[part 8 of 22: package /Cluster]
AUTOSAR XML (schema 4-3-0)
package /Cluster  (continued)
  can cluster E3V_K2CANFD: baudrate=500000, protocol-name=CAN, protocol-version=2.0, bus-off-recovery={bor-counter-l-1-to-l-2=1, bor-time-l-1=0.05, bor-time-l-2=0.2}, can-fd-baudrate=500000  (continued)
    can physical channel CHNL: comm-connectors=CN_E3V_K2CANFD  (continued)
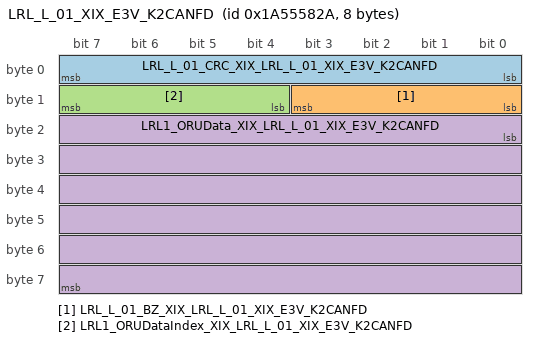
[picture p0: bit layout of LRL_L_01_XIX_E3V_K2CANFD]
      frame LRL_L_01_XIX_E3V_K2CANFD: id 0x1A55582A, to SAM, frame-length=8, can-addressing-mode=EXTENDED, can-frame-rx-behavior=CAN-FD, can-frame-tx-behavior=CAN-FD
        pdu LRL_L_01_XIX_E3V_K2CANFD_E2E: length=8, transmission-mode-true-timing=event-controlled-timing={number-of-repetitions=0, repetition-period=0.0}, unused-bit-pattern=0  # Fuer die Botschaft ist das Cyclic-Timing 0.5 zu verwenden.
          signal LRL_L_01_CRC_XIX_LRL_L_01_XIX_E3V_K2CANFD: start 0, 8 bit, little-endian, data-type-policy=OVERRIDE, i-signal-type=PRIMITIVE, init-value=0, base-type=BT_LRL_L_01_CRC, compu {phys=raw for raw 0..255}, range phys 0..255, raw 0..255, to SAM(timeout 5 s)  # Für MLB: Berechnung siehe Lastenheft "Kommunikationsabsicherung für FlexRay und CAN" Ab MQB und MLBevo: Berechnung siehe Lastenheft "End-to-End Kommunikationsabsicherung" Endwerte siehe Begleitdokument "S-PDU Kennungsfolgen"
          signal LRL_L_01_BZ_XIX_LRL_L_01_XIX_E3V_K2CANFD: start 8, 4 bit, little-endian, data-type-policy=OVERRIDE, i-signal-type=PRIMITIVE, init-value=0, base-type=BT_LRL_L_01_BZ, compu {phys=raw for raw 0..15}, range phys 0..15, raw 0..15, to SAM(timeout 5 s)
          signal LRL1_ORUDataIndex_XIX_LRL_L_01_XIX_E3V_K2CANFD: start 12, 4 bit, little-endian, data-type-policy=OVERRIDE, i-signal-type=PRIMITIVE, init-value=0, base-type=BT_LRL1_ORUDataIndex, compu {phys=raw for raw 0..15}, range phys 0..15, raw 0..15, to SAM(timeout 5 s)  # Data index of the last 6 Bytes
          signal LRL1_ORUData_XIX_LRL_L_01_XIX_E3V_K2CANFD: start 16, 48 bit, little-endian, data-type-policy=OVERRIDE, i-signal-type=PRIMITIVE, init-value=0, base-type=BT_LRL1_ORUData, compu {phys=raw for raw 0..281474976710655}, range phys 0..281474976710655, raw 0..281474976710655, to SAM(timeout 5 s)  # "ORU information multiplexed - diagnostic address (2 bytes) - HW-part no (11 bytes) - HW version no. (3 bytes) - SW version no. (4 bytes) - IVD-P Value (64 bytes) need to be sent in combination with ORUDataIndex"
          mapping SG_LRL_L_01_XIX_E3V_K2CANFD: i-signal-group=SG_LRL_L_01_XIX_E3V_K2CANFD, transfer-property=TRIGGERED-WITHOUT-REPETITION
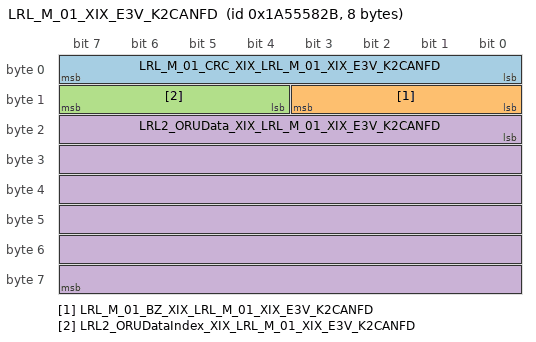
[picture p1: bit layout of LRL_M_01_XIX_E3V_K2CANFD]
      frame LRL_M_01_XIX_E3V_K2CANFD: id 0x1A55582B, to SAM, frame-length=8, can-addressing-mode=EXTENDED, can-frame-rx-behavior=CAN-FD, can-frame-tx-behavior=CAN-FD
        pdu LRL_M_01_XIX_E3V_K2CANFD_E2E: length=8, transmission-mode-true-timing=event-controlled-timing={number-of-repetitions=0, repetition-period=0.0}, unused-bit-pattern=0  # Fuer die Botschaft ist das Cyclic-Timing 0.5 zu verwenden.
          signal LRL_M_01_CRC_XIX_LRL_M_01_XIX_E3V_K2CANFD: start 0, 8 bit, little-endian, data-type-policy=OVERRIDE, i-signal-type=PRIMITIVE, init-value=0, base-type=BT_LRL_M_01_CRC, compu {phys=raw for raw 0..255}, range phys 0..255, raw 0..255, to SAM(timeout 5 s)  # Für MLB: Berechnung siehe Lastenheft "Kommunikationsabsicherung für FlexRay und CAN" Ab MQB und MLBevo: Berechnung siehe Lastenheft "End-to-End Kommunikationsabsicherung" Endwerte siehe Begleitdokument "S-PDU Kennungsfolgen"
          signal LRL_M_01_BZ_XIX_LRL_M_01_XIX_E3V_K2CANFD: start 8, 4 bit, little-endian, data-type-policy=OVERRIDE, i-signal-type=PRIMITIVE, init-value=0, base-type=BT_LRL_M_01_BZ, compu {phys=raw for raw 0..15}, range phys 0..15, raw 0..15, to SAM(timeout 5 s)
          signal LRL2_ORUDataIndex_XIX_LRL_M_01_XIX_E3V_K2CANFD: start 12, 4 bit, little-endian, data-type-policy=OVERRIDE, i-signal-type=PRIMITIVE, init-value=0, base-type=BT_LRL2_ORUDataIndex, compu {phys=raw for raw 0..15}, range phys 0..15, raw 0..15, to SAM(timeout 5 s)  # Data index of the last 6 Bytes
          signal LRL2_ORUData_XIX_LRL_M_01_XIX_E3V_K2CANFD: start 16, 48 bit, little-endian, data-type-policy=OVERRIDE, i-signal-type=PRIMITIVE, init-value=0, base-type=BT_LRL2_ORUData, compu {phys=raw for raw 0..281474976710655}, range phys 0..281474976710655, raw 0..281474976710655, to SAM(timeout 5 s)  # "ORU information multiplexed - diagnostic address (2 bytes) - HW-part no (11 bytes) - HW version no. (3 bytes) - SW version no. (4 bytes) - IVD-P Value (64 bytes) need to be sent in combination with ORUDataIndex"
          mapping SG_LRL_M_01_XIX_E3V_K2CANFD: i-signal-group=SG_LRL_M_01_XIX_E3V_K2CANFD, transfer-property=TRIGGERED-WITHOUT-REPETITION
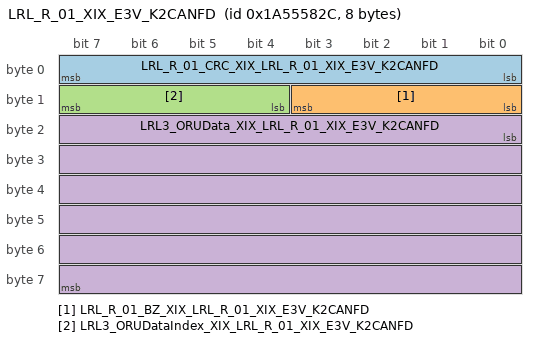
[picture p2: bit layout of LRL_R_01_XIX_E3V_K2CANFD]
      frame LRL_R_01_XIX_E3V_K2CANFD: id 0x1A55582C, to SAM, frame-length=8, can-addressing-mode=EXTENDED, can-frame-rx-behavior=CAN-FD, can-frame-tx-behavior=CAN-FD
        pdu LRL_R_01_XIX_E3V_K2CANFD_E2E: length=8, transmission-mode-true-timing=event-controlled-timing={number-of-repetitions=0, repetition-period=0.0}, unused-bit-pattern=0  # Fuer die Botschaft ist das Cyclic-Timing 0.5 zu verwenden.
          signal LRL_R_01_CRC_XIX_LRL_R_01_XIX_E3V_K2CANFD: start 0, 8 bit, little-endian, data-type-policy=OVERRIDE, i-signal-type=PRIMITIVE, init-value=0, base-type=BT_LRL_R_01_CRC, compu {phys=raw for raw 0..255}, range phys 0..255, raw 0..255, to SAM(timeout 5 s)  # Für MLB: Berechnung siehe Lastenheft "Kommunikationsabsicherung für FlexRay und CAN" Ab MQB und MLBevo: Berechnung siehe Lastenheft "End-to-End Kommunikationsabsicherung" Endwerte siehe Begleitdokument "S-PDU Kennungsfolgen"
          signal LRL_R_01_BZ_XIX_LRL_R_01_XIX_E3V_K2CANFD: start 8, 4 bit, little-endian, data-type-policy=OVERRIDE, i-signal-type=PRIMITIVE, init-value=0, base-type=BT_LRL_R_01_BZ, compu {phys=raw for raw 0..15}, range phys 0..15, raw 0..15, to SAM(timeout 5 s)
          signal LRL3_ORUDataIndex_XIX_LRL_R_01_XIX_E3V_K2CANFD: start 12, 4 bit, little-endian, data-type-policy=OVERRIDE, i-signal-type=PRIMITIVE, init-value=0, base-type=BT_LRL3_ORUDataIndex, compu {phys=raw for raw 0..15}, range phys 0..15, raw 0..15, to SAM(timeout 5 s)  # Data index of the last 6 Bytes
          signal LRL3_ORUData_XIX_LRL_R_01_XIX_E3V_K2CANFD: start 16, 48 bit, little-endian, data-type-policy=OVERRIDE, i-signal-type=PRIMITIVE, init-value=0, base-type=BT_LRL3_ORUData, compu {phys=raw for raw 0..281474976710655}, range phys 0..281474976710655, raw 0..281474976710655, to SAM(timeout 5 s)  # "ORU information multiplexed - diagnostic address (2 bytes) - HW-part no (11 bytes) - HW version no. (3 bytes) - SW version no. (4 bytes) - IVD-P Value (64 bytes) need to be sent in combination with ORUDataIndex"
          mapping SG_LRL_R_01_XIX_E3V_K2CANFD: i-signal-group=SG_LRL_R_01_XIX_E3V_K2CANFD, transfer-property=TRIGGERED-WITHOUT-REPETITION
      frame Mem_BFS_01_XIX_E3V_K2CANFD: id 0x667, to SAM, frame-length=8, can-addressing-mode=STANDARD, can-frame-rx-behavior=CAN-FD, can-frame-tx-behavior=CAN-FD
        pdu Mem_BFS_01_XIX_E3V_K2CANFD: length=8, minimum-delay=0.05, transmission-mode-true-timing={cyclic-timing={time-offset=0.0, time-period=0.1}, event-controlled-timing={number-of-repetitions=0, repetition-period=0.0}}, unused-bit-pattern=0  # MLBevo
          signal BFS_Fond_Bed_Ack_XIX_Mem_BFS_01_XIX_E3V_K2CANFD: start 12, 1 bit, little-endian, data-type-policy=OVERRIDE, i-signal-type=PRIMITIVE, init-value=0, base-type=BT_BFS_Fond_Bed_Ack, compu {0=Cx0_nicht_aktiviert (CM_BFS_Fond_Bed_Ack_Cx0_nicht_aktiviert) (nicht aktiviert), 1=Cx1_aktiviert (CM_BFS_Fond_Bed_Ack_Cx1_aktiviert)}, range raw 0..1, transfer-property=TRIGGERED-ON-CHANGE-WITHOUT-REPETITION  # Bestätigung Beifahrersitzverstellung vom Fond
          signal BFS_Lehne_nicht_verriegelt_XIX_Mem_BFS_01_XIX_E3V_K2CANFD: start 13, 1 bit, little-endian, data-type-policy=OVERRIDE, i-signal-type=PRIMITIVE, init-value=0, base-type=BT_BFS_Lehne_nicht_verriegelt, compu {0=Cx0_keine_Anzeige (CM_BFS_Lehne_nicht_verriegelt_Cx0_keine_Anzeige) (keine Anzeige), 1=Cx1_Lehne_nicht_verriegelt (CM_BFS_Lehne_nicht_verriegelt_Cx1_Lehne_nicht_verriegelt)}, range raw 0..1, transfer-property=TRIGGERED-ON-CHANGE-WITHOUT-REPETITION  # Fahrer Sitz Lehne Verstellung Verriegelt Status Verwendung nur im Bentley
          signal BFS_Klapptisch_offen_XIX_Mem_BFS_01_XIX_E3V_K2CANFD: start 14, 1 bit, little-endian, data-type-policy=OVERRIDE, i-signal-type=PRIMITIVE, init-value=0, base-type=BT_BFS_Klapptisch_offen, compu {0=Cx0_inaktiv (CM_BFS_Klapptisch_offen_Cx0_inaktiv), 1=Cx1_aktiv (CM_BFS_Klapptisch_offen_Cx1_aktiv)}, range raw 0..1, transfer-property=TRIGGERED-ON-CHANGE-WITHOUT-REPETITION  # Signalisiert eine Verstelleinschränkung des Beifahrersitz (für BAP Visualisierung)
          signal BFS_Gurtbringer_Sperre_XIX_Mem_BFS_01_XIX_E3V_K2CANFD: start 15, 1 bit, little-endian, data-type-policy=OVERRIDE, i-signal-type=PRIMITIVE, init-value=0, base-type=BT_BFS_Gurtbringer_Sperre, compu {0=Cx0_Gurtzubringer_freigegeben (CM_BFS_Gurtbringer_Sperre_Cx0_Gurtzubringer_freigegeben), 1=Cx1_Gurtzubringer_gesperrt (CM_BFS_Gurtbringer_Sperre_Cx1_Gurtzubringer_gesperrt)}, range raw 0..1, transfer-property=PENDING  # Freigabesignal für den Gurtzubringer
          signal BFS_Sitzsym_Fahrt_aktiv_XIX_Mem_BFS_01_XIX_E3V_K2CANFD: start 16, 1 bit, little-endian, data-type-policy=OVERRIDE, i-signal-type=PRIMITIVE, init-value=0, base-type=BT_BFS_Sitzsym_Fahrt_aktiv, compu {0=Cx0_inaktiv (CM_BFS_Sitzsym_Fahrt_aktiv_Cx0_inaktiv), 1=Cx1_aktiv (CM_BFS_Sitzsym_Fahrt_aktiv_Cx1_aktiv)}, range raw 0..1, transfer-property=TRIGGERED-ON-CHANGE-WITHOUT-REPETITION  # Sitzsymetriefahrt
          signal BFS_Sitzfahrt_aktiv_XIX_Mem_BFS_01_XIX_E3V_K2CANFD: start 17, 1 bit, little-endian, data-type-policy=OVERRIDE, i-signal-type=PRIMITIVE, init-value=0, base-type=BT_BFS_Sitzfahrt_aktiv, compu {0=Cx0_Init (CM_BFS_Sitzfahrt_aktiv_Cx0_Init), 1=Cx1_Sitz_in_Bewegung (CM_BFS_Sitzfahrt_aktiv_Cx1_Sitz_in_Bewegung) (Sitz in Bewegung)}, range raw 0..1, transfer-property=TRIGGERED-ON-CHANGE-WITHOUT-REPETITION  # Aktive Sitzfahrt
          signal BFS_SLV_aktiv_XIX_Mem_BFS_01_XIX_E3V_K2CANFD: start 18, 1 bit, little-endian, data-type-policy=OVERRIDE, i-signal-type=PRIMITIVE, init-value=0, base-type=BT_BFS_SLV_aktiv, compu {0=Cx0_nicht_aktiv (CM_BFS_SLV_aktiv_Cx0_nicht_aktiv), 1=Cx1_Sitzlaengsverstellung_aktiv (CM_BFS_SLV_aktiv_Cx1_Sitzlaengsverstellung_aktiv) (Sitzlaengsverstellung aktiv)}, range raw 0..1, transfer-property=TRIGGERED-ON-CHANGE-WITHOUT-REPETITION  # Sitzlängsverstellung
          signal BFS_SHV_aktiv_XIX_Mem_BFS_01_XIX_E3V_K2CANFD: start 19, 1 bit, little-endian, data-type-policy=OVERRIDE, i-signal-type=PRIMITIVE, init-value=0, base-type=BT_BFS_SHV_aktiv, compu {0=Cx0_nicht_aktiv (CM_BFS_SHV_aktiv_Cx0_nicht_aktiv), 1=Cx1_Sitzhoehenverstellung_aktiv (CM_BFS_SHV_aktiv_Cx1_Sitzhoehenverstellung_aktiv) (Sitzhoehenverstellung aktiv)}, range raw 0..1, transfer-property=TRIGGERED-ON-CHANGE-WITHOUT-REPETITION  # Sitzhöhenverstellung
          signal BFS_LNV_aktiv_XIX_Mem_BFS_01_XIX_E3V_K2CANFD: start 20, 1 bit, little-endian, data-type-policy=OVERRIDE, i-signal-type=PRIMITIVE, init-value=0, base-type=BT_BFS_LNV_aktiv, compu {0=Cx0_inaktiv (CM_BFS_LNV_aktiv_Cx0_inaktiv), 1=Cx1_aktiv (CM_BFS_LNV_aktiv_Cx1_aktiv)}, range raw 0..1, transfer-property=TRIGGERED-ON-CHANGE-WITHOUT-REPETITION  # Verstellung Lehnenneigung
          signal BFS_SNV_aktiv_XIX_Mem_BFS_01_XIX_E3V_K2CANFD: start 21, 1 bit, little-endian, data-type-policy=OVERRIDE, i-signal-type=PRIMITIVE, init-value=0, base-type=BT_BFS_SNV_aktiv, compu {0=Cx0_nicht_aktiv (CM_BFS_SNV_aktiv_Cx0_nicht_aktiv), 1=Cx1_Sitzneigungsverstellung_aktiv (CM_BFS_SNV_aktiv_Cx1_Sitzneigungsverstellung_aktiv) (Sitzneigungsverstellung aktiv)}, range raw 0..1, transfer-property=TRIGGERED-ON-CHANGE-WITHOUT-REPETITION  # Verstellung Sitzneigung
          signal BFS_KSV_aktiv_XIX_Mem_BFS_01_XIX_E3V_K2CANFD: start 22, 1 bit, little-endian, data-type-policy=OVERRIDE, i-signal-type=PRIMITIVE, init-value=0, base-type=BT_BFS_KSV_aktiv, compu {0=Cx0_nicht_aktiv (CM_BFS_KSV_aktiv_Cx0_nicht_aktiv), 1=Cx1_Kopfstuetzenverstellung_aktiv (CM_BFS_KSV_aktiv_Cx1_Kopfstuetzenverstellung_aktiv) (Kopfstuetzenverstellung aktiv)}, range raw 0..1, transfer-property=TRIGGERED-ON-CHANGE-WITHOUT-REPETITION  # Kopfstuetzenverstellung BFS
          signal BFS_LKV_aktiv_XIX_Mem_BFS_01_XIX_E3V_K2CANFD: start 23, 1 bit, little-endian, data-type-policy=OVERRIDE, i-signal-type=PRIMITIVE, init-value=0, base-type=BT_BFS_LKV_aktiv, compu {0=Cx0_nicht_aktiv (CM_BFS_LKV_aktiv_Cx0_nicht_aktiv), 1=Cx1_aktiv (CM_BFS_LKV_aktiv_Cx1_aktiv)}, range raw 0..1, transfer-property=TRIGGERED-ON-CHANGE-WITHOUT-REPETITION  # Verstellung Lehnenkopf
          signal BFS_STV_aktiv_XIX_Mem_BFS_01_XIX_E3V_K2CANFD: start 24, 1 bit, little-endian, data-type-policy=OVERRIDE, i-signal-type=PRIMITIVE, init-value=0, base-type=BT_BFS_STV_aktiv, compu {0=Cx0_inaktiv (CM_BFS_STV_aktiv_Cx0_inaktiv), 1=Cx1_Sitztiefeverstellung_aktiv (CM_BFS_STV_aktiv_Cx1_Sitztiefeverstellung_aktiv) (Sitztiefeverstellung aktiv)}, range raw 0..1, transfer-property=TRIGGERED-ON-CHANGE-WITHOUT-REPETITION  # Sitztiefeverstellung
          signal BFS_LHV_aktiv_XIX_Mem_BFS_01_XIX_E3V_K2CANFD: start 25, 1 bit, little-endian, data-type-policy=OVERRIDE, i-signal-type=PRIMITIVE, init-value=0, base-type=BT_BFS_LHV_aktiv, compu {0=Cx0_inaktiv (CM_BFS_LHV_aktiv_Cx0_inaktiv), 1=Cx1_aktiv (CM_BFS_LHV_aktiv_Cx1_aktiv)}, range raw 0..1, transfer-property=TRIGGERED-ON-CHANGE-WITHOUT-REPETITION  # Verstellung Lordose Höhe
          signal BFS_LWV_aktiv_XIX_Mem_BFS_01_XIX_E3V_K2CANFD: start 26, 1 bit, little-endian, data-type-policy=OVERRIDE, i-signal-type=PRIMITIVE, init-value=0, base-type=BT_BFS_LWV_aktiv, compu {0=Cx0_nicht_aktiv (CM_BFS_LWV_aktiv_Cx0_nicht_aktiv), 1=Cx1_aktiv (CM_BFS_LWV_aktiv_Cx1_aktiv)}, range raw 0..1, transfer-property=TRIGGERED-ON-CHANGE-WITHOUT-REPETITION  # Lordose W Verstellung
          signal BFS_GHV_aktiv_XIX_Mem_BFS_01_XIX_E3V_K2CANFD: start 27, 1 bit, little-endian, data-type-policy=OVERRIDE, i-signal-type=PRIMITIVE, init-value=0, base-type=BT_BFS_GHV_aktiv, compu {0=Cx0_nicht_aktiv (CM_BFS_GHV_aktiv_Cx0_nicht_aktiv), 1=Cx1_Gurthoehe_Verstellung_aktiv (CM_BFS_GHV_aktiv_Cx1_Gurthoehe_Verstellung_aktiv) (Gurthoehe Verstellung aktiv)}, range raw 0..1, transfer-property=TRIGGERED-ON-CHANGE-WITHOUT-REPETITION  # Verstellung Gurthoehe
          signal BFS_KSS_Fahrt_aktiv_XIX_Mem_BFS_01_XIX_E3V_K2CANFD: start 28, 1 bit, little-endian, data-type-policy=OVERRIDE, i-signal-type=PRIMITIVE, init-value=0, base-type=BT_BFS_KSS_Fahrt_aktiv, compu {0=Cx0_nicht_aktiv (CM_BFS_KSS_Fahrt_aktiv_Cx0_nicht_aktiv), 1=Cx1_Komfortseitensichtfahrt_aktiv (CM_BFS_KSS_Fahrt_aktiv_Cx1_Komfortseitensichtfahrt_aktiv) (Komfortseitensichtfahrt aktiv)}, range raw 0..1, transfer-property=TRIGGERED-ON-CHANGE-WITHOUT-REPETITION  # Komfortseitensichtfahrt (BFS)
          signal BFS_MMB_lokal_Stop_XIX_Mem_BFS_01_XIX_E3V_K2CANFD: start 29, 1 bit, little-endian, data-type-policy=OVERRIDE, i-signal-type=PRIMITIVE, init-value=0, base-type=BT_BFS_MMB_lokal_Stop, compu {0=Cx0_kein_Abbruch (CM_BFS_MMB_lokal_Stop_Cx0_kein_Abbruch), 1=Cx1_lokaler_Abbruch (CM_BFS_MMB_lokal_Stop_Cx1_lokaler_Abbruch)}, range raw 0..1, transfer-property=TRIGGERED-ON-CHANGE-WITHOUT-REPETITION  # mit dem lokal Stop moechte man, dass ein Sitz mit Pneumatik - Lordose sich im Memoryfall wie ein Sitz mit elektromechanischer Lordose verhaelt. Nur lokler Abbruch im TIP-Betrieb.
          signal BFS_Ruhestellung_Status_XIX_Mem_BFS_01_XIX_E3V_K2CANFD: start 30, 1 bit, little-endian, data-type-policy=OVERRIDE, i-signal-type=PRIMITIVE, init-value=0, base-type=BT_BFS_Ruhestellung_Status, compu {0=Cx0_inakiv (CM_BFS_Ruhestellung_Status_Cx0_inakiv), 1=Cx1_Ruhestellung_aktiv (CM_BFS_Ruhestellung_Status_Cx1_Ruhestellung_aktiv)}, range raw 0..1, transfer-property=TRIGGERED-ON-CHANGE-WITHOUT-REPETITION  # dient der Signalisierung für eine Verstelleinschränkung, da der Sitz sich in Ruhestellung befindet.
          signal BFS_Seat_Locked_XIX_Mem_BFS_01_XIX_E3V_K2CANFD: start 31, 1 bit, little-endian, data-type-policy=OVERRIDE, i-signal-type=PRIMITIVE, init-value=0, base-type=BT_BFS_Seat_Locked, compu {0=Cx0_nicht_gesperrt (CM_BFS_Seat_Locked_Cx0_nicht_gesperrt), 1=Cx1_gesperrt (CM_BFS_Seat_Locked_Cx1_gesperrt)}, range raw 0..1, transfer-property=PENDING  # Anzeige des gesperrten Beifahrersitzes aufgrund ungültiger Sitzposition.
          signal BFS_MMB_storage_XIX_Mem_BFS_01_XIX_E3V_K2CANFD: start 32, 4 bit, little-endian, data-type-policy=OVERRIDE, i-signal-type=PRIMITIVE, init-value=0, base-type=BT_BFS_MMB_storage, compu {0=Cx0_keine_Zuweisung (CM_BFS_MMB_storage_Cx0_keine_Zuweisung) (keine Zuweisung), 1=Cx1_P1_FP1_Pos_Zuweisung (CM_BFS_MMB_storage_Cx1_P1_FP1_Pos_Zuweisung) (P1/FP1 Pos Zuweisung), 2=Cx2_P2_FP2_Pos_Zuweisung (CM_BFS_MMB_storage_Cx2_P2_FP2_Pos_Zuweisung) (P2/FP2 Pos Zuweisung), 3=Cx3_P3_FP3_Pos_Zuweisung (CM_BFS_MMB_storage_Cx3_P3_FP3_Pos_Zuweisung) (P3/FP3 Pos Zuweisung), 4=Cx4_P4_FP4_Pos_Zuweisung_an_den_im_System_aktiven_Funkschluessel_FPI_ID_ueber_MMI (CM_BFS_MMB_storage_Cx4_P4_FP4_Pos_Zuweisung_an_den_im_System_aktiven_Funkschluessel_FPI_ID_ueber_MMI) (P4/FP4 Pos Zuweisung an den im System aktiven Funkschlüssel/FPI ID über MMI), 5=Cx5_FS1 (CM_BFS_MMB_storage_Cx5_FS1), 6=Cx6_FS2 (CM_BFS_MMB_storage_Cx6_FS2), 7=Cx7_FS3 (CM_BFS_MMB_storage_Cx7_FS3), 8=Cx8_FS4 (CM_BFS_MMB_storage_Cx8_FS4)}, range raw 0..8, transfer-property=TRIGGERED-ON-CHANGE-WITHOUT-REPETITION, to SAM(timeout 1 s)  # Speichern auf Memoryposition
          signal BFS_MMB_tipp_XIX_Mem_BFS_01_XIX_E3V_K2CANFD: start 36, 1 bit, little-endian, data-type-policy=OVERRIDE, i-signal-type=PRIMITIVE, init-value=0, base-type=BT_BFS_MMB_tipp, compu {0=Cx0_kein_Tippbetrieb (CM_BFS_MMB_tipp_Cx0_kein_Tippbetrieb), 1=Cx1_Tippbetrieb (CM_BFS_MMB_tipp_Cx1_Tippbetrieb)}, range raw 0..1, transfer-property=TRIGGERED-ON-CHANGE-WITHOUT-REPETITION, to SAM(timeout 1 s)  # Memoryverstellung im Tippbetrieb
          signal BFS_MMB_tast_XIX_Mem_BFS_01_XIX_E3V_K2CANFD: start 37, 1 bit, little-endian, data-type-policy=OVERRIDE, i-signal-type=PRIMITIVE, init-value=0, base-type=BT_BFS_MMB_tast, compu {0=Cx0_kein_Tastbetrieb (CM_BFS_MMB_tast_Cx0_kein_Tastbetrieb), 1=Cx1_Tastbetrieb (CM_BFS_MMB_tast_Cx1_Tastbetrieb)}, range raw 0..1, transfer-property=TRIGGERED-ON-CHANGE-WITHOUT-REPETITION, to SAM(timeout 1 s)  # Memoryverstellung im Tastbetrieb
          signal BFS_MMB_store_LED_on_XIX_Mem_BFS_01_XIX_E3V_K2CANFD: start 38, 1 bit, little-endian, data-type-policy=OVERRIDE, i-signal-type=PRIMITIVE, init-value=0, base-type=BT_BFS_MMB_store_LED_on, compu {0=Cx0_LED_aus (CM_BFS_MMB_store_LED_on_Cx0_LED_aus), 1=Cx1_LED_ein (CM_BFS_MMB_store_LED_on_Cx1_LED_ein)}, range raw 0..1, transfer-property=TRIGGERED-ON-CHANGE-WITHOUT-REPETITION  # LED für Speichern
          signal BFS_MMB_storage_beep_XIX_Mem_BFS_01_XIX_E3V_K2CANFD: start 39, 1 bit, little-endian, data-type-policy=OVERRIDE, i-signal-type=PRIMITIVE, init-value=0, base-type=BT_BFS_MMB_storage_beep, compu {0=Cx0_beep_aus (CM_BFS_MMB_storage_beep_Cx0_beep_aus), 1=Cx1_beep_ein (CM_BFS_MMB_storage_beep_Cx1_beep_ein) (beep ein)}, range raw 0..1, transfer-property=TRIGGERED-ON-CHANGE-WITHOUT-REPETITION  # Quittierungston Sitzmemory BFS (Anforderung Kombi)
          signal BFS_MMB_store_XIX_Mem_BFS_01_XIX_E3V_K2CANFD: start 40, 1 bit, little-endian, data-type-policy=OVERRIDE, i-signal-type=PRIMITIVE, init-value=0, base-type=BT_BFS_MMB_store, compu {0=Cx0_nicht_speichern (CM_BFS_MMB_store_Cx0_nicht_speichern) (nicht speichern), 1=Cx1_speichern (CM_BFS_MMB_store_Cx1_speichern)}, range raw 0..1, transfer-property=TRIGGERED-ON-CHANGE-WITHOUT-REPETITION  # Speichern der Sitzposition
          signal BFS_MMB_glob_stop_XIX_Mem_BFS_01_XIX_E3V_K2CANFD: start 41, 1 bit, little-endian, data-type-policy=OVERRIDE, i-signal-type=PRIMITIVE, init-value=0, base-type=BT_BFS_MMB_glob_stop, compu {0=Cx0_kein_globaler_Abbruch (CM_BFS_MMB_glob_stop_Cx0_kein_globaler_Abbruch) (kein globaler Abbruch), 1=Cx1_globaler_Abbruch (CM_BFS_MMB_glob_stop_Cx1_globaler_Abbruch) (globaler Abbruch)}, range raw 0..1, transfer-property=TRIGGERED-ON-CHANGE-WITHOUT-REPETITION, to SAM(timeout 1 s)  # Abbruch Memoryverstellung
          signal BFS_FSV_ausgeklappt_XIX_Mem_BFS_01_XIX_E3V_K2CANFD: start 42, 1 bit, little-endian, data-type-policy=OVERRIDE, i-signal-type=PRIMITIVE, init-value=0, base-type=BT_BFS_FSV_ausgeklappt, compu {0=Cx0_FSV_nicht_ausgeklappt (CM_BFS_FSV_ausgeklappt_Cx0_FSV_nicht_ausgeklappt), 1=Cx1_FSV_ausgeklappt (CM_BFS_FSV_ausgeklappt_Cx1_FSV_ausgeklappt)}, range raw 0..1, transfer-property=PENDING  # Zustandssignalisierung der el. mech. Fußstütze (eingeklappt oder ausgeklappt)
      frame Mem_FS_01_XIX_E3V_K2CANFD: id 0x49A, to SAM, frame-length=8, can-addressing-mode=STANDARD, can-frame-rx-behavior=CAN-FD, can-frame-tx-behavior=CAN-FD
        pdu Mem_FS_01_XIX_E3V_K2CANFD: length=8, minimum-delay=0.05, transmission-mode-true-timing={cyclic-timing={time-offset=0.0, time-period=0.1}, event-controlled-timing={number-of-repetitions=0, repetition-period=0.0}}, unused-bit-pattern=0  # ab MQB 7.2
          signal FS_Fond_Bed_enable_XIX_Mem_FS_01_XIX_E3V_K2CANFD: start 12, 1 bit, little-endian, data-type-policy=OVERRIDE, i-signal-type=PRIMITIVE, init-value=0, base-type=BT_FS_Fond_Bed_enable, compu {0=Cx0_disable (CM_FS_Fond_Bed_enable_Cx0_disable), 1=Cx1_enable (CM_FS_Fond_Bed_enable_Cx1_enable)}, range raw 0..1, transfer-property=TRIGGERED-ON-CHANGE-WITHOUT-REPETITION  # Freigabe für Fondsitzverstellungen
          signal FS_Lehne_nicht_verriegelt_XIX_Mem_FS_01_XIX_E3V_K2CANFD: start 13, 1 bit, little-endian, data-type-policy=OVERRIDE, i-signal-type=PRIMITIVE, init-value=0, base-type=BT_FS_Lehne_nicht_verriegelt, compu {0=Cx0_keine_Anzeige (CM_FS_Lehne_nicht_verriegelt_Cx0_keine_Anzeige) (keine Anzeige), 1=Cx1_Lehne_nicht_verriegelt (CM_FS_Lehne_nicht_verriegelt_Cx1_Lehne_nicht_verriegelt)}, range raw 0..1, transfer-property=TRIGGERED-ON-CHANGE-WITHOUT-REPETITION  # Fahrer Sitz Lehne Verstellung Verriegelt Status Verwendung nur im Bentley
          signal FS_Spezialposition_anfahren_XIX_Mem_FS_01_XIX_E3V_K2CANFD: start 14, 1 bit, little-endian, data-type-policy=OVERRIDE, i-signal-type=PRIMITIVE, init-value=0, base-type=BT_FS_Spezialposition_anfahren, compu {0=Cx0_Fkt_inaktiv (CM_FS_Spezialposition_anfahren_Cx0_Fkt_inaktiv), 1=Cx1_Fkt_aktiv (CM_FS_Spezialposition_anfahren_Cx1_Fkt_aktiv)}, range raw 0..1, transfer-property=TRIGGERED-ON-CHANGE-WITHOUT-REPETITION  # paralell zu diesem Signal wird eine Botschaft auf den KCAN gesendet in der spezielle Anforderungen für den Empfänger stehen. Dieses Signal dient zusätzlich der Checksummenabsicherung bei einer Remotverstellung
          signal FS_Gurtbringer_Sperre_XIX_Mem_FS_01_XIX_E3V_K2CANFD: start 15, 1 bit, little-endian, data-type-policy=OVERRIDE, i-signal-type=PRIMITIVE, init-value=0, base-type=BT_FS_Gurtbringer_Sperre, compu {0=Cx0_Gurtzubringer_freigegeben (CM_FS_Gurtbringer_Sperre_Cx0_Gurtzubringer_freigegeben), 1=Cx1_Gurtzubringer_gesperrt (CM_FS_Gurtbringer_Sperre_Cx1_Gurtzubringer_gesperrt)}, range raw 0..1, transfer-property=PENDING  # Freigabesignal für den Gurtzubringer
          signal FS_BFS_Sitzsym_Anfahrt_XIX_Mem_FS_01_XIX_E3V_K2CANFD: start 16, 1 bit, little-endian, data-type-policy=OVERRIDE, i-signal-type=PRIMITIVE, init-value=0, base-type=BT_FS_BFS_Sitzsym_Anfahrt, compu {0=Cx0_keine_Sitzsymetrie_Anfahrt_BFS (CM_FS_BFS_Sitzsym_Anfahrt_Cx0_keine_Sitzsymetrie_Anfahrt_BFS) (keine Sitzsymetrie Anfahrt BFS), 1=Cx1_Sitzsymetrie_Anfahrt_BFS (CM_FS_BFS_Sitzsym_Anfahrt_Cx1_Sitzsymetrie_Anfahrt_BFS) (Sitzsymetrie Anfahrt BFS)}, range raw 0..1, transfer-property=TRIGGERED-ON-CHANGE-WITHOUT-REPETITION  # Sitzsymetrie Anfahrt BFS
          signal FS_Sitzfahrt_aktiv_XIX_Mem_FS_01_XIX_E3V_K2CANFD: start 17, 1 bit, little-endian, data-type-policy=OVERRIDE, i-signal-type=PRIMITIVE, init-value=0, base-type=BT_FS_Sitzfahrt_aktiv, compu {0=Cx0_Sitz_nicht_in_Bewegung (CM_FS_Sitzfahrt_aktiv_Cx0_Sitz_nicht_in_Bewegung), 1=Cx1_Sitz_in_Bewegung (CM_FS_Sitzfahrt_aktiv_Cx1_Sitz_in_Bewegung)}, range raw 0..1, transfer-property=TRIGGERED-ON-CHANGE-WITHOUT-REPETITION  # Aktive Sitzfahrt Fahrersitz
          signal FS_SLV_aktiv_XIX_Mem_FS_01_XIX_E3V_K2CANFD: start 18, 1 bit, little-endian, data-type-policy=OVERRIDE, i-signal-type=PRIMITIVE, init-value=0, base-type=BT_FS_SLV_aktiv, compu {0=Cx0_nicht_aktiv (CM_FS_SLV_aktiv_Cx0_nicht_aktiv), 1=Cx1_Sitzlaengsverstellung_aktiv (CM_FS_SLV_aktiv_Cx1_Sitzlaengsverstellung_aktiv) (Sitzlaengsverstellung aktiv)}, range raw 0..1, transfer-property=TRIGGERED-ON-CHANGE-WITHOUT-REPETITION  # Sitzlängsverstellung
          signal FS_SHV_aktiv_XIX_Mem_FS_01_XIX_E3V_K2CANFD: start 19, 1 bit, little-endian, data-type-policy=OVERRIDE, i-signal-type=PRIMITIVE, init-value=0, base-type=BT_FS_SHV_aktiv, compu {0=Cx0_nicht_aktiv (CM_FS_SHV_aktiv_Cx0_nicht_aktiv), 1=Cx1_Sitzhoehenverstellung_aktiv (CM_FS_SHV_aktiv_Cx1_Sitzhoehenverstellung_aktiv) (Sitzhoehenverstellung aktiv)}, range raw 0..1, transfer-property=TRIGGERED-ON-CHANGE-WITHOUT-REPETITION  # Verstellung Sitzhöhe
          signal FS_LNV_aktiv_XIX_Mem_FS_01_XIX_E3V_K2CANFD: start 20, 1 bit, little-endian, data-type-policy=OVERRIDE, i-signal-type=PRIMITIVE, init-value=0, base-type=BT_FS_LNV_aktiv, compu {0=Cx0_nicht_aktiv (CM_FS_LNV_aktiv_Cx0_nicht_aktiv), 1=Cx1_Lehnenneigungverstellung_aktiv (CM_FS_LNV_aktiv_Cx1_Lehnenneigungverstellung_aktiv) (Lehnenneigungverstellung aktiv)}, range raw 0..1, transfer-property=TRIGGERED-ON-CHANGE-WITHOUT-REPETITION  # Verstellung Lehnenneigung
          signal FS_SNV_aktiv_XIX_Mem_FS_01_XIX_E3V_K2CANFD: start 21, 1 bit, little-endian, data-type-policy=OVERRIDE, i-signal-type=PRIMITIVE, init-value=0, base-type=BT_FS_SNV_aktiv, compu {0=Cx0_nicht_aktiv (CM_FS_SNV_aktiv_Cx0_nicht_aktiv), 1=Cx1_Sitzneigungsverstellung_aktiv (CM_FS_SNV_aktiv_Cx1_Sitzneigungsverstellung_aktiv)}, range raw 0..1, transfer-property=TRIGGERED-ON-CHANGE-WITHOUT-REPETITION  # Verstellung Sitzneigung
          signal FS_KSV_aktiv_XIX_Mem_FS_01_XIX_E3V_K2CANFD: start 22, 1 bit, little-endian, data-type-policy=OVERRIDE, i-signal-type=PRIMITIVE, init-value=0, base-type=BT_FS_KSV_aktiv, compu {0=Cx0_nicht_aktiv (CM_FS_KSV_aktiv_Cx0_nicht_aktiv), 1=Cx1_Kopfstuetzenverstellung_aktiv (CM_FS_KSV_aktiv_Cx1_Kopfstuetzenverstellung_aktiv) (Kopfstuetzenverstellung aktiv)}, range raw 0..1, transfer-property=TRIGGERED-ON-CHANGE-WITHOUT-REPETITION  # Verstellung Kopfstütze
          signal FS_LKV_aktiv_XIX_Mem_FS_01_XIX_E3V_K2CANFD: start 23, 1 bit, little-endian, data-type-policy=OVERRIDE, i-signal-type=PRIMITIVE, init-value=0, base-type=BT_FS_LKV_aktiv, compu {0=Cx0_nicht_aktiv (CM_FS_LKV_aktiv_Cx0_nicht_aktiv), 1=Cx1_Lehnenkopfverstellung_aktiv (CM_FS_LKV_aktiv_Cx1_Lehnenkopfverstellung_aktiv) (Lehnenkopfverstellung aktiv)}, range raw 0..1, transfer-property=TRIGGERED-ON-CHANGE-WITHOUT-REPETITION  # Verstellung Lehnenkopf
          signal FS_STV_aktiv_XIX_Mem_FS_01_XIX_E3V_K2CANFD: start 24, 1 bit, little-endian, data-type-policy=OVERRIDE, i-signal-type=PRIMITIVE, init-value=0, base-type=BT_FS_STV_aktiv, compu {0=Cx0_nicht_aktiv (CM_FS_STV_aktiv_Cx0_nicht_aktiv), 1=Cx1_Sitztiefeverstellung_aktiv (CM_FS_STV_aktiv_Cx1_Sitztiefeverstellung_aktiv) (Sitztiefeverstellung aktiv)}, range raw 0..1, transfer-property=TRIGGERED-ON-CHANGE-WITHOUT-REPETITION  # Verstellung Sitztiefe
          signal FS_LHV_aktiv_XIX_Mem_FS_01_XIX_E3V_K2CANFD: start 25, 1 bit, little-endian, data-type-policy=OVERRIDE, i-signal-type=PRIMITIVE, init-value=0, base-type=BT_FS_LHV_aktiv, compu {0=Cx0_nicht_aktiv (CM_FS_LHV_aktiv_Cx0_nicht_aktiv), 1=Cx1_Lordose_Hoehe_Verstellung_aktiv (CM_FS_LHV_aktiv_Cx1_Lordose_Hoehe_Verstellung_aktiv) (Lordose Höhe Verstellung aktiv)}, range raw 0..1, transfer-property=TRIGGERED-ON-CHANGE-WITHOUT-REPETITION  # Verstellung Lordose Höhe
          signal FS_LWV_aktiv_XIX_Mem_FS_01_XIX_E3V_K2CANFD: start 26, 1 bit, little-endian, data-type-policy=OVERRIDE, i-signal-type=PRIMITIVE, init-value=0, base-type=BT_FS_LWV_aktiv, compu {0=Cx0_nicht_aktiv (CM_FS_LWV_aktiv_Cx0_nicht_aktiv), 1=Cx1_Lordose_W_Verstellung_aktiv (CM_FS_LWV_aktiv_Cx1_Lordose_W_Verstellung_aktiv) (Lordose W Verstellung aktiv)}, range raw 0..1, transfer-property=TRIGGERED-ON-CHANGE-WITHOUT-REPETITION  # Verstellung Lordose W
          signal FS_GHV_aktiv_XIX_Mem_FS_01_XIX_E3V_K2CANFD: start 27, 1 bit, little-endian, data-type-policy=OVERRIDE, i-signal-type=PRIMITIVE, init-value=0, base-type=BT_FS_GHV_aktiv, compu {0=Cx0_nicht_aktiv (CM_FS_GHV_aktiv_Cx0_nicht_aktiv), 1=Cx1_Gurthoehenverstellung_aktiv (CM_FS_GHV_aktiv_Cx1_Gurthoehenverstellung_aktiv) (Gurthoehenverstellung aktiv)}, range raw 0..1, transfer-property=TRIGGERED-ON-CHANGE-WITHOUT-REPETITION  # Verstellung Gurthöhe
          signal FS_BFS_KSS_Anfahrt_XIX_Mem_FS_01_XIX_E3V_K2CANFD: start 28, 1 bit, little-endian, data-type-policy=OVERRIDE, i-signal-type=PRIMITIVE, init-value=0, base-type=BT_FS_BFS_KSS_Anfahrt, compu {0=Cx0_keine_Anfahrt_KSS_BFS (CM_FS_BFS_KSS_Anfahrt_Cx0_keine_Anfahrt_KSS_BFS) (keine Anfahrt KSS BFS), 1=Cx1_Anfahrt_KSS_BFS (CM_FS_BFS_KSS_Anfahrt_Cx1_Anfahrt_KSS_BFS) (Anfahrt KSS BFS)}, range raw 0..1, transfer-property=TRIGGERED-ON-CHANGE-WITHOUT-REPETITION  # Komfortseitensicht Anfahrt BFS
          signal FS_MMB_lokal_Stop_XIX_Mem_FS_01_XIX_E3V_K2CANFD: start 29, 1 bit, little-endian, data-type-policy=OVERRIDE, i-signal-type=PRIMITIVE, init-value=0, base-type=BT_FS_MMB_lokal_Stop, compu {0=Cx0_kein_Abbruch (CM_FS_MMB_lokal_Stop_Cx0_kein_Abbruch), 1=Cx1_lokaler_Abbruch (CM_FS_MMB_lokal_Stop_Cx1_lokaler_Abbruch)}, range raw 0..1, transfer-property=TRIGGERED-ON-CHANGE-WITHOUT-REPETITION  # mit dem lokal Stop moechte man, dass ein Sitz mit Pneumatik - Lordose sich im Memoryfall wie ein Sitz mit elektromechanischer Lordose verhaelt. Nur lokler Abbruch im TIP-Betrieb.
          signal FS_MMB_storage_XIX_Mem_FS_01_XIX_E3V_K2CANFD: start 32, 4 bit, little-endian, data-type-policy=OVERRIDE, i-signal-type=PRIMITIVE, init-value=0, base-type=BT_FS_MMB_storage, compu {0=Cx0_keine_Zuweisung (CM_FS_MMB_storage_Cx0_keine_Zuweisung), 1=Cx1_P1_FP1_Pos_Zuweisung (CM_FS_MMB_storage_Cx1_P1_FP1_Pos_Zuweisung), 2=Cx2_P2_FP2_Pos_Zuweisung (CM_FS_MMB_storage_Cx2_P2_FP2_Pos_Zuweisung), 3=Cx3_P3_FP3_Pos_Zuweisung (CM_FS_MMB_storage_Cx3_P3_FP3_Pos_Zuweisung), 4=Cx4_P4_FP4_Pos_Zuweisung (CM_FS_MMB_storage_Cx4_P4_FP4_Pos_Zuweisung), 5=Cx5_FS1_bzw_Benutzerkonto_1 (CM_FS_MMB_storage_Cx5_FS1_bzw_Benutzerkonto_1), 6=Cx6_FS2_bzw_Benutzerkonto_2 (CM_FS_MMB_storage_Cx6_FS2_bzw_Benutzerkonto_2), 7=Cx7_FS3_bzw_Benutzerkonto_3 (CM_FS_MMB_storage_Cx7_FS3_bzw_Benutzerkonto_3), 8=Cx8_FS4_bzw_Benutzerkonto_4 (CM_FS_MMB_storage_Cx8_FS4_bzw_Benutzerkonto_4), 9=Cx9_FS5_bzw_Benutzerkonto_5 (CM_FS_MMB_storage_Cx9_FS5_bzw_Benutzerkonto_5), 10=Cxa_FS6_bzw_Benutzerkonto_6 (CM_FS_MMB_storage_Cxa_FS6_bzw_Benutzerkonto_6), 11=Cxb_FS7_bzw_Benutzerkonto_7 (CM_FS_MMB_storage_Cxb_FS7_bzw_Benutzerkonto_7)}, range raw 0..11, transfer-property=TRIGGERED-ON-CHANGE-WITHOUT-REPETITION, to SAM(timeout 1 s)  # Memory-Positionstaste, Funkschlüssel-Memory-ID, Benutzerkonto-Nummer
          signal FS_MMB_tipp_XIX_Mem_FS_01_XIX_E3V_K2CANFD: start 36, 1 bit, little-endian, data-type-policy=OVERRIDE, i-signal-type=PRIMITIVE, init-value=0, base-type=BT_FS_MMB_tipp, compu {0=Cx0_kein_Tippbetrieb (CM_FS_MMB_tipp_Cx0_kein_Tippbetrieb), 1=Cx1_Tippbetrieb_automatisches_Funks (CM_FS_MMB_tipp_Cx1_Tippbetrieb_automatisches_Funks) (Tippbetrieb__automatisches_Funks)}, range raw 0..1, transfer-property=TRIGGERED-ON-CHANGE-WITHOUT-REPETITION, to SAM(timeout 1 s)  # Memoryverstellung im Tippbetrieb
          signal FS_MMB_tast_XIX_Mem_FS_01_XIX_E3V_K2CANFD: start 37, 1 bit, little-endian, data-type-policy=OVERRIDE, i-signal-type=PRIMITIVE, init-value=0, base-type=BT_FS_MMB_tast, compu {0=Cx0_kein_Tastbetrieb (CM_FS_MMB_tast_Cx0_kein_Tastbetrieb), 1=Cx1_Tastbetrieb_Fingerprintautomati (CM_FS_MMB_tast_Cx1_Tastbetrieb_Fingerprintautomati) (Tastbetrieb__Fingerprintautomati)}, range raw 0..1, transfer-property=TRIGGERED-ON-CHANGE-WITHOUT-REPETITION, to SAM(timeout 1 s)  # Memoryverstellung im Tastbetrieb
          signal FS_MMB_store_LED_on_XIX_Mem_FS_01_XIX_E3V_K2CANFD: start 38, 1 bit, little-endian, data-type-policy=OVERRIDE, i-signal-type=PRIMITIVE, init-value=0, base-type=BT_FS_MMB_store_LED_on, compu {0=Cx0_LED_aus (CM_FS_MMB_store_LED_on_Cx0_LED_aus), 1=Cx1_LED_ein (CM_FS_MMB_store_LED_on_Cx1_LED_ein)}, range raw 0..1, transfer-property=TRIGGERED-ON-CHANGE-WITHOUT-REPETITION  # LED für Speichern
          signal FS_MMB_storage_beep_XIX_Mem_FS_01_XIX_E3V_K2CANFD: start 39, 1 bit, little-endian, data-type-policy=OVERRIDE, i-signal-type=PRIMITIVE, init-value=0, base-type=BT_FS_MMB_storage_beep, compu {0=Cx0_beep_aus (CM_FS_MMB_storage_beep_Cx0_beep_aus) (beep aus), 1=Cx1_beep_ein (CM_FS_MMB_storage_beep_Cx1_beep_ein) (beep ein)}, range raw 0..1, transfer-property=TRIGGERED-ON-CHANGE-WITHOUT-REPETITION  # Quittierungston Sitzmemory FS (Anforderung Kombi)
          signal FS_MMB_store_XIX_Mem_FS_01_XIX_E3V_K2CANFD: start 40, 1 bit, little-endian, data-type-policy=OVERRIDE, i-signal-type=PRIMITIVE, init-value=0, base-type=BT_FS_MMB_store, compu {0=Cx0_nicht_speichern_kein_keyless_ve (CM_FS_MMB_store_Cx0_nicht_speichern_kein_keyless_ve) (nicht_speichern__kein_keyless_ve), 1=Cx1_abspeichern_keyless_verbaut (CM_FS_MMB_store_Cx1_abspeichern_keyless_verbaut) (abspeichern__keyless_verbaut)}, range raw 0..1, transfer-property=TRIGGERED-ON-CHANGE-WITHOUT-REPETITION  # Memoryposition Speichern
          signal FS_MMB_glob_stop_XIX_Mem_FS_01_XIX_E3V_K2CANFD: start 41, 1 bit, little-endian, data-type-policy=OVERRIDE, i-signal-type=PRIMITIVE, init-value=0, base-type=BT_FS_MMB_glob_stop, compu {0=Cx0_kein_globaler_Abbrucht (CM_FS_MMB_glob_stop_Cx0_kein_globaler_Abbrucht), 1=Cx1_globaler_Abbruch (CM_FS_MMB_glob_stop_Cx1_globaler_Abbruch)}, range raw 0..1, transfer-property=TRIGGERED-ON-CHANGE-WITHOUT-REPETITION, to SAM(timeout 1 s)  # Abbruch Memoryverstellung
          signal FS_EE_Fond_FS_enable_XIX_Mem_FS_01_XIX_E3V_K2CANFD: start 42, 1 bit, little-endian, data-type-policy=OVERRIDE, i-signal-type=PRIMITIVE, init-value=0, base-type=BT_FS_EE_Fond_FS_enable, compu {0=Cx0_EE_Fond_links_deaktiv (CM_FS_EE_Fond_FS_enable_Cx0_EE_Fond_links_deaktiv) (EE Fond links deaktiv), 1=Cx1_EE_Fond_links_aktiv_default_vom_MMI (CM_FS_EE_Fond_FS_enable_Cx1_EE_Fond_links_aktiv_default_vom_MMI) (EE Fond links aktiv (default) vom MMI)}, range raw 0..1, transfer-property=TRIGGERED-ON-CHANGE-WITHOUT-REPETITION  # EE Fond links
          signal FS_EE_Fond_BFS_enable_XIX_Mem_FS_01_XIX_E3V_K2CANFD: start 43, 1 bit, little-endian, data-type-policy=OVERRIDE, i-signal-type=PRIMITIVE, init-value=0, base-type=BT_FS_EE_Fond_BFS_enable, compu {0=Cx0_EE_Fond_rechts_deaktiv (CM_FS_EE_Fond_BFS_enable_Cx0_EE_Fond_rechts_deaktiv) (EE Fond rechts deaktiv), 1=Cx1_EE_Fond_rechts_aktiv_default_vom_MMI (CM_FS_EE_Fond_BFS_enable_Cx1_EE_Fond_rechts_aktiv_default_vom_MMI) (EE Fond rechts aktiv (default) vom MMI)}, range raw 0..1, transfer-property=TRIGGERED-ON-CHANGE-WITHOUT-REPETITION  # EE Fond rechts
          signal FS_BFS_Fond_Verst_enable_XIX_Mem_FS_01_XIX_E3V_K2CANFD: start 44, 1 bit, little-endian, data-type-policy=OVERRIDE, i-signal-type=PRIMITIVE, init-value=0, base-type=BT_FS_BFS_Fond_Verst_enable, transfer-property=TRIGGERED-ON-CHANGE-WITHOUT-REPETITION  # Verstellung Fond (vom MMI)
          signal FS_EE_BFS_enable_XIX_Mem_FS_01_XIX_E3V_K2CANFD: start 45, 1 bit, little-endian, data-type-policy=OVERRIDE, i-signal-type=PRIMITIVE, init-value=0, base-type=BT_FS_EE_BFS_enable, compu {0=Cx0_keine_EE_Freigabe (CM_FS_EE_BFS_enable_Cx0_keine_EE_Freigabe), 1=Cx1_EE_Freigabe (CM_FS_EE_BFS_enable_Cx1_EE_Freigabe)}, range raw 0..1, transfer-property=TRIGGERED-ON-CHANGE-WITHOUT-REPETITION  # EasyEntry Freigabe für Befahrersitz.
      frame MFG_01_XIX_E3V_K2CANFD: id 0x493, to SAM, frame-length=8, can-addressing-mode=STANDARD, can-frame-rx-behavior=CAN-FD, can-frame-tx-behavior=CAN-FD
        pdu MFG_01_XIX_E3V_K2CANFD_E2E: length=8, minimum-delay=0.02, transmission-mode-true-timing=event-controlled-timing={number-of-repetitions=0, repetition-period=0.0}, unused-bit-pattern=0  # Fuer die Botschaft ist das Cyclic-Timing 0.2 zu verwenden.
          signal MFG_01_CRC_XIX_MFG_01_XIX_E3V_K2CANFD: start 0, 8 bit, little-endian, data-type-policy=OVERRIDE, i-signal-type=PRIMITIVE, base-type=BT_MFG_01_CRC, compu {phys=raw for raw 0..255}, range phys 0..255, raw 0..255, to SAM(timeout 2 s)  # Für MLB: "Berechnung siehe Lastenheft "Kommunikationsabsicherung für FlexRay und CAN"" Ab MQB und MLBevo: "Berechnung siehe Lastenheft "End-to-End Kommunikationsabsicherung"" Endwerte siehe Begleitdokument "S-PDU Kennungsfolgen"
          signal MFG_01_BZ_XIX_MFG_01_XIX_E3V_K2CANFD: start 8, 4 bit, little-endian, data-type-policy=OVERRIDE, i-signal-type=PRIMITIVE, base-type=BT_MFG_01_BZ, compu {phys=raw for raw 0..15}, range phys 0..15, raw 0..15, to SAM(timeout 2 s)  # 4bit Botschaftszähler, wird in jeder Sendebotschaft inkrementiert
          signal MF_ZV_Lock_XIX_MFG_01_XIX_E3V_K2CANFD: start 12, 1 bit, little-endian, data-type-policy=OVERRIDE, i-signal-type=PRIMITIVE, init-value=0, base-type=BT_MF_ZV_Lock, compu {0=Cx0_Locktaster_nicht_betaetigt (CM_MF_ZV_Lock_Cx0_Locktaster_nicht_betaetigt), 1=Cx1_Locktaster_betaetigt (CM_MF_ZV_Lock_Cx1_Locktaster_betaetigt)}, range raw 0..1  # Verriegelungsanforderung durch MFG analog Meldung einer Locktasterbetätigung durch TSG.
          signal MF_Motorweiterlauf_XIX_MFG_01_XIX_E3V_K2CANFD: start 13, 1 bit, little-endian, data-type-policy=OVERRIDE, i-signal-type=PRIMITIVE, init-value=0, base-type=BT_MF_Motorweiterlauf, compu {0=Cx0_inaktiv (CM_MF_Motorweiterlauf_Cx0_inaktiv), 1=Cx1_aktiv (CM_MF_Motorweiterlauf_Cx1_aktiv)}, range raw 0..1, to SAM(timeout 2 s)  # Motorstop Behoerdenfahrzeug
          signal MF_Abzugssperre_XIX_MFG_01_XIX_E3V_K2CANFD: start 14, 1 bit, little-endian, data-type-policy=OVERRIDE, i-signal-type=PRIMITIVE, init-value=0, base-type=BT_MF_Abzugssperre, compu {0=Cx0_inaktiv (CM_MF_Abzugssperre_Cx0_inaktiv), 1=Cx1_aktiv (CM_MF_Abzugssperre_Cx1_aktiv)}, range raw 0..1  # Schlüsselabzugssperre
          signal MF_Anlassersperre_XIX_MFG_01_XIX_E3V_K2CANFD: start 15, 1 bit, little-endian, data-type-policy=OVERRIDE, i-signal-type=PRIMITIVE, init-value=0, base-type=BT_MF_Anlassersperre, compu {0=Cx0_inaktiv (CM_MF_Anlassersperre_Cx0_inaktiv), 1=Cx1_aktiv (CM_MF_Anlassersperre_Cx1_aktiv)}, range raw 0..1  # Notarzt 230V-Steckdose
          signal MF_Variante_XIX_MFG_01_XIX_E3V_K2CANFD: start 16, 3 bit, little-endian, data-type-policy=OVERRIDE, i-signal-type=PRIMITIVE, init-value=0, base-type=BT_MF_Variante, compu {0=Cx0_keine_Sonderfunktion (CM_MF_Variante_Cx0_keine_Sonderfunktion), 1=Cx1_Sondersignalfahrzeug (CM_MF_Variante_Cx1_Sondersignalfahrzeug), 2=Cx2_Taxi (CM_MF_Variante_Cx2_Taxi), 3=Cx3_Fahrhilfe (CM_MF_Variante_Cx3_Fahrhilfe), 4=Cx4_Fahrschule_Extra (CM_MF_Variante_Cx4_Fahrschule_Extra), 5=Cx5_SSF (CM_MF_Variante_Cx5_SSF), 6=Cx6_DBMC (CM_MF_Variante_Cx6_DBMC), 7=Cx7_Arbeitsmaschine (CM_MF_Variante_Cx7_Arbeitsmaschine)}, range raw 0..7, to SAM(timeout 2 s)  # Sonderfahrzeugvariante 0 = keine Sonderfunktion 1 = Sondersignalfahrzeug 2 = Taxi 3 = Fahrhilfe 4 = Fahrschule+Extra 5 = SSF 6 = DBMC 7 = Arbeitsmaschine
          signal MF_Schluessel_scan_XIX_MFG_01_XIX_E3V_K2CANFD: start 19, 1 bit, little-endian, data-type-policy=OVERRIDE, i-signal-type=PRIMITIVE, init-value=0, base-type=BT_MF_Schluessel_scan, compu {0=Cx0_inaktiv (CM_MF_Schluessel_scan_Cx0_inaktiv), 1=Cx1_aktiv (CM_MF_Schluessel_scan_Cx1_aktiv)}, range raw 0..1  # Anforderung eines Innenraumscans - Schlüsselsuche
          signal MF_Laderelais_XIX_MFG_01_XIX_E3V_K2CANFD: start 20, 1 bit, little-endian, data-type-policy=OVERRIDE, i-signal-type=PRIMITIVE, init-value=0, base-type=BT_MF_Laderelais, compu {0=Cx0_Relais_offen (CM_MF_Laderelais_Cx0_Relais_offen), 1=Cx1_Relais_geschlossen (CM_MF_Laderelais_Cx1_Relais_geschlossen)}, range raw 0..1  # Signal für die Auswertung zur Anzeige der Batterie-Schwach-Anzeige im Kombi
          signal MF_StartStopp_Info_XIX_MFG_01_XIX_E3V_K2CANFD: start 21, 2 bit, little-endian, data-type-policy=OVERRIDE, i-signal-type=PRIMITIVE, init-value=0, base-type=BT_MF_StartStopp_Info, compu {0=Cx0_Motorlauf_nicht_notwendig_Stoppfreigabe (CM_MF_StartStopp_Info_Cx0_Motorlauf_nicht_notwendig_Stoppfreigabe) (Motorlauf_nicht_notwendig_(Stoppfreigabe)), 1=Cx1_Motoranlauf_nicht_zwingend_notwendig_Stoppverbot_keine_Startanforderung (CM_MF_StartStopp_Info_Cx1_Motoranlauf_nicht_zwingend_notwendig_Stoppverbot_keine_Startanforderung) (Motoranlauf_nicht_zwingend_notwendig_(Stoppverbot,keine_Startanforderung)), 2=Cx2_Motoranlauf_zwingend_notwendig_Startanforderung (CM_MF_StartStopp_Info_Cx2_Motoranlauf_zwingend_notwendig_Startanforderung) (Motoranlauf_zwingend_notwendig_(Startanforderung)), 3=Cx3_Systemfehler (CM_MF_StartStopp_Info_Cx3_Systemfehler)}, range raw 0..3  # Stopp-Freigabe und Start-Anforderung an den Start-Stopp-Koordinator
          signal MF_Fernbed_ein_XIX_MFG_01_XIX_E3V_K2CANFD: start 23, 1 bit, little-endian, data-type-policy=OVERRIDE, i-signal-type=PRIMITIVE, init-value=0, base-type=BT_MF_Fernbed_ein, compu {0=Cx0_inaktiv (CM_MF_Fernbed_ein_Cx0_inaktiv), 1=Cx1_aktiv (CM_MF_Fernbed_ein_Cx1_aktiv)}, range raw 0..1, to SAM(timeout 2 s)  # Fernbedienung für Petri+Lehr; Versehrte und Fahrschule
          signal MF_Standlicht_XIX_MFG_01_XIX_E3V_K2CANFD: start 24, 1 bit, little-endian, data-type-policy=OVERRIDE, i-signal-type=PRIMITIVE, init-value=0, base-type=BT_MF_Standlicht, compu {0=Cx0_inaktiv (CM_MF_Standlicht_Cx0_inaktiv), 1=Cx1_aktiv (CM_MF_Standlicht_Cx1_aktiv)}, range raw 0..1  # statisch oder auch mit Blink_modi für Taxialarm
          signal MF_Fahrlicht_XIX_MFG_01_XIX_E3V_K2CANFD: start 25, 1 bit, little-endian, data-type-policy=OVERRIDE, i-signal-type=PRIMITIVE, init-value=0, base-type=BT_MF_Fahrlicht, compu {0=Cx0_inaktiv (CM_MF_Fahrlicht_Cx0_inaktiv), 1=Cx1_aktiv (CM_MF_Fahrlicht_Cx1_aktiv)}, range raw 0..1, to SAM(timeout 2 s)  # statisch oder auch mit Blink_modi für interm. Fahrlicht
          signal MF_interm_Fernlicht_XIX_MFG_01_XIX_E3V_K2CANFD: start 26, 1 bit, little-endian, data-type-policy=OVERRIDE, i-signal-type=PRIMITIVE, init-value=0, base-type=BT_MF_interm_Fernlicht, compu {0=Cx0_inaktiv (CM_MF_interm_Fernlicht_Cx0_inaktiv), 1=Cx1_aktiv (CM_MF_interm_Fernlicht_Cx1_aktiv)}, range raw 0..1  # mit Blink_modi für SoSi oder Taxialarm
          signal MF_Warnblinker_XIX_MFG_01_XIX_E3V_K2CANFD: start 27, 1 bit, little-endian, data-type-policy=OVERRIDE, i-signal-type=PRIMITIVE, init-value=0, base-type=BT_MF_Warnblinker, compu {0=Cx0_inaktiv (CM_MF_Warnblinker_Cx0_inaktiv), 1=Cx1_aktiv (CM_MF_Warnblinker_Cx1_aktiv)}, range raw 0..1  # Versehrte
          signal MF_Fussraumbel_XIX_MFG_01_XIX_E3V_K2CANFD: start 28, 1 bit, little-endian, data-type-policy=OVERRIDE, i-signal-type=PRIMITIVE, init-value=0, base-type=BT_MF_Fussraumbel, compu {0=Cx0_inaktiv (CM_MF_Fussraumbel_Cx0_inaktiv), 1=Cx1_aktiv (CM_MF_Fussraumbel_Cx1_aktiv)}, range raw 0..1, to SAM(timeout 2 s)  # Fussraumbeleuchtung, Fahrschule
          signal MF_Innenraumbel_XIX_MFG_01_XIX_E3V_K2CANFD: start 29, 1 bit, little-endian, data-type-policy=OVERRIDE, i-signal-type=PRIMITIVE, init-value=0, base-type=BT_MF_Innenraumbel, compu {0=Cx0_inaktiv (CM_MF_Innenraumbel_Cx0_inaktiv), 1=Cx1_aktiv (CM_MF_Innenraumbel_Cx1_aktiv)}, range raw 0..1, to SAM(timeout 2 s)  # sämtliche Beleuchtungen akitivieren (Fussraum, Tür u.a.)
          signal MF_Innenraumbel_Unterdrueck_XIX_MFG_01_XIX_E3V_K2CANFD: start 30, 1 bit, little-endian, data-type-policy=OVERRIDE, i-signal-type=PRIMITIVE, init-value=0, base-type=BT_MF_Innenraumbel_Unterdrueck, compu {0=Cx0_inaktiv (CM_MF_Innenraumbel_Unterdrueck_Cx0_inaktiv), 1=Cx1_aktiv (CM_MF_Innenraumbel_Unterdrueck_Cx1_aktiv)}, range raw 0..1, to SAM(timeout 2 s)  # Unterdrückung des Innenlichts/Fussraumbeleuchtung, sowie Schließblinken
          signal MF_Notstart_XIX_MFG_01_XIX_E3V_K2CANFD: start 31, 1 bit, little-endian, data-type-policy=OVERRIDE, i-signal-type=PRIMITIVE, base-type=BT_MF_Notstart, compu {0=Cx0_kein_Notstart (CM_MF_Notstart_Cx0_kein_Notstart), 1=Cx1_Notstart (CM_MF_Notstart_Cx1_Notstart)}, range raw 0..1  # Signal zeigt an, dass ein Notstart über DBMC erfolgte. Verwendung in Verbindung mit Signal MF_Variante = DBMC.
          signal MF_Blk_li_XIX_MFG_01_XIX_E3V_K2CANFD: start 32, 1 bit, little-endian, data-type-policy=OVERRIDE, i-signal-type=PRIMITIVE, init-value=0, base-type=BT_MF_Blk_li, compu {0=Cx0_inaktiv (CM_MF_Blk_li_Cx0_inaktiv), 1=Cx1_aktiv (CM_MF_Blk_li_Cx1_aktiv)}, range raw 0..1  # Versehrte oder Fahrschule; Prio über Fernbedienung ein
          signal MF_Blk_re_XIX_MFG_01_XIX_E3V_K2CANFD: start 33, 1 bit, little-endian, data-type-policy=OVERRIDE, i-signal-type=PRIMITIVE, init-value=0, base-type=BT_MF_Blk_re, compu {0=Cx0_inaktiv (CM_MF_Blk_re_Cx0_inaktiv), 1=Cx1_aktiv (CM_MF_Blk_re_Cx1_aktiv)}, range raw 0..1  # Versehrte oder Fahrschule; Prio über Fernbedienung ein
          signal MF_Lichthupe_XIX_MFG_01_XIX_E3V_K2CANFD: start 34, 1 bit, little-endian, data-type-policy=OVERRIDE, i-signal-type=PRIMITIVE, init-value=0, base-type=BT_MF_Lichthupe, compu {0=Cx0_inaktiv (CM_MF_Lichthupe_Cx0_inaktiv), 1=Cx1_aktiv (CM_MF_Lichthupe_Cx1_aktiv)}, range raw 0..1  # Versehrte oder Fahrschule; Oder-Verknuepfung
          signal MF_Fernlicht_XIX_MFG_01_XIX_E3V_K2CANFD: start 35, 1 bit, little-endian, data-type-policy=OVERRIDE, i-signal-type=PRIMITIVE, init-value=0, base-type=BT_MF_Fernlicht, compu {0=Cx0_inaktiv (CM_MF_Fernlicht_Cx0_inaktiv), 1=Cx1_aktiv (CM_MF_Fernlicht_Cx1_aktiv)}, range raw 0..1  # Versehrte oder Fahrschule; Oder-Verknüpfung
          signal MF_HFS_verriegeln_XIX_MFG_01_XIX_E3V_K2CANFD: start 36, 1 bit, little-endian, data-type-policy=OVERRIDE, i-signal-type=PRIMITIVE, init-value=0, base-type=BT_MF_HFS_verriegeln, compu {0=Cx0_nicht_verriegeln (CM_MF_HFS_verriegeln_Cx0_nicht_verriegeln), 1=Cx1_verriegeln (CM_MF_HFS_verriegeln_Cx1_verriegeln)}, range raw 0..1  # Hinten Fahrertür verriegeln
          signal MF_HFS_entriegeln_XIX_MFG_01_XIX_E3V_K2CANFD: start 37, 1 bit, little-endian, data-type-policy=OVERRIDE, i-signal-type=PRIMITIVE, init-value=0, base-type=BT_MF_HFS_entriegeln, compu {0=Cx0_nicht_entriegeln (CM_MF_HFS_entriegeln_Cx0_nicht_entriegeln), 1=Cx1_entriegeln (CM_MF_HFS_entriegeln_Cx1_entriegeln)}, range raw 0..1  # Hinten Fahrertür entriegeln
          signal MF_HBFS_verriegeln_XIX_MFG_01_XIX_E3V_K2CANFD: start 38, 1 bit, little-endian, data-type-policy=OVERRIDE, i-signal-type=PRIMITIVE, init-value=0, base-type=BT_MF_HBFS_verriegeln, compu {0=Cx0_nicht_verriegeln (CM_MF_HBFS_verriegeln_Cx0_nicht_verriegeln), 1=Cx1_verriegeln (CM_MF_HBFS_verriegeln_Cx1_verriegeln)}, range raw 0..1  # Hinten Beifahrertür verriegeln
          signal MF_HBFS_entriegeln_XIX_MFG_01_XIX_E3V_K2CANFD: start 39, 1 bit, little-endian, data-type-policy=OVERRIDE, i-signal-type=PRIMITIVE, init-value=0, base-type=BT_MF_HBFS_entriegeln, compu {0=Cx0_nicht_entriegeln (CM_MF_HBFS_entriegeln_Cx0_nicht_entriegeln), 1=Cx1_entriegeln (CM_MF_HBFS_entriegeln_Cx1_entriegeln)}, range raw 0..1  # Hinten Beifahrertür entriegeln
          signal MF_Tippwischen_XIX_MFG_01_XIX_E3V_K2CANFD: start 40, 1 bit, little-endian, data-type-policy=OVERRIDE, i-signal-type=PRIMITIVE, init-value=0, base-type=BT_MF_Tippwischen, compu {0=Cx0_inaktiv (CM_MF_Tippwischen_Cx0_inaktiv), 1=Cx1_aktiv (CM_MF_Tippwischen_Cx1_aktiv)}, range raw 0..1, to SAM(timeout 2 s)  # Versehrte oder Fahrschule; Oder-Verknüpfung
          signal MF_Frontintervall_XIX_MFG_01_XIX_E3V_K2CANFD: start 41, 1 bit, little-endian, data-type-policy=OVERRIDE, i-signal-type=PRIMITIVE, init-value=0, base-type=BT_MF_Frontintervall, compu {0=Cx0_inaktiv (CM_MF_Frontintervall_Cx0_inaktiv), 1=Cx1_aktiv (CM_MF_Frontintervall_Cx1_aktiv)}, range raw 0..1, to SAM(timeout 2 s)  # Versehrte oder Fahrschule; Oder-Verknüpfung
          signal MF_Wischerstufe_1_XIX_MFG_01_XIX_E3V_K2CANFD: start 42, 1 bit, little-endian, data-type-policy=OVERRIDE, i-signal-type=PRIMITIVE, init-value=0, base-type=BT_MF_Wischerstufe_1, compu {0=Cx0_inaktiv (CM_MF_Wischerstufe_1_Cx0_inaktiv), 1=Cx1_aktiv (CM_MF_Wischerstufe_1_Cx1_aktiv)}, range raw 0..1, to SAM(timeout 2 s)  # Versehrte oder Fahrschule; Oder-Verknüpfung
          signal MF_Wischerstufe_2_XIX_MFG_01_XIX_E3V_K2CANFD: start 43, 1 bit, little-endian, data-type-policy=OVERRIDE, i-signal-type=PRIMITIVE, init-value=0, base-type=BT_MF_Wischerstufe_2, compu {0=Cx0_inaktiv (CM_MF_Wischerstufe_2_Cx0_inaktiv), 1=Cx1_aktiv (CM_MF_Wischerstufe_2_Cx1_aktiv)}, range raw 0..1, to SAM(timeout 2 s)  # Versehrte oder Fahrschule; Oder-Verknüpfung
          signal MF_Frontwaschen_XIX_MFG_01_XIX_E3V_K2CANFD: start 44, 1 bit, little-endian, data-type-policy=OVERRIDE, i-signal-type=PRIMITIVE, init-value=0, base-type=BT_MF_Frontwaschen, compu {0=Cx0_inaktiv (CM_MF_Frontwaschen_Cx0_inaktiv), 1=Cx1_aktiv (CM_MF_Frontwaschen_Cx1_aktiv)}, range raw 0..1, to SAM(timeout 2 s)  # Versehrte oder Fahrschule; Oder-Verknüpfung
          signal MF_nachtr_Stopp_Anf_XIX_MFG_01_XIX_E3V_K2CANFD: start 45, 1 bit, little-endian, data-type-policy=OVERRIDE, i-signal-type=PRIMITIVE, init-value=0, base-type=BT_MF_nachtr_Stopp_Anf, compu {0=Cx0_nicht_angefordert (CM_MF_nachtr_Stopp_Anf_Cx0_nicht_angefordert), 1=Cx1_angefordert (CM_MF_nachtr_Stopp_Anf_Cx1_angefordert)}, range raw 0..1  # Dieses Signal dient dem Motor als Trigger, dass ein nachträglicher Motorstopp eingeleitet werden kann, wenn es die Bedingungen des StSt Koordinators dies zulassen.
          signal MF_Heckintervall_XIX_MFG_01_XIX_E3V_K2CANFD: start 46, 1 bit, little-endian, data-type-policy=OVERRIDE, i-signal-type=PRIMITIVE, init-value=0, base-type=BT_MF_Heckintervall, compu {0=Cx0_inaktiv (CM_MF_Heckintervall_Cx0_inaktiv), 1=Cx1_aktiv (CM_MF_Heckintervall_Cx1_aktiv)}, range raw 0..1, to SAM(timeout 2 s)  # Versehrte oder Fahrschule; Oder-Verknüpfung
          signal MF_Heckwaschen_XIX_MFG_01_XIX_E3V_K2CANFD: start 47, 1 bit, little-endian, data-type-policy=OVERRIDE, i-signal-type=PRIMITIVE, init-value=0, base-type=BT_MF_Heckwaschen, compu {0=Cx0_inaktiv (CM_MF_Heckwaschen_Cx0_inaktiv), 1=Cx1_aktiv (CM_MF_Heckwaschen_Cx1_aktiv)}, range raw 0..1, to SAM(timeout 2 s)  # Versehrte oder Fahrschule; Oder-Verknüpfung
          signal MF_Summer_XIX_MFG_01_XIX_E3V_K2CANFD: start 48, 1 bit, little-endian, data-type-policy=OVERRIDE, i-signal-type=PRIMITIVE, init-value=0, base-type=BT_MF_Summer, compu {0=Cx0_inaktiv (CM_MF_Summer_Cx0_inaktiv), 1=Cx1_aktiv (CM_MF_Summer_Cx1_aktiv)}, range raw 0..1  # Warnsummer für Funkhauptschalter und Fahrschulpedal
          signal MF_Alarm_Blinkertakt_XIX_MFG_01_XIX_E3V_K2CANFD: start 49, 1 bit, little-endian, data-type-policy=OVERRIDE, i-signal-type=PRIMITIVE, init-value=0, base-type=BT_MF_Alarm_Blinkertakt, compu {0=Cx0_inaktiv (CM_MF_Alarm_Blinkertakt_Cx0_inaktiv), 1=Cx1_aktiv (CM_MF_Alarm_Blinkertakt_Cx1_aktiv)}, range raw 0..1  # Ansteuerung Blinker bei Alarm. Signal wird getaktet. 0 = Blinker für Alarm aus 1 = Blinker für Alarm ein
          signal MF_Alarm_Blinker_XIX_MFG_01_XIX_E3V_K2CANFD: start 50, 1 bit, little-endian, data-type-policy=OVERRIDE, i-signal-type=PRIMITIVE, init-value=0, base-type=BT_MF_Alarm_Blinker, compu {0=Cx0_inaktiv (CM_MF_Alarm_Blinker_Cx0_inaktiv), 1=Cx1_aktiv (CM_MF_Alarm_Blinker_Cx1_aktiv)}, range raw 0..1  # Taxialarmblinken, wie DWA ohne Fanfare
          signal MF_TFL_Abschaltung_XIX_MFG_01_XIX_E3V_K2CANFD: start 51, 1 bit, little-endian, data-type-policy=OVERRIDE, i-signal-type=PRIMITIVE, init-value=0, base-type=BT_MF_TFL_Abschaltung, compu {0=Cx0_inaktiv (CM_MF_TFL_Abschaltung_Cx0_inaktiv), 1=Cx1_aktiv (CM_MF_TFL_Abschaltung_Cx1_aktiv)}, range raw 0..1  # Abschaltung des Tagfahrlicht 0 = keine Auswirkung 1 = Tagfahrlicht deaktiviert
          signal MF_interm_Takt_XIX_MFG_01_XIX_E3V_K2CANFD: start 52, 1 bit, little-endian, data-type-policy=OVERRIDE, i-signal-type=PRIMITIVE, init-value=0, base-type=BT_MF_interm_Takt, compu {0=Cx0_inaktiv (CM_MF_interm_Takt_Cx0_inaktiv), 1=Cx1_aktiv (CM_MF_interm_Takt_Cx1_aktiv)}, range raw 0..1  # Taktung von intermittierenden Fernlicht/Fahrlicht bei einer Einsatzfahrt 0 = Licht aus 1 = Licht ein
          signal MF_Tuerentriegelung_hinten_XIX_MFG_01_XIX_E3V_K2CANFD: start 53, 1 bit, little-endian, data-type-policy=OVERRIDE, i-signal-type=PRIMITIVE, init-value=0, base-type=BT_MF_Tuerentriegelung_hinten, compu {0=Cx0_inaktiv (CM_MF_Tuerentriegelung_hinten_Cx0_inaktiv), 1=Cx1_aktiv (CM_MF_Tuerentriegelung_hinten_Cx1_aktiv)}, range raw 0..1  # Bei von innen verriegelten Fahrzeug Türen hinten entriegeln 0 = keine Auswirkung 1 = Türen hinten entriegeln
          signal MF_interm_Fahrlicht_XIX_MFG_01_XIX_E3V_K2CANFD: start 54, 1 bit, little-endian, data-type-policy=OVERRIDE, i-signal-type=PRIMITIVE, init-value=0, base-type=BT_MF_interm_Fahrlicht, compu {0=Cx0_inaktiv (CM_MF_interm_Fahrlicht_Cx0_inaktiv), 1=Cx1_aktiv (CM_MF_interm_Fahrlicht_Cx1_aktiv)}, range raw 0..1  # Ansteuerung intermittierendes Abblendlicht
          signal MF_Signalhorn_XIX_MFG_01_XIX_E3V_K2CANFD: start 55, 1 bit, little-endian, data-type-policy=OVERRIDE, i-signal-type=PRIMITIVE, init-value=0, base-type=BT_MF_Signalhorn, compu {0=Cx0_inaktiv (CM_MF_Signalhorn_Cx0_inaktiv), 1=Cx1_aktiv (CM_MF_Signalhorn_Cx1_aktiv)}, range raw 0..1, to SAM(timeout 2 s)  # Versehrte, Fahrschule oder Taxi (bei Alarm)
          signal MF_FH_FT_hoch_XIX_MFG_01_XIX_E3V_K2CANFD: start 56, 1 bit, little-endian, data-type-policy=OVERRIDE, i-signal-type=PRIMITIVE, init-value=0, base-type=BT_MF_FH_FT_hoch, compu {0=Cx0_inaktiv (CM_MF_FH_FT_hoch_Cx0_inaktiv), 1=Cx1_aktiv (CM_MF_FH_FT_hoch_Cx1_aktiv)}, range raw 0..1  # Versehrte
          signal MF_FH_FT_tief_XIX_MFG_01_XIX_E3V_K2CANFD: start 57, 1 bit, little-endian, data-type-policy=OVERRIDE, i-signal-type=PRIMITIVE, init-value=0, base-type=BT_MF_FH_FT_tief, compu {0=Cx0_inaktiv (CM_MF_FH_FT_tief_Cx0_inaktiv), 1=Cx1_aktiv (CM_MF_FH_FT_tief_Cx1_aktiv)}, range raw 0..1  # Versehrte
          signal MF_FH_BT_hoch_XIX_MFG_01_XIX_E3V_K2CANFD: start 58, 1 bit, little-endian, data-type-policy=OVERRIDE, i-signal-type=PRIMITIVE, init-value=0, base-type=BT_MF_FH_BT_hoch, compu {0=Cx0_inaktiv (CM_MF_FH_BT_hoch_Cx0_inaktiv), 1=Cx1_aktiv (CM_MF_FH_BT_hoch_Cx1_aktiv)}, range raw 0..1  # Versehrte
          signal MF_FH_BT_tief_XIX_MFG_01_XIX_E3V_K2CANFD: start 59, 1 bit, little-endian, data-type-policy=OVERRIDE, i-signal-type=PRIMITIVE, init-value=0, base-type=BT_MF_FH_BT_tief, compu {0=Cx0_inaktiv (CM_MF_FH_BT_tief_Cx0_inaktiv), 1=Cx1_aktiv (CM_MF_FH_BT_tief_Cx1_aktiv)}, range raw 0..1  # Versehrte
          signal MF_FT_verriegeln_XIX_MFG_01_XIX_E3V_K2CANFD: start 60, 1 bit, little-endian, data-type-policy=OVERRIDE, i-signal-type=PRIMITIVE, init-value=0, base-type=BT_MF_FT_verriegeln, compu {0=Cx0_nicht_verriegeln (CM_MF_FT_verriegeln_Cx0_nicht_verriegeln), 1=Cx1_verriegeln (CM_MF_FT_verriegeln_Cx1_verriegeln)}, range raw 0..1  # Fahrertür verriegeln
          signal MF_FT_entriegeln_XIX_MFG_01_XIX_E3V_K2CANFD: start 61, 1 bit, little-endian, data-type-policy=OVERRIDE, i-signal-type=PRIMITIVE, init-value=0, base-type=BT_MF_FT_entriegeln, compu {0=Cx0_nicht_entriegeln (CM_MF_FT_entriegeln_Cx0_nicht_entriegeln), 1=Cx1_entriegeln (CM_MF_FT_entriegeln_Cx1_entriegeln)}, range raw 0..1  # Fahrertür entriegeln
          signal MF_BT_verriegeln_XIX_MFG_01_XIX_E3V_K2CANFD: start 62, 1 bit, little-endian, data-type-policy=OVERRIDE, i-signal-type=PRIMITIVE, init-value=0, base-type=BT_MF_BT_verriegeln, compu {0=Cx0_nicht_verriegeln (CM_MF_BT_verriegeln_Cx0_nicht_verriegeln), 1=Cx1_verriegeln (CM_MF_BT_verriegeln_Cx1_verriegeln)}, range raw 0..1  # Beifahrertür verriegeln
          signal MF_BT_entriegeln_XIX_MFG_01_XIX_E3V_K2CANFD: start 63, 1 bit, little-endian, data-type-policy=OVERRIDE, i-signal-type=PRIMITIVE, init-value=0, base-type=BT_MF_BT_entriegeln, compu {0=Cx0_nicht_entriegeln (CM_MF_BT_entriegeln_Cx0_nicht_entriegeln), 1=Cx1_entriegeln (CM_MF_BT_entriegeln_Cx1_entriegeln)}, range raw 0..1  # Beifahrertür entriegeln
          mapping SG_MFG_01_XIX_E3V_K2CANFD: i-signal-group=SG_MFG_01_XIX_E3V_K2CANFD, transfer-property=TRIGGERED-WITHOUT-REPETITION
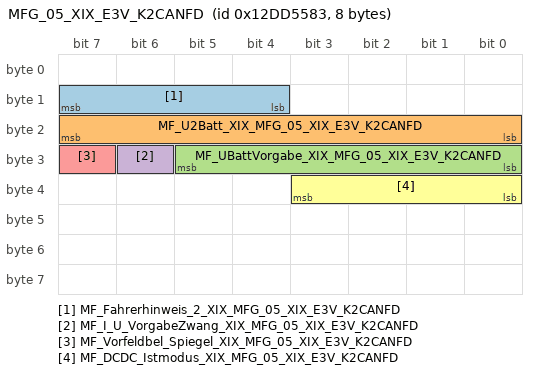
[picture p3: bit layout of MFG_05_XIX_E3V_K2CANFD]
      frame MFG_05_XIX_E3V_K2CANFD: id 0x12DD5583, to SAM, frame-length=8, can-addressing-mode=EXTENDED, can-frame-rx-behavior=CAN-FD, can-frame-tx-behavior=CAN-FD
        pdu MFG_05_XIX_E3V_K2CANFD: length=8, transmission-mode-true-timing=cyclic-timing={time-offset=0, time-period=0.1}, unused-bit-pattern=0
          signal MF_Fahrerhinweis_2_XIX_MFG_05_XIX_E3V_K2CANFD: start 12, 4 bit, little-endian, data-type-policy=OVERRIDE, i-signal-type=PRIMITIVE, init-value=0, base-type=BT_MF_Fahrerhinweis_2, compu {0=Cx0_keine_Anzeige (CM_MF_Fahrerhinweis_2_Cx0_keine_Anzeige), 1=Cx1_Dach_zu_oft_bewegt (CM_MF_Fahrerhinweis_2_Cx1_Dach_zu_oft_bewegt), 2=Cx2_Aufstellvorbedingungen (CM_MF_Fahrerhinweis_2_Cx2_Aufstellvorbedingungen), 3=Cx3_Absenkvorbedingungen (CM_MF_Fahrerhinweis_2_Cx3_Absenkvorbedingungen), 4=Cx4_Fehler_Aufstelldach_Werkstatt (CM_MF_Fahrerhinweis_2_Cx4_Fehler_Aufstelldach_Werkstatt), 5=Cx5_Aufstelldach_offen (CM_MF_Fahrerhinweis_2_Cx5_Aufstelldach_offen), 6=Cx6_Aufstelldach_klemmt (CM_MF_Fahrerhinweis_2_Cx6_Aufstelldach_klemmt), 7=Cx7_Fehler_Aufstelldach_manuell (CM_MF_Fahrerhinweis_2_Cx7_Fehler_Aufstelldach_manuell), 8=Cx8_Aufstelldach_Endposition (CM_MF_Fahrerhinweis_2_Cx8_Aufstelldach_Endposition), 9=Cx9_Waehrend_Fahrt_nicht_moeglich (CM_MF_Fahrerhinweis_2_Cx9_Waehrend_Fahrt_nicht_moeglich), 10=Cxa_Zur_Zeit_nicht_moeglich (CM_MF_Fahrerhinweis_2_Cxa_Zur_Zeit_nicht_moeglich), 11=Cxb_Batterie_schwach_Motorlauf (CM_MF_Fahrerhinweis_2_Cxb_Batterie_schwach_Motorlauf), 12=Cxc_Ladestecker_ist_gesteckt (CM_MF_Fahrerhinweis_2_Cxc_Ladestecker_ist_gesteckt)}, range raw 0..12, transfer-property=PENDING  # Fahrerhinweis Kombiinstrument für Camperfunktionen
          signal MF_U2Batt_XIX_MFG_05_XIX_E3V_K2CANFD: start 16, 8 bit, little-endian, data-type-policy=OVERRIDE, i-signal-type=PRIMITIVE, init-value=0, base-type=BT_MF_U2Batt, compu {phys=raw*0.01+12.5 for raw 0..250, 251=Cxfb_U_kleiner_min (CM_MF_U2Batt_Cxfb_U_kleiner_min), 252=Cxfc_U_groesser_max (CM_MF_U2Batt_Cxfc_U_groesser_max), 255=Cxff_init (CM_MF_U2Batt_Cxff_init); unit Unit_Volt}, range phys 12.5..15 Unit_Volt, raw 0..255, unit=Unit_Volt, transfer-property=PENDING  # Spannung der Zweitbatterie
          signal MF_UBattVorgabe_XIX_MFG_05_XIX_E3V_K2CANFD: start 24, 6 bit, little-endian, data-type-policy=OVERRIDE, i-signal-type=PRIMITIVE, init-value=0, base-type=BT_MF_UBattVorgabe, compu {phys=raw*0.1+12 for raw 0..60, 63=Cx3f_init (CM_MF_UBattVorgabe_Cx3f_init); unit Unit_Volt}, range phys 12..18 Unit_Volt, raw 0..63, unit=Unit_Volt, transfer-property=PENDING  # Ladespannungsempfehlung Zusatz Batterie
          signal MF_I_U_VorgabeZwang_XIX_MFG_05_XIX_E3V_K2CANFD: start 30, 1 bit, little-endian, data-type-policy=OVERRIDE, i-signal-type=PRIMITIVE, init-value=0, base-type=BT_MF_I_U_VorgabeZwang, compu {0=Cx0_Wunschvorgabe (CM_MF_I_U_VorgabeZwang_Cx0_Wunschvorgabe), 1=Cx1_Zwangsvorgabe (CM_MF_I_U_VorgabeZwang_Cx1_Zwangsvorgabe)}, range raw 0..1, transfer-property=PENDING  # Ladestrom und Spannungsvorgabe sind als Zwangsvorgaben der Zusatzbatterie zu behandeln
          signal MF_Vorfeldbel_Spiegel_XIX_MFG_05_XIX_E3V_K2CANFD: start 31, 1 bit, little-endian, data-type-policy=OVERRIDE, i-signal-type=PRIMITIVE, base-type=BT_MF_Vorfeldbel_Spiegel, compu {0=Cx0_Serienvorfeldbeleuchtung (CM_MF_Vorfeldbel_Spiegel_Cx0_Serienvorfeldbeleuchtung), 1=Cx1_Vorfeldbeleuchtung_Spiegel_aktiv (CM_MF_Vorfeldbel_Spiegel_Cx1_Vorfeldbeleuchtung_Spiegel_aktiv)}, range raw 0..1, transfer-property=PENDING  # Schaltet die Vorfeldbeleuchtung der Außenspiegel
          signal MF_DCDC_Istmodus_XIX_MFG_05_XIX_E3V_K2CANFD: start 32, 4 bit, little-endian, data-type-policy=OVERRIDE, i-signal-type=PRIMITIVE, init-value=0, base-type=BT_MF_DCDC_Istmodus, invalid-value=Invalid_MF_DCDC_Istmodus_XIX_MFG_05_XIX_E3V_K2CANFD:5, compu {0=Cx0_Standby (CM_MF_DCDC_Istmodus_Cx0_Standby), 2=Cx2_Strom_ZusBn_ErstBn (CM_MF_DCDC_Istmodus_Cx2_Strom_ZusBn_ErstBn), 3=Cx3_Strom_ErstBn_ZusBn (CM_MF_DCDC_Istmodus_Cx3_Strom_ErstBn_ZusBn), 4=Cx4_Startunterstuetzung_ZusBn (CM_MF_DCDC_Istmodus_Cx4_Startunterstuetzung_ZusBn), 5=Cx5_Fehler (CM_MF_DCDC_Istmodus_Cx5_Fehler), 7=Cx7_Init (CM_MF_DCDC_Istmodus_Cx7_Init), 14=Cxe_Bypass (CM_MF_DCDC_Istmodus_Cxe_Bypass)}, range raw 0..14, transfer-property=PENDING, to SAM(timeout 1 s)  # aktuelle Betriebsart des NV DC/DC Wandlers
      frame MFL_01_XIX_E3V_K2CANFD: id 0x331, to SAM, frame-length=8, can-addressing-mode=STANDARD, can-frame-rx-behavior=CAN-FD, can-frame-tx-behavior=CAN-FD
        pdu MFL_01_XIX_E3V_K2CANFD: length=8, minimum-delay=0.003, transmission-mode-true-timing={cyclic-timing={time-offset=0.0, time-period=0.5}, event-controlled-timing={number-of-repetitions=0, repetition-period=0.0}}, unused-bit-pattern=0
          signal MFL_Zaehler_XIX_MFL_01_XIX_E3V_K2CANFD: start 0, 4 bit, little-endian, data-type-policy=OVERRIDE, i-signal-type=PRIMITIVE, init-value=0, base-type=BT_MFL_Zaehler, compu {phys=raw for raw 0..15}, range phys 0..15, raw 0..15, transfer-property=PENDING
          signal MFL_Toggle_XIX_MFL_01_XIX_E3V_K2CANFD: start 4, 1 bit, little-endian, data-type-policy=OVERRIDE, i-signal-type=PRIMITIVE, init-value=0, base-type=BT_MFL_Toggle, compu {phys=raw for raw 0..1}, range phys 0..1, raw 0..1, transfer-property=PENDING  # Watchdog Toggle-Bit
          signal MFL_Lokalaktiv_XIX_MFL_01_XIX_E3V_K2CANFD: start 5, 1 bit, little-endian, data-type-policy=OVERRIDE, i-signal-type=PRIMITIVE, init-value=0, base-type=BT_MFL_Lokalaktiv, compu {0=Cx0_war_nicht_lokal_aktiv (CM_MFL_Lokalaktiv_Cx0_war_nicht_lokal_aktiv), 1=Cx1_war_lokal_aktiv (CM_MFL_Lokalaktiv_Cx1_war_lokal_aktiv)}, range raw 0..1, transfer-property=PENDING  # Zeigt an ob das SG nach Klemme15 AUS und nach entsprechender MAX Aktivzeit noch aktiv war
          signal MFL_M_Taste_XIX_MFL_01_XIX_E3V_K2CANFD: start 6, 1 bit, little-endian, data-type-policy=OVERRIDE, i-signal-type=PRIMITIVE, init-value=0, base-type=BT_MFL_M_Taste, compu {0=Cx0_nicht_betaetigt (CM_MFL_M_Taste_Cx0_nicht_betaetigt), 1=Cx1_betaetigt (CM_MFL_M_Taste_Cx1_betaetigt)}, range raw 0..1, transfer-property=PENDING  # Taster für Umschaltung Automatik/manuelles Schalten (Tiptronic)
          signal MFL_Paddle_Verbau_XIX_MFL_01_XIX_E3V_K2CANFD: start 7, 1 bit, little-endian, data-type-policy=OVERRIDE, i-signal-type=PRIMITIVE, init-value=0, base-type=BT_MFL_Paddle_Verbau, compu {0=Cx0_verbaut (CM_MFL_Paddle_Verbau_Cx0_verbaut), 1=Cx1_nicht_verbaut (CM_MFL_Paddle_Verbau_Cx1_nicht_verbaut)}, range raw 0..1, transfer-property=PENDING  # Signalisiert den Zustand des Tipp-Paddle-Verbaus
          signal MFL_Tastencode_1_XIX_MFL_01_XIX_E3V_K2CANFD: start 8, 8 bit, little-endian, data-type-policy=OVERRIDE, i-signal-type=PRIMITIVE, init-value=0, base-type=BT_MFL_Tastencode_1, compu {0=Cx0_Key_Released_No_Key (CM_MFL_Tastencode_1_Cx0_Key_Released_No_Key) (Key_Released__No_Key), 1=Cx1_Context_Menu (CM_MFL_Tastencode_1_Cx1_Context_Menu), 2=Cx2_Menu_Up_Next_Screen (CM_MFL_Tastencode_1_Cx2_Menu_Up_Next_Screen) (Menu_Up__Next_Screen), 3=Cx3_Menu_Down_Previous_Screen (CM_MFL_Tastencode_1_Cx3_Menu_Down_Previous_Screen) (Menu_Down__Previous_Screen), 4=Cx4_Up (CM_MFL_Tastencode_1_Cx4_Up), 5=Cx5_Down (CM_MFL_Tastencode_1_Cx5_Down), 6=Cx6_Up_Down_ThumbWheel (CM_MFL_Tastencode_1_Cx6_Up_Down_ThumbWheel) (Up__Down_ThumbWheel), 7=Cx7_OK_ThumbWheel_Button (CM_MFL_Tastencode_1_Cx7_OK_ThumbWheel_Button) (OK__ThumbWheel_Button), 8=Cx8_Cancel_Escape (CM_MFL_Tastencode_1_Cx8_Cancel_Escape) (Cancel__Escape), 9=Cx9_Main_Menu (CM_MFL_Tastencode_1_Cx9_Main_Menu), 10=Cxa_Side_Menu_left (CM_MFL_Tastencode_1_Cxa_Side_Menu_left), 11=Cxb_Side_Menu_right (CM_MFL_Tastencode_1_Cxb_Side_Menu_right), 12=Cxc_FAS_Menu (CM_MFL_Tastencode_1_Cxc_FAS_Menu), 13=Cxd_Left_Right_ThumbWheel (CM_MFL_Tastencode_1_Cxd_Left_Right_ThumbWheel) (Left__Right_ThumbWheel), 14=Cxe_FAS_Menu_ThumbWheel (CM_MFL_Tastencode_1_Cxe_FAS_Menu_ThumbWheel), 16=Cx10_Volume_Up (CM_MFL_Tastencode_1_Cx10_Volume_Up), 17=Cx11_Volume_Down (CM_MFL_Tastencode_1_Cx11_Volume_Down), 18=Cx12_Volume_Up_Down_ThumbWheel (CM_MFL_Tastencode_1_Cx12_Volume_Up_Down_ThumbWheel) (Volume_Up__Down_ThumbWheel), 19=Cx13_Volume_ThumbWheel_Button (CM_MFL_Tastencode_1_Cx13_Volume_ThumbWheel_Button), 20=Cx14_Audio_Source (CM_MFL_Tastencode_1_Cx14_Audio_Source), 21=Cx15_Arrow_A_Up_Right (CM_MFL_Tastencode_1_Cx15_Arrow_A_Up_Right) (Arrow_A_Up__Right), 22=Cx16_Arrow_A_Down_Left (CM_MFL_Tastencode_1_Cx16_Arrow_A_Down_Left) (Arrow_A_Down__Left), 23=Cx17_Arrow_B_Up_Right (CM_MFL_Tastencode_1_Cx17_Arrow_B_Up_Right) (Arrow_B_Up__Right), 24=Cx18_Arrow_B_Down_Left (CM_MFL_Tastencode_1_Cx18_Arrow_B_Down_Left) (Arrow_B_Down__Left), 25=Cx19_PTT_PushToTalk (CM_MFL_Tastencode_1_Cx19_PTT_PushToTalk) (PTT__PushToTalk), 26=Cx1a_PTT_Cancel (CM_MFL_Tastencode_1_Cx1a_PTT_Cancel), 27=Cx1b_Route_Info (CM_MFL_Tastencode_1_Cx1b_Route_Info), 28=Cx1c_Hook (CM_MFL_Tastencode_1_Cx1c_Hook), 29=Cx1d_Hang_Up (CM_MFL_Tastencode_1_Cx1d_Hang_Up), 30=Cx1e_Off_Hook (CM_MFL_Tastencode_1_Cx1e_Off_Hook), 31=Cx1f_Light_On_Off (CM_MFL_Tastencode_1_Cx1f_Light_On_Off) (Light_On__Off), 32=Cx20_Mute (CM_MFL_Tastencode_1_Cx20_Mute), 33=Cx21_Joker1 (CM_MFL_Tastencode_1_Cx21_Joker1), 34=Cx22_Joker2 (CM_MFL_Tastencode_1_Cx22_Joker2), 35=Cx23_View (CM_MFL_Tastencode_1_Cx23_View), 36=Cx24_Arrow_A_Up_Down_ThumbWheel (CM_MFL_Tastencode_1_Cx24_Arrow_A_Up_Down_ThumbWheel) (Arrow_A_Up__Down_ThumbWheel), 37=Cx25_Lenkradheizung (CM_MFL_Tastencode_1_Cx25_Lenkradheizung), 38=Cx26_Rekuperation (CM_MFL_Tastencode_1_Cx26_Rekuperation), 39=Cx27_Tube_Toggle (CM_MFL_Tastencode_1_Cx27_Tube_Toggle), 40=Cx28_DRS_Drag_Reduction_System (CM_MFL_Tastencode_1_Cx28_DRS_Drag_Reduction_System), 41=Cx29_Stopwatch_Start_Stop (CM_MFL_Tastencode_1_Cx29_Stopwatch_Start_Stop), 42=Cx2a_Stopwatch_Nextlap (CM_MFL_Tastencode_1_Cx2a_Stopwatch_Nextlap), 43=Cx2b_HDF_High_Downforce (CM_MFL_Tastencode_1_Cx2b_HDF_High_Downforce), 100=Cx64_MAP (CM_MFL_Tastencode_1_Cx64_MAP), 101=Cx65_MAP_Boost (CM_MFL_Tastencode_1_Cx65_MAP_Boost), 102=Cx66_Turn_signal_left (CM_MFL_Tastencode_1_Cx66_Turn_signal_left), 103=Cx67_Turn_signal_right (CM_MFL_Tastencode_1_Cx67_Turn_signal_right), 104=Cx68_Turn_signal_off (CM_MFL_Tastencode_1_Cx68_Turn_signal_off), 105=Cx69_Flashlight (CM_MFL_Tastencode_1_Cx69_Flashlight), 106=Cx6a_Highbeam (CM_MFL_Tastencode_1_Cx6a_Highbeam), 107=Cx6b_Washer_button (CM_MFL_Tastencode_1_Cx6b_Washer_button), 108=Cx6c_Wiper_button_left (CM_MFL_Tastencode_1_Cx6c_Wiper_button_left), 109=Cx6d_Wiper_button_right (CM_MFL_Tastencode_1_Cx6d_Wiper_button_right), 110=Cx6e_Wiper_button_cancel (CM_MFL_Tastencode_1_Cx6e_Wiper_button_cancel), 111=Cx6f_Exhaust_Sound (CM_MFL_Tastencode_1_Cx6f_Exhaust_Sound), 112=Cx70_Drive_Select_button (CM_MFL_Tastencode_1_Cx70_Drive_Select_button), 113=Cx71_Sport_button (CM_MFL_Tastencode_1_Cx71_Sport_button), 114=Cx72_ESP_Drift_Selection_ThumbWheel (CM_MFL_Tastencode_1_Cx72_ESP_Drift_Selection_ThumbWheel), 115=Cx73_PTT_special_vehicle (CM_MFL_Tastencode_1_Cx73_PTT_special_vehicle), 116=Cx74_TravelAssist (CM_MFL_Tastencode_1_Cx74_TravelAssist), 117=Cx75_Launch_Control (CM_MFL_Tastencode_1_Cx75_Launch_Control), 118=Cx76_Drift_Mode_Button_Increase (CM_MFL_Tastencode_1_Cx76_Drift_Mode_Button_Increase), 119=Cx77_Drift_Mode_Button_Decrease (CM_MFL_Tastencode_1_Cx77_Drift_Mode_Button_Decrease), 120=Cx78_Drift_Mode_Button_Select (CM_MFL_Tastencode_1_Cx78_Drift_Mode_Button_Select), 121=Cx79_Drive_Mode_Button_Increase (CM_MFL_Tastencode_1_Cx79_Drive_Mode_Button_Increase), 122=Cx7a_Drive_Mode_Button_Decrease (CM_MFL_Tastencode_1_Cx7a_Drive_Mode_Button_Decrease), 123=Cx7b_Drive_Mode_Button_Select (CM_MFL_Tastencode_1_Cx7b_Drive_Mode_Button_Select), 124=Cx7c_E_Boost_Button_Increase (CM_MFL_Tastencode_1_Cx7c_E_Boost_Button_Increase), 125=Cx7d_E_Boost_Button_Decrease (CM_MFL_Tastencode_1_Cx7d_E_Boost_Button_Decrease), 126=Cx7e_E_Boost_Button_Select (CM_MFL_Tastencode_1_Cx7e_E_Boost_Button_Select), 127=Cx7f_PerformanceHybridButton_Increase (CM_MFL_Tastencode_1_Cx7f_PerformanceHybridButton_Increase), 128=Cx80_PerformanceHybridButton_Decrease (CM_MFL_Tastencode_1_Cx80_PerformanceHybridButton_Decrease), 129=Cx81_EV_Mode_Button (CM_MFL_Tastencode_1_Cx81_EV_Mode_Button), 130=Cx82_HUD_Button (CM_MFL_Tastencode_1_Cx82_HUD_Button), 131=Cx83_PASM_Wheel (CM_MFL_Tastencode_1_Cx83_PASM_Wheel), 132=Cx84_PASM_Button (CM_MFL_Tastencode_1_Cx84_PASM_Button), 133=Cx85_PTV_Wheel (CM_MFL_Tastencode_1_Cx85_PTV_Wheel), 134=Cx86_PTV_Button (CM_MFL_Tastencode_1_Cx86_PTV_Button), 135=Cx87_TC_ESC_Wheel (CM_MFL_Tastencode_1_Cx87_TC_ESC_Wheel), 136=Cx88_TC_ESC_Button (CM_MFL_Tastencode_1_Cx88_TC_ESC_Button), 137=Cx89_aLDW_Button (CM_MFL_Tastencode_1_Cx89_aLDW_Button), 169=Cxa9_VirtualGearbox_Button (CM_MFL_Tastencode_1_Cxa9_VirtualGearbox_Button), 170=Cxaa_VirtualGearbox_Wheel (CM_MFL_Tastencode_1_Cxaa_VirtualGearbox_Wheel), 240=Cxf0_Startup_Reset (CM_MFL_Tastencode_1_Cxf0_Startup_Reset), 241=Cxf1_Initialization (CM_MFL_Tastencode_1_Cxf1_Initialization)}, range raw 0..241, transfer-property=PENDING  # Beschreibt die Funktion einer fest zugeordneten Taste/Walze auf dem MFL. Bei Betätigung ändert sich der Wert von 0x0 auf den jeweiligen Tastencode.
          signal MFL_Tastencode_2_XIX_MFL_01_XIX_E3V_K2CANFD: start 16, 8 bit, little-endian, data-type-policy=OVERRIDE, i-signal-type=PRIMITIVE, init-value=0, base-type=BT_MFL_Tastencode_2, compu {0=Cx0_Key_Released_No_Key (CM_MFL_Tastencode_2_Cx0_Key_Released_No_Key) (Key_Released__No_Key), 1=Cx1_Context_Menu (CM_MFL_Tastencode_2_Cx1_Context_Menu), 2=Cx2_Menu_Up_Next_Screen (CM_MFL_Tastencode_2_Cx2_Menu_Up_Next_Screen) (Menu_Up__Next_Screen), 3=Cx3_Menu_Down_Previous_Screen (CM_MFL_Tastencode_2_Cx3_Menu_Down_Previous_Screen) (Menu_Down__Previous_Screen), 4=Cx4_Up (CM_MFL_Tastencode_2_Cx4_Up), 5=Cx5_Down (CM_MFL_Tastencode_2_Cx5_Down), 6=Cx6_Up_Down_ThumbWheel (CM_MFL_Tastencode_2_Cx6_Up_Down_ThumbWheel) (Up__Down_ThumbWheel), 7=Cx7_OK_ThumbWheel_Button (CM_MFL_Tastencode_2_Cx7_OK_ThumbWheel_Button) (OK__ThumbWheel_Button), 8=Cx8_Cancel_Escape (CM_MFL_Tastencode_2_Cx8_Cancel_Escape) (Cancel__Escape), 9=Cx9_Main_Menu (CM_MFL_Tastencode_2_Cx9_Main_Menu), 10=Cxa_Side_Menu_left (CM_MFL_Tastencode_2_Cxa_Side_Menu_left), 11=Cxb_Side_Menu_right (CM_MFL_Tastencode_2_Cxb_Side_Menu_right), 12=Cxc_FAS_Menu (CM_MFL_Tastencode_2_Cxc_FAS_Menu), 13=Cxd_Left_Right_ThumbWheel (CM_MFL_Tastencode_2_Cxd_Left_Right_ThumbWheel) (Left__Right_ThumbWheel), 14=Cxe_FAS_Menu_ThumbWheel (CM_MFL_Tastencode_2_Cxe_FAS_Menu_ThumbWheel), 16=Cx10_Volume_Up (CM_MFL_Tastencode_2_Cx10_Volume_Up), 17=Cx11_Volume_Down (CM_MFL_Tastencode_2_Cx11_Volume_Down), 18=Cx12_Volume_Up_Down_ThumbWheel (CM_MFL_Tastencode_2_Cx12_Volume_Up_Down_ThumbWheel) (Volume_Up__Down_ThumbWheel), 19=Cx13_Volume_ThumbWheel_Button (CM_MFL_Tastencode_2_Cx13_Volume_ThumbWheel_Button), 20=Cx14_Audio_Source (CM_MFL_Tastencode_2_Cx14_Audio_Source), 21=Cx15_Arrow_A_Up_Right (CM_MFL_Tastencode_2_Cx15_Arrow_A_Up_Right) (Arrow_A_Up__Right), 22=Cx16_Arrow_A_Down_Left (CM_MFL_Tastencode_2_Cx16_Arrow_A_Down_Left) (Arrow_A_Down__Left), 23=Cx17_Arrow_B_Up_Right (CM_MFL_Tastencode_2_Cx17_Arrow_B_Up_Right) (Arrow_B_Up__Right), 24=Cx18_Arrow_B_Down_Left (CM_MFL_Tastencode_2_Cx18_Arrow_B_Down_Left) (Arrow_B_Down__Left), 25=Cx19_PTT_PushToTalk (CM_MFL_Tastencode_2_Cx19_PTT_PushToTalk) (PTT__PushToTalk), 26=Cx1a_PTT_Cancel (CM_MFL_Tastencode_2_Cx1a_PTT_Cancel), 27=Cx1b_Route_Info (CM_MFL_Tastencode_2_Cx1b_Route_Info), 28=Cx1c_Hook (CM_MFL_Tastencode_2_Cx1c_Hook), 29=Cx1d_Hang_Up (CM_MFL_Tastencode_2_Cx1d_Hang_Up), 30=Cx1e_Off_Hook (CM_MFL_Tastencode_2_Cx1e_Off_Hook), 31=Cx1f_Light_On_Off (CM_MFL_Tastencode_2_Cx1f_Light_On_Off) (Light_On__Off), 32=Cx20_Mute (CM_MFL_Tastencode_2_Cx20_Mute), 33=Cx21_Joker1 (CM_MFL_Tastencode_2_Cx21_Joker1), 34=Cx22_Joker2 (CM_MFL_Tastencode_2_Cx22_Joker2), 35=Cx23_View (CM_MFL_Tastencode_2_Cx23_View), 36=Cx24_Arrow_A_Up_Down_ThumbWheel (CM_MFL_Tastencode_2_Cx24_Arrow_A_Up_Down_ThumbWheel) (Arrow_A_Up__Down_ThumbWheel), 37=Cx25_Lenkradheizung (CM_MFL_Tastencode_2_Cx25_Lenkradheizung), 38=Cx26_Rekuperation (CM_MFL_Tastencode_2_Cx26_Rekuperation), 39=Cx27_Tube_Toggle (CM_MFL_Tastencode_2_Cx27_Tube_Toggle), 40=Cx28_DRS_Drag_Reduction_System (CM_MFL_Tastencode_2_Cx28_DRS_Drag_Reduction_System), 41=Cx29_Stopwatch_Start_Stop (CM_MFL_Tastencode_2_Cx29_Stopwatch_Start_Stop), 42=Cx2a_Stopwatch_Nextlap (CM_MFL_Tastencode_2_Cx2a_Stopwatch_Nextlap), 43=Cx2b_HDF_High_Downforce (CM_MFL_Tastencode_2_Cx2b_HDF_High_Downforce), 100=Cx64_MAP (CM_MFL_Tastencode_2_Cx64_MAP), 101=Cx65_MAP_Boost (CM_MFL_Tastencode_2_Cx65_MAP_Boost), 102=Cx66_Turn_signal_left (CM_MFL_Tastencode_2_Cx66_Turn_signal_left), 103=Cx67_Turn_signal_right (CM_MFL_Tastencode_2_Cx67_Turn_signal_right), 104=Cx68_Turn_signal_off (CM_MFL_Tastencode_2_Cx68_Turn_signal_off), 105=Cx69_Flashlight (CM_MFL_Tastencode_2_Cx69_Flashlight), 106=Cx6a_Highbeam (CM_MFL_Tastencode_2_Cx6a_Highbeam), 107=Cx6b_Washer_button (CM_MFL_Tastencode_2_Cx6b_Washer_button), 108=Cx6c_Wiper_button_left (CM_MFL_Tastencode_2_Cx6c_Wiper_button_left), 109=Cx6d_Wiper_button_right (CM_MFL_Tastencode_2_Cx6d_Wiper_button_right), 110=Cx6e_Wiper_button_cancel (CM_MFL_Tastencode_2_Cx6e_Wiper_button_cancel), 111=Cx6f_Exhaust_Sound (CM_MFL_Tastencode_2_Cx6f_Exhaust_Sound), 112=Cx70_Drive_Select_button (CM_MFL_Tastencode_2_Cx70_Drive_Select_button), 113=Cx71_Sport_button (CM_MFL_Tastencode_2_Cx71_Sport_button), 114=Cx72_ESP_Drift_Selection_ThumbWheel (CM_MFL_Tastencode_2_Cx72_ESP_Drift_Selection_ThumbWheel), 115=Cx73_PTT_special_vehicle (CM_MFL_Tastencode_2_Cx73_PTT_special_vehicle), 116=Cx74_TravelAssist (CM_MFL_Tastencode_2_Cx74_TravelAssist), 117=Cx75_Launch_Control (CM_MFL_Tastencode_2_Cx75_Launch_Control), 118=Cx76_Drift_Mode_Button_Increase (CM_MFL_Tastencode_2_Cx76_Drift_Mode_Button_Increase), 119=Cx77_Drift_Mode_Button_Decrease (CM_MFL_Tastencode_2_Cx77_Drift_Mode_Button_Decrease), 120=Cx78_Drift_Mode_Button_Select (CM_MFL_Tastencode_2_Cx78_Drift_Mode_Button_Select), 121=Cx79_Drive_Mode_Button_Increase (CM_MFL_Tastencode_2_Cx79_Drive_Mode_Button_Increase), 122=Cx7a_Drive_Mode_Button_Decrease (CM_MFL_Tastencode_2_Cx7a_Drive_Mode_Button_Decrease), 123=Cx7b_Drive_Mode_Button_Select (CM_MFL_Tastencode_2_Cx7b_Drive_Mode_Button_Select), 124=Cx7c_E_Boost_Button_Increase (CM_MFL_Tastencode_2_Cx7c_E_Boost_Button_Increase), 125=Cx7d_E_Boost_Button_Decrease (CM_MFL_Tastencode_2_Cx7d_E_Boost_Button_Decrease), 126=Cx7e_E_Boost_Button_Select (CM_MFL_Tastencode_2_Cx7e_E_Boost_Button_Select), 127=Cx7f_PerformanceHybridButton_Increase (CM_MFL_Tastencode_2_Cx7f_PerformanceHybridButton_Increase), 128=Cx80_PerformanceHybridButton_Decrease (CM_MFL_Tastencode_2_Cx80_PerformanceHybridButton_Decrease), 129=Cx81_EV_Mode_Button (CM_MFL_Tastencode_2_Cx81_EV_Mode_Button), 130=Cx82_HUD_Button (CM_MFL_Tastencode_2_Cx82_HUD_Button), 131=Cx83_PASM_Wheel (CM_MFL_Tastencode_2_Cx83_PASM_Wheel), 132=Cx84_PASM_Button (CM_MFL_Tastencode_2_Cx84_PASM_Button), 133=Cx85_PTV_Wheel (CM_MFL_Tastencode_2_Cx85_PTV_Wheel), 134=Cx86_PTV_Button (CM_MFL_Tastencode_2_Cx86_PTV_Button), 135=Cx87_TC_ESC_Wheel (CM_MFL_Tastencode_2_Cx87_TC_ESC_Wheel), 136=Cx88_TC_ESC_Button (CM_MFL_Tastencode_2_Cx88_TC_ESC_Button), 137=Cx89_aLDW_Button (CM_MFL_Tastencode_2_Cx89_aLDW_Button), 169=Cxa9_VirtualGearbox_Button (CM_MFL_Tastencode_2_Cxa9_VirtualGearbox_Button), 170=Cxaa_VirtualGearbox_Wheel (CM_MFL_Tastencode_2_Cxaa_VirtualGearbox_Wheel), 240=Cxf0_Startup_Reset (CM_MFL_Tastencode_2_Cxf0_Startup_Reset), 241=Cxf1_Initialization (CM_MFL_Tastencode_2_Cxf1_Initialization)}, range raw 0..241, transfer-property=PENDING  # Beschreibt die Funktion einer fest zugeordneten Taste/Walze auf dem MFL. Ist MFL_Tastencode_1 wegen Betätigung einer Taste/Walze bereits mit einem Wert ungleich 0x0 belegt, so ändert sich bei Betätigung einer weiteren Taste/Walze der Wert dieses Signals von 0x0 auf den jeweiligen Tastencode.
          signal MFL_Eventcode_1_XIX_MFL_01_XIX_E3V_K2CANFD: start 24, 4 bit, little-endian, data-type-policy=OVERRIDE, i-signal-type=PRIMITIVE, init-value=0, base-type=BT_MFL_Eventcode_1, compu {0=Cx0_W_no_event_T_no_event (CM_MFL_Eventcode_1_Cx0_W_no_event_T_no_event) (W_no_event____T_no_event), 1=Cx1_W_1_Tick_up_T_pressed_normal (CM_MFL_Eventcode_1_Cx1_W_1_Tick_up_T_pressed_normal) (W_1_Tick_up__T_pressed_normal), 2=Cx2_W_2_Ticks_up_T_touched (CM_MFL_Eventcode_1_Cx2_W_2_Ticks_up_T_touched) (W_2_Ticks_up__T_touched), 3=Cx3_W_3_Ticks_up_T_double_click_nor (CM_MFL_Eventcode_1_Cx3_W_3_Ticks_up_T_double_click_nor) (W_3_Ticks_up__T_double_click_nor), 4=Cx4_W_4_Ticks_up_T_long_press_nor_1 (CM_MFL_Eventcode_1_Cx4_W_4_Ticks_up_T_long_press_nor_1) (W_4_Ticks_up__T_long_press_nor_1), 5=Cx5_W_5_Ticks_up_T_long_press_nor_2 (CM_MFL_Eventcode_1_Cx5_W_5_Ticks_up_T_long_press_nor_2) (W_5_Ticks_up__T_long_press_nor_2), 6=Cx6_W_6_Ticks_up_T_long_press_nor_3 (CM_MFL_Eventcode_1_Cx6_W_6_Ticks_up_T_long_press_nor_3) (W_6_Ticks_up__T_long_press_nor_3), 7=Cx7_W_7_Ticks_up (CM_MFL_Eventcode_1_Cx7_W_7_Ticks_up), 9=Cx9_W_7_Ticks_dn_T_pressed_strong (CM_MFL_Eventcode_1_Cx9_W_7_Ticks_dn_T_pressed_strong) (W_7_Ticks_dn__T_pressed_strong), 10=Cxa_W_6_Ticks_dn (CM_MFL_Eventcode_1_Cxa_W_6_Ticks_dn), 11=Cxb_W_5_Ticks_dn_T_double_click_str (CM_MFL_Eventcode_1_Cxb_W_5_Ticks_dn_T_double_click_str) (W_5_Ticks_dn__T_double_click_str), 12=Cxc_W_4_Ticks_dn_T_long_press_str_1 (CM_MFL_Eventcode_1_Cxc_W_4_Ticks_dn_T_long_press_str_1) (W_4_Ticks_dn__T_long_press_str_1), 13=Cxd_W_3_Ticks_dn_T_long_press_str_2 (CM_MFL_Eventcode_1_Cxd_W_3_Ticks_dn_T_long_press_str_2) (W_3_Ticks_dn__T_long_press_str_2), 14=Cxe_W_2_Ticks_dn_T_long_press_str_3 (CM_MFL_Eventcode_1_Cxe_W_2_Ticks_dn_T_long_press_str_3) (W_2_Ticks_dn__T_long_press_str_3), 15=Cxf_W_1_Tick_dn (CM_MFL_Eventcode_1_Cxf_W_1_Tick_dn)}, range raw 0..15, transfer-property=PENDING  # Siehe Q-LAH MFL-Protokoll
          signal MFL_Eventcode_2_XIX_MFL_01_XIX_E3V_K2CANFD: start 28, 4 bit, little-endian, data-type-policy=OVERRIDE, i-signal-type=PRIMITIVE, init-value=0, base-type=BT_MFL_Eventcode_2, compu {0=Cx0_W_no_event_T_no_event (CM_MFL_Eventcode_2_Cx0_W_no_event_T_no_event) (W_no_event____T_no_event), 1=Cx1_W_1_Tick_up_T_pressed_normal (CM_MFL_Eventcode_2_Cx1_W_1_Tick_up_T_pressed_normal) (W_1_Tick_up__T_pressed_normal), 2=Cx2_W_2_Ticks_up_T_touched (CM_MFL_Eventcode_2_Cx2_W_2_Ticks_up_T_touched) (W_2_Ticks_up__T_touched), 3=Cx3_W_3_Ticks_up_T_double_click_nor (CM_MFL_Eventcode_2_Cx3_W_3_Ticks_up_T_double_click_nor) (W_3_Ticks_up__T_double_click_nor), 4=Cx4_W_4_Ticks_up_T_long_press_nor_1 (CM_MFL_Eventcode_2_Cx4_W_4_Ticks_up_T_long_press_nor_1) (W_4_Ticks_up__T_long_press_nor_1), 5=Cx5_W_5_Ticks_up_T_long_press_nor_2 (CM_MFL_Eventcode_2_Cx5_W_5_Ticks_up_T_long_press_nor_2) (W_5_Ticks_up__T_long_press_nor_2), 6=Cx6_W_6_Ticks_up_T_long_press_nor_3 (CM_MFL_Eventcode_2_Cx6_W_6_Ticks_up_T_long_press_nor_3) (W_6_Ticks_up__T_long_press_nor_3), 7=Cx7_W_7_Ticks_up (CM_MFL_Eventcode_2_Cx7_W_7_Ticks_up), 9=Cx9_W_7_Ticks_dn_T_pressed_strong (CM_MFL_Eventcode_2_Cx9_W_7_Ticks_dn_T_pressed_strong) (W_7_Ticks_dn__T_pressed_strong), 10=Cxa_W_6_Ticks_dn (CM_MFL_Eventcode_2_Cxa_W_6_Ticks_dn), 11=Cxb_W_5_Ticks_dn_T_double_click_str (CM_MFL_Eventcode_2_Cxb_W_5_Ticks_dn_T_double_click_str) (W_5_Ticks_dn__T_double_click_str), 12=Cxc_W_4_Ticks_dn_T_long_press_str_1 (CM_MFL_Eventcode_2_Cxc_W_4_Ticks_dn_T_long_press_str_1) (W_4_Ticks_dn__T_long_press_str_1), 13=Cxd_W_3_Ticks_dn_T_long_press_str_2 (CM_MFL_Eventcode_2_Cxd_W_3_Ticks_dn_T_long_press_str_2) (W_3_Ticks_dn__T_long_press_str_2), 14=Cxe_W_2_Ticks_dn_T_long_press_str_3 (CM_MFL_Eventcode_2_Cxe_W_2_Ticks_dn_T_long_press_str_3) (W_2_Ticks_dn__T_long_press_str_3), 15=Cxf_W_1_Tick_dn (CM_MFL_Eventcode_2_Cxf_W_1_Tick_dn)}, range raw 0..15, transfer-property=PENDING  # Siehe Q-LAH MFL-Protokoll
          signal MFL_Marke_XIX_MFL_01_XIX_E3V_K2CANFD: start 32, 4 bit, little-endian, data-type-policy=OVERRIDE, i-signal-type=PRIMITIVE, base-type=BT_MFL_Marke, compu {0=Cx0_VW (CM_MFL_Marke_Cx0_VW), 1=Cx1_Audi (CM_MFL_Marke_Cx1_Audi), 2=Cx2_Seat (CM_MFL_Marke_Cx2_Seat), 3=Cx3_Skoda (CM_MFL_Marke_Cx3_Skoda), 4=Cx4_VW_Nutzf (CM_MFL_Marke_Cx4_VW_Nutzf), 5=Cx5_Bugatti (CM_MFL_Marke_Cx5_Bugatti), 6=Cx6_Lamborghini (CM_MFL_Marke_Cx6_Lamborghini), 7=Cx7_Bentley (CM_MFL_Marke_Cx7_Bentley), 8=Cx8_Rolls_Royce (CM_MFL_Marke_Cx8_Rolls_Royce) (Rolls Royce), 9=Cx9_Quattro (CM_MFL_Marke_Cx9_Quattro), 10=Cxa_kein_Hersteller_1 (CM_MFL_Marke_Cxa_kein_Hersteller_1), 11=Cxb_kein_Hersteller_2 (CM_MFL_Marke_Cxb_kein_Hersteller_2), 12=Cxc_kein_Hersteller_3 (CM_MFL_Marke_Cxc_kein_Hersteller_3), 13=Cxd_kein_Hersteller_4 (CM_MFL_Marke_Cxd_kein_Hersteller_4), 14=Cxe_Ford (CM_MFL_Marke_Cxe_Ford), 15=Cxf_Porsche (CM_MFL_Marke_Cxf_Porsche)}, range raw 0..15, transfer-property=PENDING  # Marke für markenspezifische Variantennummer des MFL
          signal MFL_Variante_XIX_MFL_01_XIX_E3V_K2CANFD: start 36, 4 bit, little-endian, data-type-policy=OVERRIDE, i-signal-type=PRIMITIVE, base-type=BT_MFL_Variante, compu {phys=raw for raw 0..15}, range phys 0..15, raw 0..15, transfer-property=PENDING  # Markenspezifische Variantennummer des MFL
          signal MFL_Dummy_0_Signal_1_XIX_MFL_01_XIX_E3V_K2CANFD: start 40, 8 bit, little-endian, data-type-policy=OVERRIDE, i-signal-type=PRIMITIVE, init-value=0, base-type=BT_MFL_Dummy_0_Signal_1, transfer-property=PENDING
          signal MFL_Tip_Down_XIX_MFL_01_XIX_E3V_K2CANFD: start 48, 1 bit, little-endian, data-type-policy=OVERRIDE, i-signal-type=PRIMITIVE, init-value=0, base-type=BT_MFL_Tip_Down, compu {0=Cx0_nicht_betaetigt (CM_MFL_Tip_Down_Cx0_nicht_betaetigt), 1=Cx1_betaetigt (CM_MFL_Tip_Down_Cx1_betaetigt)}, range raw 0..1, transfer-property=TRIGGERED-ON-CHANGE-WITHOUT-REPETITION  # MFL-Tiptronic Tasten vom MFL für Getriebe 0x0 = kein Tip_Down 0x1 = Tip_Down
          signal MFL_Tip_Up_XIX_MFL_01_XIX_E3V_K2CANFD: start 49, 1 bit, little-endian, data-type-policy=OVERRIDE, i-signal-type=PRIMITIVE, init-value=0, base-type=BT_MFL_Tip_Up, compu {0=Cx0_nicht_betaetigt (CM_MFL_Tip_Up_Cx0_nicht_betaetigt), 1=Cx1_betaetigt (CM_MFL_Tip_Up_Cx1_betaetigt)}, range raw 0..1, transfer-property=TRIGGERED-ON-CHANGE-WITHOUT-REPETITION  # MFL-Tiptronic Tasten vom MFL für Getriebe 0x0 = kein Tip_Up 0x1 = Tip_Up
          signal MFL_SatModul_links_Err_XIX_MFL_01_XIX_E3V_K2CANFD: start 50, 1 bit, little-endian, data-type-policy=OVERRIDE, i-signal-type=PRIMITIVE, init-value=0, base-type=BT_MFL_SatModul_links_Err, invalid-value=Invalid_MFL_SatModul_links_Err_XIX_MFL_01_XIX_E3V_K2CANFD:1, compu {0=Cx0_kein_Fehler (CM_MFL_SatModul_links_Err_Cx0_kein_Fehler), 1=Cx1_Fehler (CM_MFL_SatModul_links_Err_Cx1_Fehler)}, range raw 0..1, transfer-property=PENDING  # Schalter Tastermodul links Fehler
          signal MFL_SatModul_rechts_Err_XIX_MFL_01_XIX_E3V_K2CANFD: start 51, 1 bit, little-endian, data-type-policy=OVERRIDE, i-signal-type=PRIMITIVE, init-value=0, base-type=BT_MFL_SatModul_rechts_Err, invalid-value=Invalid_MFL_SatModul_rechts_Err_XIX_MFL_01_XIX_E3V_K2CANFD:1, compu {0=Cx0_kein_Fehler (CM_MFL_SatModul_rechts_Err_Cx0_kein_Fehler), 1=Cx1_Fehler (CM_MFL_SatModul_rechts_Err_Cx1_Fehler)}, range raw 0..1, transfer-property=PENDING  # Schalter Tastermodul rechts Fehler
          signal MFL_Fehler_Codierung_XIX_MFL_01_XIX_E3V_K2CANFD: start 52, 1 bit, little-endian, data-type-policy=OVERRIDE, i-signal-type=PRIMITIVE, init-value=0, base-type=BT_MFL_Fehler_Codierung, invalid-value=Invalid_MFL_Fehler_Codierung_XIX_MFL_01_XIX_E3V_K2CANFD:1, compu {0=Cx0_kein_Fehler (CM_MFL_Fehler_Codierung_Cx0_kein_Fehler), 1=Cx1_Fehler (CM_MFL_Fehler_Codierung_Cx1_Fehler)}, range raw 0..1, transfer-property=PENDING  # Erkennung dass MFL nicht codiert ist.
          signal MFL_Dummy_0_Signal_3_XIX_MFL_01_XIX_E3V_K2CANFD: start 53, 1 bit, little-endian, data-type-policy=OVERRIDE, i-signal-type=PRIMITIVE, init-value=0, base-type=BT_MFL_Dummy_0_Signal_3, transfer-property=PENDING
          signal MFL_LR_HZG_Status_XIX_MFL_01_XIX_E3V_K2CANFD: start 54, 1 bit, little-endian, data-type-policy=OVERRIDE, i-signal-type=PRIMITIVE, init-value=0, base-type=BT_MFL_LR_HZG_Status, compu {0=Cx0_inaktiv (CM_MFL_LR_HZG_Status_Cx0_inaktiv), 1=Cx1_aktiv (CM_MFL_LR_HZG_Status_Cx1_aktiv)}, range raw 0..1, transfer-property=PENDING  # Status Lenkradheizung
          signal MFL_LR_HZG_Err_XIX_MFL_01_XIX_E3V_K2CANFD: start 55, 1 bit, little-endian, data-type-policy=OVERRIDE, i-signal-type=PRIMITIVE, init-value=0, base-type=BT_MFL_LR_HZG_Err, invalid-value=Invalid_MFL_LR_HZG_Err_XIX_MFL_01_XIX_E3V_K2CANFD:1, compu {0=Cx0_normal (CM_MFL_LR_HZG_Err_Cx0_normal), 1=Cx1_Fehler (CM_MFL_LR_HZG_Err_Cx1_Fehler)}, range raw 0..1, transfer-property=PENDING  # Lenkradheizung Fehler
          signal MFL_Signalhorn_XIX_MFL_01_XIX_E3V_K2CANFD: start 56, 1 bit, little-endian, data-type-policy=OVERRIDE, i-signal-type=PRIMITIVE, init-value=0, base-type=BT_MFL_Signalhorn, compu {0=Cx0_nicht_betaetigt (CM_MFL_Signalhorn_Cx0_nicht_betaetigt), 1=Cx1_betaetigt (CM_MFL_Signalhorn_Cx1_betaetigt)}, range raw 0..1, transfer-property=PENDING, to SAM(timeout 5 s)  # Signalhorn nicht betaetigt/betaetigt
          signal MFL_Signalhorn_Err_XIX_MFL_01_XIX_E3V_K2CANFD: start 57, 1 bit, little-endian, data-type-policy=OVERRIDE, i-signal-type=PRIMITIVE, init-value=0, base-type=BT_MFL_Signalhorn_Err, invalid-value=Invalid_MFL_Signalhorn_Err_XIX_MFL_01_XIX_E3V_K2CANFD:1, compu {0=Cx0_normal (CM_MFL_Signalhorn_Err_Cx0_normal), 1=Cx1_Fehler (CM_MFL_Signalhorn_Err_Cx1_Fehler)}, range raw 0..1, transfer-property=PENDING  # Signalhorn Fehler
          signal MFL_Tip_links_Err_XIX_MFL_01_XIX_E3V_K2CANFD: start 58, 1 bit, little-endian, data-type-policy=OVERRIDE, i-signal-type=PRIMITIVE, init-value=0, base-type=BT_MFL_Tip_links_Err, invalid-value=Invalid_MFL_Tip_links_Err_XIX_MFL_01_XIX_E3V_K2CANFD:1, compu {0=Cx0_normal (CM_MFL_Tip_links_Err_Cx0_normal), 1=Cx1_Fehler (CM_MFL_Tip_links_Err_Cx1_Fehler)}, range raw 0..1, transfer-property=PENDING  # Tiptronic links Fehler
          signal MFL_Tip_rechts_Err_XIX_MFL_01_XIX_E3V_K2CANFD: start 59, 1 bit, little-endian, data-type-policy=OVERRIDE, i-signal-type=PRIMITIVE, init-value=0, base-type=BT_MFL_Tip_rechts_Err, invalid-value=Invalid_MFL_Tip_rechts_Err_XIX_MFL_01_XIX_E3V_K2CANFD:1, compu {0=Cx0_normal (CM_MFL_Tip_rechts_Err_Cx0_normal), 1=Cx1_Fehler (CM_MFL_Tip_rechts_Err_Cx1_Fehler)}, range raw 0..1, transfer-property=PENDING  # Tiptronic rechts Fehler
          signal MFL_Taste_links_Err_XIX_MFL_01_XIX_E3V_K2CANFD: start 60, 1 bit, little-endian, data-type-policy=OVERRIDE, i-signal-type=PRIMITIVE, init-value=0, base-type=BT_MFL_Taste_links_Err, invalid-value=Invalid_MFL_Taste_links_Err_XIX_MFL_01_XIX_E3V_K2CANFD:1, compu {0=Cx0_normal (CM_MFL_Taste_links_Err_Cx0_normal), 1=Cx1_Fehler (CM_MFL_Taste_links_Err_Cx1_Fehler)}, range raw 0..1, transfer-property=PENDING  # MFL_Tastenblock links Fehler
          signal MFL_Taste_rechts_Err_XIX_MFL_01_XIX_E3V_K2CANFD: start 61, 1 bit, little-endian, data-type-policy=OVERRIDE, i-signal-type=PRIMITIVE, init-value=0, base-type=BT_MFL_Taste_rechts_Err, invalid-value=Invalid_MFL_Taste_rechts_Err_XIX_MFL_01_XIX_E3V_K2CANFD:1, compu {0=Cx0_normal (CM_MFL_Taste_rechts_Err_Cx0_normal), 1=Cx1_Fehler (CM_MFL_Taste_rechts_Err_Cx1_Fehler)}, range raw 0..1, transfer-property=PENDING  # MFL_Tastenblock rechts Fehler
          signal MFL_ECU_Err_XIX_MFL_01_XIX_E3V_K2CANFD: start 62, 1 bit, little-endian, data-type-policy=OVERRIDE, i-signal-type=PRIMITIVE, init-value=0, base-type=BT_MFL_ECU_Err, invalid-value=Invalid_MFL_ECU_Err_XIX_MFL_01_XIX_E3V_K2CANFD:1, compu {0=Cx0_normal (CM_MFL_ECU_Err_Cx0_normal), 1=Cx1_Fehler (CM_MFL_ECU_Err_Cx1_Fehler)}, range raw 0..1, transfer-property=PENDING  # MFL-µC Fehler
          signal MFL_Response_Err_XIX_MFL_01_XIX_E3V_K2CANFD: start 63, 1 bit, little-endian, data-type-policy=OVERRIDE, i-signal-type=PRIMITIVE, init-value=0, base-type=BT_MFL_Response_Err, invalid-value=Invalid_MFL_Response_Err_XIX_MFL_01_XIX_E3V_K2CANFD:1, compu {0=Cx0_normal (CM_MFL_Response_Err_Cx0_normal), 1=Cx1_Fehler (CM_MFL_Response_Err_Cx1_Fehler)}, range raw 0..1, transfer-property=PENDING  # siehe LIN2.0-Specification (Darf nicht über ein Fehlergueltigkeitsbit abgesichtert werden!)
      frame Motor_14_XIX_E3V_K2CANFD: id 0x3BE, to SAM, frame-length=8, can-addressing-mode=STANDARD, can-frame-rx-behavior=CAN-FD, can-frame-tx-behavior=CAN-FD
        pdu Motor_14_XIX_E3V_K2CANFD: length=8, minimum-delay=0.01, transmission-mode-true-timing={cyclic-timing={time-offset=0.0, time-period=0.1}, event-controlled-timing={number-of-repetitions=0, repetition-period=0.0}}, unused-bit-pattern=0
          signal Motor_14_CRC_XIX_Motor_14_XIX_E3V_K2CANFD: start 0, 8 bit, little-endian, data-type-policy=OVERRIDE, i-signal-type=PRIMITIVE, base-type=BT_Motor_14_CRC, compu {phys=raw for raw 0..255}, range phys 0..255, raw 0..255, transfer-property=PENDING  # Ab MQB und MLBevo: "Berechnung siehe Lastenheft "End-to-End Kommunikationsabsicherung" Endwerte siehe Begleitdokument "S-PDU Kennungsfolgen"
          signal Motor_14_BZ_XIX_Motor_14_XIX_E3V_K2CANFD: start 8, 4 bit, little-endian, data-type-policy=OVERRIDE, i-signal-type=PRIMITIVE, base-type=BT_Motor_14_BZ, compu {phys=raw for raw 0..15}, range phys 0..15, raw 0..15, transfer-property=PENDING
          signal MO_StartStopp_Status_XIX_Motor_14_XIX_E3V_K2CANFD: start 12, 2 bit, little-endian, data-type-policy=OVERRIDE, i-signal-type=PRIMITIVE, init-value=0, base-type=BT_MO_StartStopp_Status, compu {0=Cx0_System_in_diesem_KL15_Zyklus_nicht_verfuegbar (CM_MO_StartStopp_Status_Cx0_System_in_diesem_KL15_Zyklus_nicht_verfuegbar), 1=Cx1_System_aktiv_keine_Freigabe_durch_StartStop_Koordinator (CM_MO_StartStopp_Status_Cx1_System_aktiv_keine_Freigabe_durch_StartStop_Koordinator), 2=Cx2_System_aktiv_alle_Freigaben_liegen_vor (CM_MO_StartStopp_Status_Cx2_System_aktiv_alle_Freigaben_liegen_vor), 3=Cx3_System_aktiv_mindestens_eine_Freigabe_fehlt (CM_MO_StartStopp_Status_Cx3_System_aktiv_mindestens_eine_Freigabe_fehlt)}, range raw 0..3, transfer-property=PENDING  # Aktivitätsstatus Start/Stopp-Koordinator HYBRID: Wenn MO_Hybridfahrzeug = 1 gilt: Signal bezieht sich nur auf den Verbrennungsmotor, nicht auf den Hybridantrieb
          signal MO_StartStopp_Wiederstart_XIX_Motor_14_XIX_E3V_K2CANFD: start 14, 1 bit, little-endian, data-type-policy=OVERRIDE, i-signal-type=PRIMITIVE, init-value=0, base-type=BT_MO_StartStopp_Wiederstart, compu {0=Cx0_Wiederstart_inaktiv (CM_MO_StartStopp_Wiederstart_Cx0_Wiederstart_inaktiv), 1=Cx1_Wiederstart_aktiv (CM_MO_StartStopp_Wiederstart_Cx1_Wiederstart_aktiv)}, range raw 0..1, transfer-property=TRIGGERED-ON-CHANGE-WITHOUT-REPETITION  # Motorwiederstart durch Start/Stopp-Koordinator HYBRID: Wenn MO_Hybridfahrzeug =1 gilt: Warnung vor Spannungseinbruch beim Zustart des Verbrennungsmotors. -nicht relevant, da derzeit kein Start über 12V-Starter geplant- Dieses Signal wird nur vom Hybrid-Koordintor gesetzt, wenn durch den Wiederstart ein Spannungseinbruch zu erwarten ist
          signal MO_StartStopp_Motorstopp_XIX_Motor_14_XIX_E3V_K2CANFD: start 15, 1 bit, little-endian, data-type-policy=OVERRIDE, i-signal-type=PRIMITIVE, init-value=0, base-type=BT_MO_StartStopp_Motorstopp, compu {0=Cx0_Motor_Stop_inaktiv (CM_MO_StartStopp_Motorstopp_Cx0_Motor_Stop_inaktiv), 1=Cx1_Motor_Stop_aktiv (CM_MO_StartStopp_Motorstopp_Cx1_Motor_Stop_aktiv)}, range raw 0..1, transfer-property=TRIGGERED-ON-CHANGE-WITHOUT-REPETITION  # Motor-Stopp durch Start/Stopp-Koordinator HYBRID: Wenn MO_Hybridfahrzeug = 1 gilt: Verbrennungsmotor durch Hybrid-Koordinator im MSG ausgeschaltet. Die definierten Start/Stopp-Signale beziehen sich nur auf den Verbrennungsmotor!
          signal MO_Freig_Reku_XIX_Motor_14_XIX_E3V_K2CANFD: start 16, 2 bit, little-endian, data-type-policy=OVERRIDE, i-signal-type=PRIMITIVE, init-value=0, base-type=BT_MO_Freig_Reku, compu {0=Cx0_Rekuperations_Modus_aus (CM_MO_Freig_Reku_Cx0_Rekuperations_Modus_aus) (Rekuperations-Modus aus), 1=Cx1_Empfehlung_Spannungsanhebung (CM_MO_Freig_Reku_Cx1_Empfehlung_Spannungsanhebung) (Empfehlung Spannungsanhebung), 2=Cx2_Empfehlung_Spannungsabsenkung (CM_MO_Freig_Reku_Cx2_Empfehlung_Spannungsabsenkung) (Empfehlung Spannungsabsenkung), 3=Cx3_Rekuperationsmodus_aktiv_Spannungsvariation_nicht_notwendig (CM_MO_Freig_Reku_Cx3_Rekuperationsmodus_aktiv_Spannungsvariation_nicht_notwendig) (Rekuperationsmodus aktiv, Spannungsvariation nicht notwendig)}, range raw 0..3, transfer-property=PENDING  # Empfehlung des Motor-SG's zur Spannungsabsenkung/-anhebung für den Rekuperationsbetrieb
          signal MO_Kl_75_XIX_Motor_14_XIX_E3V_K2CANFD: start 18, 1 bit, little-endian, data-type-policy=OVERRIDE, i-signal-type=PRIMITIVE, init-value=0, base-type=BT_MO_Kl_75, compu {0=Cx0_Aus (CM_MO_Kl_75_Cx0_Aus), 1=Cx1_Ein (CM_MO_Kl_75_Cx1_Ein)}, range raw 0..1, transfer-property=TRIGGERED-ON-CHANGE-WITHOUT-REPETITION  # Klemme X
          signal MO_Kl_50_XIX_Motor_14_XIX_E3V_K2CANFD: start 19, 1 bit, little-endian, data-type-policy=OVERRIDE, i-signal-type=PRIMITIVE, init-value=0, base-type=BT_MO_Kl_50, compu {0=Cx0_aus (CM_MO_Kl_50_Cx0_aus), 1=Cx1_KL50_ein_Startausfuehrung_Fahrer (CM_MO_Kl_50_Cx1_KL50_ein_Startausfuehrung_Fahrer)}, range raw 0..1, transfer-property=TRIGGERED-ON-CHANGE-WITHOUT-REPETITION  # Klemme 50: Startausführung durch Ritzelstarter MLB: nicht von allen Motoren gesendet MQB/MLBevo: gesendet von allen Motoren
          signal MO_Gangposition_XIX_Motor_14_XIX_E3V_K2CANFD: start 20, 4 bit, little-endian, data-type-policy=OVERRIDE, i-signal-type=PRIMITIVE, init-value=14, base-type=BT_MO_Gangposition, invalid-value=Invalid_MO_Gangposition_XIX_Motor_14_XIX_E3V_K2CANFD:15, compu {0=Cx0_Gang_N (CM_MO_Gangposition_Cx0_Gang_N), 1=Cx1_Gang_1 (CM_MO_Gangposition_Cx1_Gang_1), 2=Cx2_Gang_2 (CM_MO_Gangposition_Cx2_Gang_2), 3=Cx3_Gang_3 (CM_MO_Gangposition_Cx3_Gang_3), 4=Cx4_Gang_4 (CM_MO_Gangposition_Cx4_Gang_4), 5=Cx5_Gang_5 (CM_MO_Gangposition_Cx5_Gang_5), 6=Cx6_Gang_6 (CM_MO_Gangposition_Cx6_Gang_6), 7=Cx7_Gang_7 (CM_MO_Gangposition_Cx7_Gang_7), 8=Cx8_Gang_8 (CM_MO_Gangposition_Cx8_Gang_8), 9=Cx9_Automat_P (CM_MO_Gangposition_Cx9_Automat_P), 10=Cxa_Automat_Vorwaerts_S (CM_MO_Gangposition_Cxa_Automat_Vorwaerts_S), 11=Cxb_Automat_Vorwaerts_D_E (CM_MO_Gangposition_Cxb_Automat_Vorwaerts_D_E) (Automat_Vorwaerts_D/E), 12=Cxc_Zwischenstellung (CM_MO_Gangposition_Cxc_Zwischenstellung), 13=Cxd_Gang_R (CM_MO_Gangposition_Cxd_Gang_R), 14=Cxe_Istgang_nicht_definiert (CM_MO_Gangposition_Cxe_Istgang_nicht_definiert), 15=Cxf_Fehler (CM_MO_Gangposition_Cxf_Fehler)}, range raw 0..15, transfer-property=TRIGGERED-ON-CHANGE-WITHOUT-REPETITION  # MLB: Stellung des Wählhebels in der Schaltgasse des Handschaltgetriebes. MLBevo: Ausweitung der Bedienung auch auf Automatikgetriebe; Routing des Signals GE_Fahrstufe: 1. Position_R (dez. 6) auf MO_Gangposition: Gang_R (dez. 13) wegen Entfall Signals BCM1_Rueckfahrlicht_Schalter; 2. Position_N (4) auf GangN (0) 3. Zwischenstellung (0) auf Zwischenstellung (12) 4. Init (1) auf Init (14) 5. Fehler (15) auf Fehler (15) oder Timeout der relevanten Getriebe-PDU 6. Position_S und Tipp_in_S auf Automat_Vorwärts_S (10) 7. Position_D, Effizienz und Tipp_in_D auf Automat_Vorwärts_D/E (11) 8. Position_P (5) auf Automat_P (9) Handschaltgetriebe wie MLB MQB: Abhängig vom Signal MO_Signalquelle_Gangposition: Stellung des Wählhebels in der Schaltgasse des Handschaltgetriebes aus Gangpositionssensor oder Modellwert aus Motordrehzahl und Fahrzeuggeschwindigkeit (ggf. unter Hinzuziehung des Neutralgangsensors und Rückfahrlichtschalters); bei betätigter Kupplung (MO_Kuppl_schalter=1) ist das der Modellwert nicht verwendbar. Der Modellwert ist für Plausibilisierungen nicht geeignet. Bei verbautem Automatikgetriebe wird der Initwert (14=Istgang nicht definiert) ausgegeben.
          signal MO_StartStopp_Fahrerwunsch_XIX_Motor_14_XIX_E3V_K2CANFD: start 24, 2 bit, little-endian, data-type-policy=OVERRIDE, i-signal-type=PRIMITIVE, init-value=0, base-type=BT_MO_StartStopp_Fahrerwunsch, compu {0=Cx0_Init (CM_MO_StartStopp_Fahrerwunsch_Cx0_Init), 1=Cx1_Stoppverbot_durch_Fahrer (CM_MO_StartStopp_Fahrerwunsch_Cx1_Stoppverbot_durch_Fahrer), 2=Cx2_Stoppfreigabe_durch_Fahrer (CM_MO_StartStopp_Fahrerwunsch_Cx2_Stoppfreigabe_durch_Fahrer), 3=Cx3_Stoppanforderung_durch_Fahrer (CM_MO_StartStopp_Fahrerwunsch_Cx3_Stoppanforderung_durch_Fahrer)}, range raw 0..3, transfer-property=PENDING  # Fahreraktivität Start/Stop
          signal MO_HYB_Fahrbereitschaft_XIX_Motor_14_XIX_E3V_K2CANFD: start 26, 1 bit, little-endian, data-type-policy=OVERRIDE, i-signal-type=PRIMITIVE, init-value=0, base-type=BT_MO_HYB_Fahrbereitschaft, compu {0=Cx0_keine_Fahrbereitschaft (CM_MO_HYB_Fahrbereitschaft_Cx0_keine_Fahrbereitschaft), 1=Cx1_Fahrbereitschaft (CM_MO_HYB_Fahrbereitschaft_Cx1_Fahrbereitschaft)}, range raw 0..1, transfer-property=PENDING, to SAM(timeout 1 s)  # Signal steuert u.a. in der Lenkhilfe zusammen mit weiteren Informationen den Modewechsel in den "Drivemode" Grüne Anzeige im Kombiinstrument zur Signalisierung der Bereitschaft des Hybridsystems.
          signal MO_Ext_E_Fahrt_aktiv_XIX_Motor_14_XIX_E3V_K2CANFD: start 27, 1 bit, little-endian, data-type-policy=OVERRIDE, i-signal-type=PRIMITIVE, init-value=0, base-type=BT_MO_Ext_E_Fahrt_aktiv, compu {0=Cx0_Rueckmeldung_E_Taster_aus (CM_MO_Ext_E_Fahrt_aktiv_Cx0_Rueckmeldung_E_Taster_aus), 1=Cx1_Rueckmeldung_E_Taster_ein (CM_MO_Ext_E_Fahrt_aktiv_Cx1_Rueckmeldung_E_Taster_ein)}, range raw 0..1, transfer-property=TRIGGERED-ON-CHANGE-WITHOUT-REPETITION  # Funktionsrückmeldung zum erw. E-Fahr-Betrieb über Lampe/LED im E-Mode-Taster
          signal MO_Fahrer_bremst_XIX_Motor_14_XIX_E3V_K2CANFD: start 28, 1 bit, little-endian, data-type-policy=OVERRIDE, i-signal-type=PRIMITIVE, init-value=0, base-type=BT_MO_Fahrer_bremst, compu {0=Cx0_kein_Bremsen (CM_MO_Fahrer_bremst_Cx0_kein_Bremsen), 1=Cx1_Bremse_betaetigt (CM_MO_Fahrer_bremst_Cx1_Bremse_betaetigt)}, range raw 0..1, transfer-property=TRIGGERED-ON-CHANGE-WITHOUT-REPETITION  # Redundante Bremsinformation vom Motor. MLB: AUDI D4: Zykluszeit: 10ms (siehe Zykluszeit schnell/Cycletime Fast) Im AUDI B8 wird in diesem Bit der Wert der ESP-CAN-Information "ESP_Fahrer_bremst" ausgegeben. Achtung: Reduktion der Zykluszeit Motor_03 auf 10ms geplant. Projektabhängig soll künftig mit 10ms gesendet werden. Empfänger die in weiteren Konzern-Projekten eingesetzt werden müssen dazu beide Zykluszeiten (10/20ms) unterstützen. Empfänger muss in diesem Fall für die Timeoutdiagnose und CAN-Messwerteblöcke mit 20ms auslegen.
          signal MO_QBit_Fahrer_bremst_XIX_Motor_14_XIX_E3V_K2CANFD: start 29, 1 bit, little-endian, data-type-policy=OVERRIDE, i-signal-type=PRIMITIVE, init-value=1, base-type=BT_MO_QBit_Fahrer_bremst, compu {0=Cx0_gueltiger_Wert (CM_MO_QBit_Fahrer_bremst_Cx0_gueltiger_Wert), 1=Cx1_Ersatz_Init_oder_Fehlerwert (CM_MO_QBit_Fahrer_bremst_Cx1_Ersatz_Init_oder_Fehlerwert)}, range raw 0..1, transfer-property=TRIGGERED-ON-CHANGE-WITHOUT-REPETITION  # MLB: AUDI D4: Zykluszeit: 10ms (siehe Zykluszeit schnell/Cycletime Fast) Achtung: Reduktion der Zykluszeit Motor_03 auf 10ms geplant. Projektabhängig soll künftig mit 10ms gesendet werden. Empfänger die in weiteren Konzern-Projekten eingesetzt werden müssen dazu beide Zykluszeiten (10/20ms) unterstützen. Empfänger muss in diesem Fall für die Timeoutdiagnose und CAN-Messwerteblöcke mit 20ms auslegen.
          signal MO_BLS_XIX_Motor_14_XIX_E3V_K2CANFD: start 30, 1 bit, little-endian, data-type-policy=OVERRIDE, i-signal-type=PRIMITIVE, init-value=0, base-type=BT_MO_BLS, compu {0=Cx0_kein_Bremsen (CM_MO_BLS_Cx0_kein_Bremsen), 1=Cx1_Bremse_betaetigt (CM_MO_BLS_Cx1_Bremse_betaetigt)}, range raw 0..1, transfer-property=TRIGGERED-ON-CHANGE-WITHOUT-REPETITION  # Ungefiltertes Rohsignal des Bremslichtschalters, nur wenn HW-Eingang bestückt und ausgewertet wird. Bei Motoren ohne genutzten HW-Eingang wird kein Ersatzwert (bspw. SW-Signal über CAN) ausgegeben! Bei AUDI muss das Signal wg. Bremslichtfunktion immer bedient werden. MLB: AUDI D4: Zykluszeit: 10ms (siehe Zykluszeit schnell/Cycletime Fast) Achtung: Reduktion der Zykluszeit Motor_03 auf 10ms geplant. Projektabhängig soll künftig mit 10ms gesendet werden. Empfänger die in weiteren Konzern-Projekten eingesetzt werden müssen dazu beide Zykluszeiten (10/20ms) unterstützen. Empfänger muss in diesem Fall für die Timeoutdiagnose und CAN-Messwerteblöcke mit 20ms auslegen.
          signal MO_Konsistenz_Bremsped_XIX_Motor_14_XIX_E3V_K2CANFD: start 31, 1 bit, little-endian, data-type-policy=OVERRIDE, i-signal-type=PRIMITIVE, init-value=0, base-type=BT_MO_Konsistenz_Bremsped, compu {0=Cx0_Bremspedalinformation_plausibel (CM_MO_Konsistenz_Bremsped_Cx0_Bremspedalinformation_plausibel), 1=Cx1_Bremspedalinformation_unplausibel (CM_MO_Konsistenz_Bremsped_Cx1_Bremspedalinformation_unplausibel)}, range raw 0..1, transfer-property=TRIGGERED-ON-CHANGE-WITHOUT-REPETITION  # MLB: AUDI D4: Zykluszeit: 10ms (siehe Zykluszeit schnell/Cycletime Fast) Siehe "Funktionsspezifikation Bremslichtinfo B8" Achtung: Reduktion der Zykluszeit Motor_03 auf 10ms geplant. Projektabhängig soll künftig mit 10ms gesendet werden. Empfänger die in weiteren Konzern-Projekten eingesetzt werden müssen dazu beide Zykluszeiten (10/20ms) unterstützen. Empfänger muss in diesem Fall für die Timeoutdiagnose und CAN-Messwerteblöcke mit 20ms auslegen.
          signal MO_Timeout_ESP_XIX_Motor_14_XIX_E3V_K2CANFD: start 32, 1 bit, little-endian, data-type-policy=OVERRIDE, i-signal-type=PRIMITIVE, init-value=0, base-type=BT_MO_Timeout_ESP, compu {0=Cx0_Empfang_iO (CM_MO_Timeout_ESP_Cx0_Empfang_iO), 1=Cx1_Timeout (CM_MO_Timeout_ESP_Cx1_Timeout)}, range raw 0..1, transfer-property=TRIGGERED-ON-CHANGE-WITHOUT-REPETITION  # 500 ms Timeout auf Bremsen-Botschaft ist >= 1 mal aufgelaufen, Löschen des Bits nach Neustart (KL15). MLB: AUDI D4: Zykluszeit: 10ms (siehe Zykluszeit schnell/Cycletime Fast) Achtung: Reduktion der Zykluszeit Motor_03 auf 10ms geplant. Projektabhängig soll künftig mit 10ms gesendet werden. Empfänger die in weiteren Konzern-Projekten eingesetzt werden müssen dazu beide Zykluszeiten (10/20ms) unterstützen. Empfänger muss in diesem Fall für die Timeoutdiagnose und CAN-Messwerteblöcke mit 20ms auslegen.
          signal MO_Klima_Eingr_XIX_Motor_14_XIX_E3V_K2CANFD: start 33, 2 bit, little-endian, data-type-policy=OVERRIDE, i-signal-type=PRIMITIVE, init-value=0, base-type=BT_MO_Klima_Eingr, compu {0=Cx0_kein_Eingriff (CM_MO_Klima_Eingr_Cx0_kein_Eingriff) (kein Eingriff), 1=Cx1_Klimakompressor_ausschalten (CM_MO_Klima_Eingr_Cx1_Klimakompressor_ausschalten) (Klimakompressor ausschalten), 2=Cx2_Klimakompressor_Leistungsreduzierung (CM_MO_Klima_Eingr_Cx2_Klimakompressor_Leistungsreduzierung) (Klimakompressor Leistungsreduzierung), 3=Cx3_Klimakompressor_aufgrund_der_Heissleuchtenvorwarnung_ausschalten (CM_MO_Klima_Eingr_Cx3_Klimakompressor_aufgrund_der_Heissleuchtenvorwarnung_ausschalten) (Klimakompressor aufgrund der Heissleuchtenvorwarnung ausschalten)}, range raw 0..3, transfer-property=TRIGGERED-ON-CHANGE-WITHOUT-REPETITION  # Eingriffe des Motor bei der Klima
          signal MO_Aussp_Anlass_XIX_Motor_14_XIX_E3V_K2CANFD: start 35, 1 bit, little-endian, data-type-policy=OVERRIDE, i-signal-type=PRIMITIVE, init-value=0, base-type=BT_MO_Aussp_Anlass, compu {0=Cx0_Anlasser_darf_angesteuert_werden (CM_MO_Aussp_Anlass_Cx0_Anlasser_darf_angesteuert_werden), 1=Cx1_Anlasser_ausspuren_Ansteuerung_nicht_moeglich (CM_MO_Aussp_Anlass_Cx1_Anlasser_ausspuren_Ansteuerung_nicht_moeglich) (Anlasser_ausspuren__Ansteuerung_nicht_moeglich)}, range raw 0..1, transfer-property=TRIGGERED-ON-CHANGE-WITHOUT-REPETITION  # Das Signal zeigt an, ob die Wiederholstartsperre aktiv ist. D. h. eine Ansteuerung des Anlassers wird auch bei erfüllten Startvoraussetzungen (HS: Interlock betätigt bzw. AT: P/N eingelegt und Bremse betätigt) nicht erfolgen.
          signal MO_Freig_Anlass_XIX_Motor_14_XIX_E3V_K2CANFD: start 36, 1 bit, little-endian, data-type-policy=OVERRIDE, i-signal-type=PRIMITIVE, init-value=0, base-type=BT_MO_Freig_Anlass, compu {0=Cx0_Start_nicht_zulaessig (CM_MO_Freig_Anlass_Cx0_Start_nicht_zulaessig), 1=Cx1_Startfreigabe (CM_MO_Freig_Anlass_Cx1_Startfreigabe)}, range raw 0..1, transfer-property=TRIGGERED-ON-CHANGE-WITHOUT-REPETITION  # Bit wird gesetzt, wenn der Motor beim Automatikstart gestartet werden darf (Motorstillstand, Emissionsmaßnahmen sind erfüllt).
          signal MO_Kuppl_schalter_XIX_Motor_14_XIX_E3V_K2CANFD: start 37, 1 bit, little-endian, data-type-policy=OVERRIDE, i-signal-type=PRIMITIVE, init-value=0, base-type=BT_MO_Kuppl_schalter, compu {0=Cx0_Schalter_sagt_ausgekuppelt (CM_MO_Kuppl_schalter_Cx0_Schalter_sagt_ausgekuppelt), 1=Cx1_Schalter_sagt_eingekuppelt (CM_MO_Kuppl_schalter_Cx1_Schalter_sagt_eingekuppelt)}, range raw 0..1, transfer-property=TRIGGERED-ON-CHANGE-WITHOUT-REPETITION  # MLB: Das Motorsteuergerät gibt die Information aus, ab wann der Kupplungsschalter durch das Motorsteuergerät als getreten gesehen wird 0x0: Schalter sagt betätigt (Ausgekuppelt) 0x1: Schalter sagt nicht betätigt (Eingekuppelt) MQB: Nur Handschalter; aktiv, wenn Schalter verbaut; sonst konstant auf "0" gesetzt; Bit wird gesetzt, wenn Kupplungspedal nicht betätigt wird (Kupplungsschalter hoch), Triebstrang kann noch eingekuppelt sein.
          signal MO_Interlock_XIX_Motor_14_XIX_E3V_K2CANFD: start 38, 1 bit, little-endian, data-type-policy=OVERRIDE, i-signal-type=PRIMITIVE, init-value=0, base-type=BT_MO_Interlock, compu {0=Cx0_Interlockschalter_nicht_betaetigt (CM_MO_Interlock_Cx0_Interlockschalter_nicht_betaetigt), 1=Cx1_Interlockschalter_betaetigt (CM_MO_Interlock_Cx1_Interlockschalter_betaetigt)}, range raw 0..1, transfer-property=TRIGGERED-ON-CHANGE-WITHOUT-REPETITION  # Das Motorsteuergerät gibt die Information aus, ab wann der Kupplungsschalter durch das Motorsteuergerät als getreten gesehen wird. Bei Systemen für Start Stopp muss das Interlocksignal für einen Start durch das MSG generiert werden, sobald der Schalthebel in Neutralposition (kein Kraftschluß) und ein Wiederstart vom StartStopp-Koordinator angefordert wird.
          signal MO_Motor_laeuft_XIX_Motor_14_XIX_E3V_K2CANFD: start 39, 1 bit, little-endian, data-type-policy=OVERRIDE, i-signal-type=PRIMITIVE, init-value=0, base-type=BT_MO_Motor_laeuft, compu {0=Cx0_Motor_laeuft_nicht (CM_MO_Motor_laeuft_Cx0_Motor_laeuft_nicht), 1=Cx1_Motor_laeuft_autark_und_stabil_und_darf_mechanisch_belastet_werden (CM_MO_Motor_laeuft_Cx1_Motor_laeuft_autark_und_stabil_und_darf_mechanisch_belastet_werden)}, range raw 0..1, transfer-property=TRIGGERED-ON-CHANGE-WITHOUT-REPETITION  # Das Motorsteuergerät gibt die Information aus, ab wann der Motor verbrennungsbedingt autark läuft und durch zuschaltbare Nebenaggregate mechanisch belastbar ist (z.B. durch Generator, Klimakompressor, etc.). Die "Motor läuft" Information wird ausgegeben, wenn für eine (projektspezifisch) applizierbare Zeit (~500 - 600ms) die (projektspezifische) Motor-Startende-Drehzahl überschritten wird. Diese Drehzahlschwelle ist von der Kühlwassertemperatur und dem Umgebungsdruck (Diesel Motor) abhängig. Das Bit wird auch gesetzt, nach MSG-Reset und wenn der Motor angeschleppt wird (wenn während der Fahrt Kl. 15 aus --> ein erfolgt) HYBRID: Wenn MO_Hybridfahrzeug = 1 gilt: Hybridantrieb läuft und ist belastbar, es kann ein Moment abgegeben werden (erzeugt durch ELM oder / und VKM). Rücknahme des Signals im Fehlerfall, wenn das Hybridsystem die Versorgung des Bordnetzes deutlich begrenzen bzw. abschalten muss. Achtung: Das Signal kann nicht mehr dazu dienen, ob Komponenten am Riementrieb des Verbrennungsmotors den Verbrennungsmotor belasten können.
          signal MO_Kickdown_XIX_Motor_14_XIX_E3V_K2CANFD: start 40, 1 bit, little-endian, data-type-policy=OVERRIDE, i-signal-type=PRIMITIVE, init-value=0, base-type=BT_MO_Kickdown, compu {0=Cx0_kein_Kickdown (CM_MO_Kickdown_Cx0_kein_Kickdown), 1=Cx1_Kickdown (CM_MO_Kickdown_Cx1_Kickdown)}, range raw 0..1, transfer-property=TRIGGERED-ON-CHANGE-WITHOUT-REPETITION  # Es gilt: Signalspec MO_Kickdown v1.0
          signal MO_QBit_KL_75_XIX_Motor_14_XIX_E3V_K2CANFD: start 41, 1 bit, little-endian, data-type-policy=OVERRIDE, i-signal-type=PRIMITIVE, init-value=1, base-type=BT_MO_QBit_KL_75, compu {0=Cx0_gueltiger_Wert (CM_MO_QBit_KL_75_Cx0_gueltiger_Wert), 1=Cx1_Ersatz_Init_oder_Fehlerwert (CM_MO_QBit_KL_75_Cx1_Ersatz_Init_oder_Fehlerwert)}, range raw 0..1, transfer-property=TRIGGERED-ON-CHANGE-WITHOUT-REPETITION  # Q - Bit für das KL 75 Signal zur Vermeidung der fehlerhaften Erkennung von Motorstarts. Wird auf 1 gesetzt, solange das Motorsteuergerät KL15 = AUS erkannt hat.
          signal MO_EKlKomLeiRed_XIX_Motor_14_XIX_E3V_K2CANFD: start 42, 2 bit, little-endian, data-type-policy=OVERRIDE, i-signal-type=PRIMITIVE, init-value=0, base-type=BT_MO_EKlKomLeiRed, compu {0=Cx0_keine_Leistungsbegr (CM_MO_EKlKomLeiRed_Cx0_keine_Leistungsbegr), 1=Cx1_Leistungsbegr_75 (CM_MO_EKlKomLeiRed_Cx1_Leistungsbegr_75), 2=Cx2_Leistungsbegr_50 (CM_MO_EKlKomLeiRed_Cx2_Leistungsbegr_50), 3=Cx3_Leistungsbegr_25 (CM_MO_EKlKomLeiRed_Cx3_Leistungsbegr_25)}, range raw 0..3, transfer-property=PENDING  # Anforderung an die Klimasteuerung, die Leistungsaufnahme des E-Kompressors bei schlechtem SOC und in bestimmten Fahrsituationen zu begrenzen. (Das bereits bestehende Signal "Klimakompressor aus" als stets umzusetzende Anforderung bleibt unverändert bestehen.) 0 keine Leistungsbegr. gewünscht 1 Leistungsbegr. auf 75% der max. Leistung 2 Leistungsbegr. auf 50% der max. Leistung 3 Leistungsbegr. auf 25% der max. Leistung
          signal MO_Handshake_STH_XIX_Motor_14_XIX_E3V_K2CANFD: start 44, 1 bit, little-endian, data-type-policy=OVERRIDE, i-signal-type=PRIMITIVE, init-value=0, base-type=BT_MO_Handshake_STH, compu {0=Cx0_keine_EKP_Ansteuerung_durch_STH_Anforderung (CM_MO_Handshake_STH_Cx0_keine_EKP_Ansteuerung_durch_STH_Anforderung) (keine EKP-Ansteuerung durch STH-Anforderung), 1=Cx1_EKP_Ansteuerung_durch_STH_Anforderung (CM_MO_Handshake_STH_Cx1_EKP_Ansteuerung_durch_STH_Anforderung) (EKP-Ansteuerung durch STH-Anforderung)}, range raw 0..1, transfer-property=PENDING  # Es gilt: Signalspec MO_Handshake v1.0 Handshake zwischen MSG und STH. Wenn das MSG die EKP aufgrund einer STH-Anforderung ansteuert und kein Fehlereintrag bzgl. EKP/KPE/NDR vorliegt, wird das Bit gesetzt.
          signal MO_BKV_Unterdruckwarnung_XIX_Motor_14_XIX_E3V_K2CANFD: start 45, 1 bit, little-endian, data-type-policy=OVERRIDE, i-signal-type=PRIMITIVE, init-value=0, base-type=BT_MO_BKV_Unterdruckwarnung, compu {0=Cx0_Unterdruckhaushalt_iO (CM_MO_BKV_Unterdruckwarnung_Cx0_Unterdruckhaushalt_iO), 1=Cx1_Unterdruckhaushalt_niO (CM_MO_BKV_Unterdruckwarnung_Cx1_Unterdruckhaushalt_niO)}, range raw 0..1, transfer-property=PENDING  # Über die Unterdruckwarnung signalisiert das MSG dem ESP, dass kein ausreichender Unterdruck für den BKV zur Verfügung gestellt werden kann.
          signal MO_Freigabe_Segeln_XIX_Motor_14_XIX_E3V_K2CANFD: start 46, 1 bit, little-endian, data-type-policy=OVERRIDE, i-signal-type=PRIMITIVE, init-value=0, base-type=BT_MO_Freigabe_Segeln, compu {0=Cx0_Segelbetrieb_nicht_freigegeben (CM_MO_Freigabe_Segeln_Cx0_Segelbetrieb_nicht_freigegeben), 1=Cx1_Segelbetrieb_freigegeben (CM_MO_Freigabe_Segeln_Cx1_Segelbetrieb_freigegeben)}, range raw 0..1, transfer-property=PENDING  # Freigabebit des Segelbetriebs im Getriebe. Bedingt durch bestimmte Diagnosen und Adaptionen des MSGs, die nur im Schub möglich sind, darf nicht jede Schubphase für einen Segelbetrieb genutzt werden. Eine Freigabe bleibt auch außerhalb einer Schubphase bestehen. D.h. das Signal kennzeichnet nicht die Schubphase sondern sagt nur aus, dass aus Motorsicht nichts gegen einen Segelbetrieb in einer der nächsten Schubphasen spricht.
          signal MO_PTC_Status_XIX_Motor_14_XIX_E3V_K2CANFD: start 47, 3 bit, little-endian, data-type-policy=OVERRIDE, i-signal-type=PRIMITIVE, init-value=0, base-type=BT_MO_PTC_Status, compu {0=Cx0_nicht_unterstuetzt (CM_MO_PTC_Status_Cx0_nicht_unterstuetzt), 1=Cx1_Stufe_0 (CM_MO_PTC_Status_Cx1_Stufe_0), 2=Cx2_Stufe_1 (CM_MO_PTC_Status_Cx2_Stufe_1), 3=Cx3_Stufe_2 (CM_MO_PTC_Status_Cx3_Stufe_2), 4=Cx4_Stufe_3 (CM_MO_PTC_Status_Cx4_Stufe_3), 7=Cx7_PTC_am_BCM (CM_MO_PTC_Status_Cx7_PTC_am_BCM)}, range raw 0..7, transfer-property=PENDING  # Status-Rückmeldung vom MSG zum aktuellen PTC-Status (stufiges PTC, Relais am MSG). Bei Ansteuerung eines stufigen PTC durch ein anderes SG beschreibt das Signal die vom MSG freigegebene PTC-Stufe.
          signal MO_QBit_Gangposition_XIX_Motor_14_XIX_E3V_K2CANFD: start 50, 1 bit, little-endian, data-type-policy=OVERRIDE, i-signal-type=PRIMITIVE, init-value=1, base-type=BT_MO_QBit_Gangposition, compu {0=Cx0_gueltiger_Wert (CM_MO_QBit_Gangposition_Cx0_gueltiger_Wert), 1=Cx1_Ersatz_Init_oder_Fehlerwert (CM_MO_QBit_Gangposition_Cx1_Ersatz_Init_oder_Fehlerwert)}, range raw 0..1, transfer-property=TRIGGERED-ON-CHANGE-WITHOUT-REPETITION  # Qualitätsbit zum Signal MO_Gangposition
          signal MO_Signalquelle_Gangposition_XIX_Motor_14_XIX_E3V_K2CANFD: start 51, 1 bit, little-endian, data-type-policy=OVERRIDE, i-signal-type=PRIMITIVE, init-value=0, base-type=BT_MO_Signalquelle_Gangposition, compu {0=Cx0_Sensorsignal (CM_MO_Signalquelle_Gangposition_Cx0_Sensorsignal), 1=Cx1_Modellsignal (CM_MO_Signalquelle_Gangposition_Cx1_Modellsignal)}, range raw 0..1, transfer-property=PENDING  # Signalquelle des Signals MO_Gangposition 0: Signalquelle Gangpositionssensor 1: Signalquelle Modellwert (v/n)
          signal MO_Remotestart_Betrieb_XIX_Motor_14_XIX_E3V_K2CANFD: start 52, 1 bit, little-endian, data-type-policy=OVERRIDE, i-signal-type=PRIMITIVE, init-value=0, base-type=BT_MO_Remotestart_Betrieb, compu {0=Cx0_MSG_nicht_bereit_fuer_RS_Betrieb (CM_MO_Remotestart_Betrieb_Cx0_MSG_nicht_bereit_fuer_RS_Betrieb), 1=Cx1_MSG_bereit_fuer_oder_im_RS_Betrieb (CM_MO_Remotestart_Betrieb_Cx1_MSG_bereit_fuer_oder_im_RS_Betrieb)}, range raw 0..1, transfer-property=TRIGGERED-ON-CHANGE-WITHOUT-REPETITION  # Das MSG ist für den Remotestart-Betrieb bereit. Nach Empfang der Motorstartanforderung für RSt-Betrieb durch BCM wird der Fahrzeugmotor gestartet und solange der Motor läuft, bleibt dieses Bit aktiv. Dieses Signal ist nur zur Verwendung durch das BCM zur RemoteStart-Freigabe.
          signal MO_Remotestart_moeglich_XIX_Motor_14_XIX_E3V_K2CANFD: start 53, 1 bit, little-endian, data-type-policy=OVERRIDE, i-signal-type=PRIMITIVE, init-value=0, base-type=BT_MO_Remotestart_moeglich, compu {0=Cx0_Remotestart_nicht_moeglich (CM_MO_Remotestart_moeglich_Cx0_Remotestart_nicht_moeglich), 1=Cx1_Remotestart_moeglich (CM_MO_Remotestart_moeglich_Cx1_Remotestart_moeglich)}, range raw 0..1, transfer-property=PENDING  # Wenn Bit gesetzt, würde das MSG bei entsprechender Anforderung durch das BCM den Remotestartbetrieb einleiten, d.h. das MSG ist remotestartfähig und es liegen aktuell keine relevanten Fehler oder andere Abbruchgründe vor.
          signal MO_FMAus_aktiv_XIX_Motor_14_XIX_E3V_K2CANFD: start 55, 1 bit, little-endian, data-type-policy=OVERRIDE, i-signal-type=PRIMITIVE, init-value=0, base-type=BT_MO_FMAus_aktiv, compu {0=Cx0_inaktiv (CM_MO_FMAus_aktiv_Cx0_inaktiv), 1=Cx1_Segeln_mit_Motor_aus_aktiv (CM_MO_FMAus_aktiv_Cx1_Segeln_mit_Motor_aus_aktiv)}, range raw 0..1, transfer-property=TRIGGERED-ON-CHANGE-WITHOUT-REPETITION  # Das Signal gibt Rückmeldung ob Freilauf Motor aus aktiv ist. Beleibt auch 0km/h (unterhalb der StartStopp Schwelle) weiterhin aktiv.
          signal MO_FMAus_Startvariante_XIX_Motor_14_XIX_E3V_K2CANFD: start 56, 2 bit, little-endian, data-type-policy=OVERRIDE, i-signal-type=PRIMITIVE, init-value=0, base-type=BT_MO_FMAus_Startvariante, compu {0=Cx0_kein_Motorstart (CM_MO_FMAus_Startvariante_Cx0_kein_Motorstart), 1=Cx1_Motorstart_elektrischer_Starter (CM_MO_FMAus_Startvariante_Cx1_Motorstart_elektrischer_Starter), 2=Cx2_GetriebeAnschleppstart (CM_MO_FMAus_Startvariante_Cx2_GetriebeAnschleppstart), 3=Cx3_GetriebeNotAnschleppstart (CM_MO_FMAus_Startvariante_Cx3_GetriebeNotAnschleppstart)}, range raw 0..3, transfer-property=TRIGGERED-ON-CHANGE-WITHOUT-REPETITION  # Startvariante beim Motorstart aus der Freilauf-Motor-AUS Phase
          signal MO_BMS_NV_Anf_stuetzen_XIX_Motor_14_XIX_E3V_K2CANFD: start 58, 1 bit, little-endian, data-type-policy=OVERRIDE, i-signal-type=PRIMITIVE, init-value=0, base-type=BT_MO_BMS_NV_Anf_stuetzen, compu {0=Cx0_nicht_notwendig (CM_MO_BMS_NV_Anf_stuetzen_Cx0_nicht_notwendig), 1=Cx1_notwendig (CM_MO_BMS_NV_Anf_stuetzen_Cx1_notwendig)}, range raw 0..1, transfer-property=TRIGGERED-ON-CHANGE-WITHOUT-REPETITION  # Garantierte Unterstützung des Zusatzspeichers ist erforderlich. Zusatzspeicher muss an das Versorgungsnezt angebunden werden.
          signal MO_Zylinderabschaltung_XIX_Motor_14_XIX_E3V_K2CANFD: start 59, 2 bit, little-endian, data-type-policy=OVERRIDE, i-signal-type=PRIMITIVE, init-value=0, base-type=BT_MO_Zylinderabschaltung, compu {0=Cx0_Vollmotorbetrieb_VMB (CM_MO_Zylinderabschaltung_Cx0_Vollmotorbetrieb_VMB), 1=Cx1_Uebergang_HMB_in_VMB (CM_MO_Zylinderabschaltung_Cx1_Uebergang_HMB_in_VMB), 2=Cx2_Uebergang_VMB_in_HMB (CM_MO_Zylinderabschaltung_Cx2_Uebergang_VMB_in_HMB), 3=Cx3_Halbmotorbetrieb_HMB (CM_MO_Zylinderabschaltung_Cx3_Halbmotorbetrieb_HMB)}, range raw 0..3, transfer-property=TRIGGERED-ON-CHANGE-WITHOUT-REPETITION  # Status Zylinderabschaltung Motor
          signal MO_HYB_VM_aktiv_XIX_Motor_14_XIX_E3V_K2CANFD: start 61, 1 bit, little-endian, data-type-policy=OVERRIDE, i-signal-type=PRIMITIVE, init-value=0, base-type=BT_MO_HYB_VM_aktiv, compu {0=Cx0_VM_nicht_aktiv (CM_MO_HYB_VM_aktiv_Cx0_VM_nicht_aktiv), 1=Cx1_VM_aktiv (CM_MO_HYB_VM_aktiv_Cx1_VM_aktiv)}, range raw 0..1, transfer-property=TRIGGERED-ON-CHANGE-WITHOUT-REPETITION  # 0 = VMotor wird nicht aktiv gehalten (nVM < n_min und keine LL-Regelung aktiv) 1 = VMotor aktiv (ab der ersten Einspritzung; gilt auch für Schubbetrieb, wenn VMotor spätestens durch LLRegelung befeuert würde) Verwendet zur Bestimmung des Ist-Zustandes
          signal MO_StartVorauss_erfuellt_XIX_Motor_14_XIX_E3V_K2CANFD: start 62, 2 bit, little-endian, data-type-policy=OVERRIDE, i-signal-type=PRIMITIVE, init-value=1, base-type=BT_MO_StartVorauss_erfuellt, compu {0=Cx0_Signal_nicht_bedient (CM_MO_StartVorauss_erfuellt_Cx0_Signal_nicht_bedient), 1=Cx1_StartVorauss_nicht_ueberpruefbar (CM_MO_StartVorauss_erfuellt_Cx1_StartVorauss_nicht_ueberpruefbar), 2=Cx2_StartVorauss_nicht_erfuellt (CM_MO_StartVorauss_erfuellt_Cx2_StartVorauss_nicht_erfuellt), 3=Cx3_StartVorauss_erfuellt (CM_MO_StartVorauss_erfuellt_Cx3_StartVorauss_erfuellt)}, range raw 0..3, transfer-property=TRIGGERED-ON-CHANGE-WITHOUT-REPETITION  # Dient der Fallunterscheidung bei ZAT-Betätigung im Zustand "KL15 ein" (bei nicht gesetztem Signal folgt KL15 aus, bei gesetztem Signal folgt setzen KL50-Anf.) 0: Signal nicht bedient 1: Voraussetzungen zur Antriebsstrangaktivierung / Startvoraussetzungen nicht überprüfbar, Initwert Bildung: -MQB Handschalter: solange 'Kl15 aus' und für die ersten 50ms bei 'Kl15 ein' -MQB Automaten: solange 'Kl15 aus' und für die ersten 50-400ms bei 'Kl15 ein' -MLB Handschalter: solange 'Kl87 aus' und für die ersten 50ms bei 'Kl87 ein', wobei bei 'Kl15 ein' immer auch 'Kl87 ein' -MLB Automaten: solange 'Kl87 aus' oder Getriebe-SG nicht wach sowie für die ersten 50-400ms bei gleichzeitigem 'Kl87 ein' und 'Getriebe-SG wach' 2: Voraussetzungen zur Antriebsstrangaktivierung / Startvoraussetzungen nicht erfüllt 3: Voraussetzungen zur Antriebsstrangaktivierung / Startvoraussetzungen erfüllt
      frame Motor_51_Auth_XIX_E3V_K2CANFD: id 0x10B, to SAM, frame-length=48, can-addressing-mode=STANDARD, can-frame-rx-behavior=CAN-FD, can-frame-tx-behavior=CAN-FD
        pdu Motor_51_Auth_XIX_E3V_K2CANFD: length=44, transmission-mode-true-timing=cyclic-timing={time-offset=0.0, time-period=0.02}, unused-bit-pattern=0
          signal Motor_51_CRC_XIX_Motor_51_Auth_XIX_E3V_K2CANFD: start 0, 8 bit, little-endian, data-type-policy=OVERRIDE, i-signal-type=PRIMITIVE, base-type=BT_Motor_51_CRC, compu {phys=raw for raw 0..255}, range phys 0..255, raw 0..255, transfer-property=PENDING  # Für MLB: Berechnung siehe Lastenheft "Kommunikationsabsicherung für FlexRay und CAN" Ab MQB und MLBevo: Berechnung siehe Lastenheft "End-to-End Kommunikationsabsicherung" Endwerte siehe Begleitdokument "S-PDU Kennungsfolgen"
          signal Motor_51_BZ_XIX_Motor_51_Auth_XIX_E3V_K2CANFD: start 8, 4 bit, little-endian, data-type-policy=OVERRIDE, i-signal-type=PRIMITIVE, base-type=BT_Motor_51_BZ, compu {phys=raw for raw 0..15}, range phys 0..15, raw 0..15, transfer-property=PENDING  # 4bit Botschaftszähler, wird mit jeder Sendebotschaft inkrementiert
          signal MO_Fahrpedalrohwert_01_XIX_Motor_51_Auth_XIX_E3V_K2CANFD: start 12, 8 bit, little-endian, data-type-policy=OVERRIDE, i-signal-type=PRIMITIVE, init-value=0, base-type=BT_MO_Fahrpedalrohwert_01, invalid-value=Invalid_MO_Fahrpedalrohwert_01_XIX_Motor_51_Auth_XIX_E3V_K2CANFD:255, compu {phys=raw*0.4 for raw 0..254, 255=Cxff_Fehler (CM_MO_Fahrpedalrohwert_01_Cxff_Fehler); unit Unit_PerCent}, range phys 0..101.6 Unit_PerCent, raw 0..255, unit=Unit_PerCent, transfer-property=PENDING, to SAM(timeout 0.5 s)  # AUDI D4: Zykluszeit: 10ms (siehe Zykluszeit schnell/Cycletime Fast) Stellung des Fahrpedales (Rohwert, ohne Überlagerung durch GRA-Eingriffe etc.) Die Funktionen zur Berechung des Fahrpedalrohwerts laufen im 10ms Raster. Der Fahrpedalwert berechnet sich jedoch immer aus dem, bezogen auf einen Ausgabezyklus, letzten für die Berechnung des Gradienten genutzten Signalwerts. Achtung: Reduktion der Zykluszeit Motor_03 auf 10ms geplant. Projektabhängig soll künftig mit 10ms gesendet werden. Empfänger die in weiteren Konzern-Projekten eingesetzt werden müssen dazu beide Zykluszeiten (10/20ms) unterstützen. Empfänger muss in diesem Fall für die Timeoutdiagnose und CAN-Messwerteblöcke mit 20ms auslegen.
          signal MO_QBit_Fahrpedalwerte_01_XIX_Motor_51_Auth_XIX_E3V_K2CANFD: start 20, 1 bit, little-endian, data-type-policy=OVERRIDE, i-signal-type=PRIMITIVE, init-value=1, base-type=BT_MO_QBit_Fahrpedalwerte_01, compu {0=Cx0_gueltiger_Wert (CM_MO_QBit_Fahrpedalwerte_01_Cx0_gueltiger_Wert), 1=Cx1_Ersatz_Init_oder_Fehlerwert (CM_MO_QBit_Fahrpedalwerte_01_Cx1_Ersatz_Init_oder_Fehlerwert)}, range raw 0..1, transfer-property=PENDING  # AUDI D4: Zykluszeit: 10ms (siehe Zykluszeit schnell/Cycletime Fast) QBit für beide Fahrpedalwerte des Motors (Fahrpedalrohsignal für ESP, EPB, ACC; Fahrpedalwert für Getriebe) Achtung: Reduktion der Zykluszeit Motor_03 auf 10ms geplant. Projektabhängig soll künftig mit 10ms gesendet werden. Empfänger die in weiteren Konzern-Projekten eingesetzt werden müssen dazu beide Zykluszeiten (10/20ms) unterstützen. Empfänger muss in diesem Fall für die Timeoutdiagnose und CAN-Messwerteblöcke mit 20ms auslegen.
          signal MO_Fahrpedalgradient_XIX_Motor_51_Auth_XIX_E3V_K2CANFD: start 21, 8 bit, little-endian, data-type-policy=OVERRIDE, i-signal-type=PRIMITIVE, init-value=0, base-type=BT_MO_Fahrpedalgradient, invalid-value=Invalid_MO_Fahrpedalgradient_XIX_Motor_51_Auth_XIX_E3V_K2CANFD:255, compu {phys=raw*25 for raw 0..254, 255=Cxff_Fehler (CM_MO_Fahrpedalgradient_Cxff_Fehler); unit Unit_PerCentPerSecon}, range phys 0..6350 Unit_PerCentPerSecon, raw 0..255, unit=Unit_PerCentPerSecon, transfer-property=PENDING  # Das Motorsteuergerät besitzt 2 analoge Fahrpedalsignale. Das Signal des ersten Kanals wird alle 4ms abgetastet. Um Bitschwankungen des A/D-Wandler herauszufiltern wird das Signal entjittert. Anschließend wird der Gradient berechnet. Entsprechend der Zykluszeit wird für jeden Zyklus der betragsmäßig größte Gradient ausgegeben. Bei einem Fehler des ersten Fahrpedalsignals wird FFh übermittelt." Muß zusammen mit Vorzeichen des "Fahrpedalgradient" ausgewertet werden.
          signal MO_Sig_Fahrpedalgradient_XIX_Motor_51_Auth_XIX_E3V_K2CANFD: start 29, 1 bit, little-endian, data-type-policy=OVERRIDE, i-signal-type=PRIMITIVE, init-value=0, base-type=BT_MO_Sig_Fahrpedalgradient, compu {0=Cx0_Fahrpedalgradient_positiv (CM_MO_Sig_Fahrpedalgradient_Cx0_Fahrpedalgradient_positiv) (Fahrpedalgradient positiv), 1=Cx1_Fahrpedalgradient_negativ (CM_MO_Sig_Fahrpedalgradient_Cx1_Fahrpedalgradient_negativ) (Fahrpedalgradient negativ)}, range raw 0..1, transfer-property=PENDING  # Kennzeichnet das Vorzeichen des Signal "Fahrpedalgradient". Die Ausgabe erfolgt nur parallel statisch mit gesendetem Signal: "Steuerungsbit Fahrpedalgradient"
          signal MO_rel_Saugrohrdruck_XIX_Motor_51_Auth_XIX_E3V_K2CANFD: start 30, 6 bit, little-endian, data-type-policy=OVERRIDE, i-signal-type=PRIMITIVE, init-value=0, base-type=BT_MO_rel_Saugrohrdruck, invalid-value=Invalid_MO_rel_Saugrohrdruck_XIX_Motor_51_Auth_XIX_E3V_K2CANFD:63, compu {phys=raw*18 for raw 0..62, 0=Cx0_Init_Ueberdruck (CM_MO_rel_Saugrohrdruck_Cx0_Init_Ueberdruck), 63=Cx3f_Fehler (CM_MO_rel_Saugrohrdruck_Cx3f_Fehler); unit Unit_MilliBar}, range phys 0..1116 Unit_MilliBar, raw 0..63, unit=Unit_MilliBar, transfer-property=PENDING  # Der Wert gibt an, um wieviel mbar der Saugrohrdruck unterhalb des Umgebungsdrucks liegt. Überdruck im Saugrohr wird nicht ausgegeben. 0: Saugrohrdruck=Umgebungsdruck
          signal MO_rel_Saugrohrdruck_gem_err_XIX_Motor_51_Auth_XIX_E3V_K2CANFD: start 36, 1 bit, little-endian, data-type-policy=OVERRIDE, i-signal-type=PRIMITIVE, init-value=0, base-type=BT_MO_rel_Saugrohrdruck_gem_err, compu {0=Cx0_errechnet (CM_MO_rel_Saugrohrdruck_gem_err_Cx0_errechnet), 1=Cx1_gemessen (CM_MO_rel_Saugrohrdruck_gem_err_Cx1_gemessen)}, range raw 0..1, transfer-property=PENDING  # 0: mind. eine Modellrechnung wird zur Berechnung des relativen Saugdrucks herangezogen 1: Relativer Saugrohrdruck wird ausschließlich über Messgrößen bestimmt
          signal MO_Moment_im_Leerlauf_XIX_Motor_51_Auth_XIX_E3V_K2CANFD: start 37, 1 bit, little-endian, data-type-policy=OVERRIDE, i-signal-type=PRIMITIVE, init-value=0, base-type=BT_MO_Moment_im_Leerlauf, compu {0=Cx0_kein_Leergas (CM_MO_Moment_im_Leerlauf_Cx0_kein_Leergas), 1=Cx1_Leergas (CM_MO_Moment_im_Leerlauf_Cx1_Leergas)}, range raw 0..1, transfer-property=PENDING  # Fahrerwunschmoment ist minimal: keine Momentenanforderung durch Fahrpedal, ACC oder GRA+; (Das Signal ist unabhängig von Momentenerhöhungen durch Leerlaufregler oder MSR). AUDI D4: Zykluszeit: 10ms (siehe Zykluszeit schnell/Cycletime Fast) Achtung: Reduktion der Zykluszeit Motor_03 auf 10ms geplant. Projektabhängig soll künftig mit 10ms gesendet werden. Empfänger die in weiteren Konzern-Projekten eingesetzt werden müssen dazu beide Zykluszeiten (10/20ms) unterstützen. Empfänger muss in diesem Fall für die Timeoutdiagnose und CAN-Messwerteblöcke mit 20ms auslegen.
          signal MO_Schubabschaltung_XIX_Motor_51_Auth_XIX_E3V_K2CANFD: start 38, 1 bit, little-endian, data-type-policy=OVERRIDE, i-signal-type=PRIMITIVE, init-value=0, base-type=BT_MO_Schubabschaltung, compu {0=Cx0_keine_Schubabschaltung (CM_MO_Schubabschaltung_Cx0_keine_Schubabschaltung), 1=Cx1_Schubabschaltung_aktiv (CM_MO_Schubabschaltung_Cx1_Schubabschaltung_aktiv)}, range raw 0..1, transfer-property=PENDING  # ESP plausibilisiert Unterdrucksensor nur bei aktiver Schubabschaltung MLBevo: Signal wird nur in MLBevo Projekten mit PDKII Getriebe bedient. In allen anderen MLBevo Projekten wird das Signal mit "0" bedient PDKII berücksichtigt Verzugszeiten, die in der Umsetzung von Eingriffen durch den Motor reproduzierbar auftreten. Im Zustand Schubabschaltung bzw. Vollausblendung, tritt eine längere Mindest-Verzugszeit auf, die das PDKII anhand des Signals berücksichtigen kann um damit eine besser Spontanität bei z.B. Schubrückschaltungen zu erreichen.
          signal MO_StartStopp_StoppVorbereitung_XIX_Motor_51_Auth_XIX_E3V_K2CANFD: start 39, 1 bit, little-endian, data-type-policy=OVERRIDE, i-signal-type=PRIMITIVE, init-value=0, base-type=BT_MO_StartStopp_StoppVorbereitung, compu {0=Cx0_Motorstopp_nicht_in_Vorbereitung (CM_MO_StartStopp_StoppVorbereitung_Cx0_Motorstopp_nicht_in_Vorbereitung), 1=Cx1_Motorstopp_in_Vorbereitung (CM_MO_StartStopp_StoppVorbereitung_Cx1_Motorstopp_in_Vorbereitung)}, range raw 0..1, transfer-property=PENDING  # Zeigt allen aktiven Start-/Stoppteilnehmern einen möglichen Motorstopp im Anhaltevorgang an (Empfänger notwendige Vorbereitungen treffen) Es liegen keine Vetos vor.
          signal MO_Solldrehz_Leerlauf_XIX_Motor_51_Auth_XIX_E3V_K2CANFD: start 40, 8 bit, little-endian, data-type-policy=OVERRIDE, i-signal-type=PRIMITIVE, init-value=0, base-type=BT_MO_Solldrehz_Leerlauf, compu {phys=raw*10 for raw 0..254; unit Unit_MinutInver}, range phys 0..2540 Unit_MinutInver, raw 0..254, unit=Unit_MinutInver, transfer-property=PENDING  # Leerlaufsolldrehzahl, die im Motor eingestellt ist (Bei Parallelhybrid im E-Fahr-Betrieb Leerlaufsolldrehzahl der E-Maschine). Der Motor paßt aufgrund der Anforderung von anderen Steuergeräten seine Leerlaufsolldrehzahl an, bspw. Kat-Heizen, Anforderung vom Getriebe etc. Hinweis: Ehemaliger Fehlerwert 0xFF wird senderseitig nicht unterstützt. Diesen Wert aus Kompatibilitätsgründen nicht neu belegen!
          signal MO_Entkopplung_Sollschlupf_XIX_Motor_51_Auth_XIX_E3V_K2CANFD: start 48, 7 bit, little-endian, data-type-policy=OVERRIDE, i-signal-type=PRIMITIVE, init-value=126, base-type=BT_MO_Entkopplung_Sollschlupf, compu {phys=raw*20 for raw 0..124, 125=Cx7d_Notoeffnen_Anfahrelement (CM_MO_Entkopplung_Sollschlupf_Cx7d_Notoeffnen_Anfahrelement), 126=Cx7e_Init (CM_MO_Entkopplung_Sollschlupf_Cx7e_Init); unit Unit_MinutInver}, range phys 0..2480 Unit_MinutInver, raw 0..126, unit=Unit_MinutInver, transfer-property=PENDING  # MSG fordert von GSG an, das Anfahrelement (Fahr-/Wandlerkupplung) zu entkoppeln; das GSG soll die gesendete Drehzahl als Schlupf einstellen und ggf. die Regler-Parameter umschalten, damit Rucke aus dem Antrieb nicht im Fahrzeug spürbar werden; nutzbar z.B. für Zustart VKM bei Hybrid-Projekten oder für Umschaltungen Halb-/Voll-Motor-Betrieb. Hinweis: Ehemaliger Fehlerwert 0x7F wird senderseitig nicht unterstützt. Diesen Wert aus Kompatibilitätsgründen nicht neu belegen! Es wird jeweils projektspezifisch festgelegt, ob das Getriebe auf den Wert 125 = "Notöffnen Anfahrelement" reagieren muss.
          signal MO_temporaere_Fahrerabwesenheit_XIX_Motor_51_Auth_XIX_E3V_K2CANFD: start 55, 1 bit, little-endian, data-type-policy=OVERRIDE, i-signal-type=PRIMITIVE, init-value=0, base-type=BT_MO_temporaere_Fahrerabwesenheit, compu {0=Cx0_nicht_erkannt (CM_MO_temporaere_Fahrerabwesenheit_Cx0_nicht_erkannt), 1=Cx1_erkannt (CM_MO_temporaere_Fahrerabwesenheit_Cx1_erkannt)}, range raw 0..1, transfer-property=PENDING  # Das Signal dient zur Signalisierung einer temporären Abwesenheit des Fahrers. In dieser Zeit ist es ihm möglich, sich durch gewisse ¿ im Verlassenskonzept definierte ¿ Fahreraktionen im aktuellen Fahrzyklus zurückzumelden. Das Signal wird gesetzt, sobald der im MSG definierte Timer startet und zurückgenommen, wenn der Fahrer als dauerhaft anwesend erkannt wird (Start/Stopp gesperrt) oder sich der Fahrer innerhalb einer definierten Zeit zurückmeldet.
          signal TSK_a_Soll_gradientenbegrenzt_XIX_Motor_51_Auth_XIX_E3V_K2CANFD: start 57, 7 bit, little-endian, data-type-policy=OVERRIDE, i-signal-type=PRIMITIVE, init-value=127, base-type=BT_TSK_a_Soll_gradientenbegrenzt, compu {phys=raw*0.1-7.2 for raw 0..126, 127=Cx7f_Init_oder_nicht_aktiv (CM_TSK_a_Soll_gradientenbegrenzt_Cx7f_Init_oder_nicht_aktiv); unit Unit_MeterPerSeconSquar}, range phys -7.2..5.4 Unit_MeterPerSeconSquar, raw 0..127, unit=Unit_MeterPerSeconSquar, transfer-property=PENDING  # TSK Sollbeschleunigung für Fahrerassistenzsysteme mit aktiver Längsführung (GRA, ACC, IPA...). Der Wert stellt den ruckbegrenzten Sollwert der TSK-Regelung dar und ist Basis der TSK-Antriebs- und Bremsmomentenvorsteuerung.
          signal LnchCtl_StReq_XIX_Motor_51_Auth_XIX_E3V_K2CANFD: start 72, 4 bit, little-endian, data-type-policy=OVERRIDE, i-signal-type=PRIMITIVE, init-value=0, base-type=BT_LnchCtl_StReq, compu {0=Cx0_init_inactive (CM_LnchCtl_StReq_Cx0_init_inactive) (init/inactive), 1=Cx1_launch_control_preparation_phase (CM_LnchCtl_StReq_Cx1_launch_control_preparation_phase) (launch control - preparation phase), 2=Cx2_launch_control_active (CM_LnchCtl_StReq_Cx2_launch_control_active) (launch control - active), 3=Cx3_launch_control_preconditioning_requested (CM_LnchCtl_StReq_Cx3_launch_control_preconditioning_requested) (launch control - preconditioning requested), 4=Cx4_electric_launch_control_preparation_phase (CM_LnchCtl_StReq_Cx4_electric_launch_control_preparation_phase) (electric launch control - preparation phase), 5=Cx5_electric_launch_control_active (CM_LnchCtl_StReq_Cx5_electric_launch_control_active) (electric launch control - active), 6=Cx6_electric_launch_control_preconditioning_requested (CM_LnchCtl_StReq_Cx6_electric_launch_control_preconditioning_requested) (electric launch control - preconditioning requested), 7=Cx7_launch_control_light_preparation_phase (CM_LnchCtl_StReq_Cx7_launch_control_light_preparation_phase) (launch control light - preparation phase), 8=Cx8_launch_control_light_active (CM_LnchCtl_StReq_Cx8_launch_control_light_active) (launch control light - active), 9=Cx9_Reserved (CM_LnchCtl_StReq_Cx9_Reserved)}, range raw 0..9, transfer-property=PENDING, to SAM(timeout 0.5 s)  # Status Request Launch Control.
          signal TSK_Radbremsmom_XIX_Motor_51_Auth_XIX_E3V_K2CANFD: start 76, 12 bit, little-endian, data-type-policy=OVERRIDE, i-signal-type=PRIMITIVE, init-value=0, base-type=BT_TSK_Radbremsmom, compu {phys=raw*8 for raw 0..4095; unit Unit_NewtoMeter}, range phys 0..32760 Unit_NewtoMeter, raw 0..4095, unit=Unit_NewtoMeter, transfer-property=PENDING  # Bei der Schnittstelle vom TSK zum ESP soll in Folgeprojekten des B8 und insbesondere bei VW-Projekten die Ansteuerung der Bremse nicht über Sollbeschleunigung sondern Bremsmoment erfolgen. Es handelt sich genauer um das Summenradbremsmoment, welches die Bremse einstellen soll. Die Umsetzung der Anforderung durch das ESP wird mittels Freigabe TSK_Freig_Verzoeg_Anf freigegeben. Beide Werte (Freigabe und Anforderung) müssen in der gleichen Botschaft liegen. Signal ist z.Zt. Vorhalt für Radbremsmoment (analog PQ46-Konzept) im Audi B8-Projekt nicht unterstützt
          signal TSK_Status_XIX_Motor_51_Auth_XIX_E3V_K2CANFD: start 88, 3 bit, little-endian, data-type-policy=OVERRIDE, i-signal-type=PRIMITIVE, init-value=1, base-type=BT_TSK_Status, compu {0=Cx0_Hauptschalter_aus (CM_TSK_Status_Cx0_Hauptschalter_aus), 1=Cx1_Init (CM_TSK_Status_Cx1_Init), 2=Cx2_passiv (CM_TSK_Status_Cx2_passiv), 3=Cx3_aktiv (CM_TSK_Status_Cx3_aktiv), 4=Cx4_Uebertreten (CM_TSK_Status_Cx4_Uebertreten), 5=Cx5_brake_only_Mode (CM_TSK_Status_Cx5_brake_only_Mode), 6=Cx6_reversibel_aus (CM_TSK_Status_Cx6_reversibel_aus), 7=Cx7_irreversibel_aus (CM_TSK_Status_Cx7_irreversibel_aus)}, range raw 0..7, transfer-property=PENDING  # Betriebszustand des TSK-Reglers
          signal TSK_v_Begrenzung_aktiv_XIX_Motor_51_Auth_XIX_E3V_K2CANFD: start 91, 1 bit, little-endian, data-type-policy=OVERRIDE, i-signal-type=PRIMITIVE, init-value=0, base-type=BT_TSK_v_Begrenzung_aktiv, compu {0=Cx0_inaktiv (CM_TSK_v_Begrenzung_aktiv_Cx0_inaktiv), 1=Cx1_aktiv (CM_TSK_v_Begrenzung_aktiv_Cx1_aktiv)}, range raw 0..1, transfer-property=PENDING  # Limiter oder HGB begrenzen die Beschleunigung/das Moment
          signal TSK_Standby_Anf_ESP_XIX_Motor_51_Auth_XIX_E3V_K2CANFD: start 92, 1 bit, little-endian, data-type-policy=OVERRIDE, i-signal-type=PRIMITIVE, init-value=0, base-type=BT_TSK_Standby_Anf_ESP, compu {0=Cx0_keine_Standby_Anforderung (CM_TSK_Standby_Anf_ESP_Cx0_keine_Standby_Anforderung), 1=Cx1_Standby_Anforderung (CM_TSK_Standby_Anf_ESP_Cx1_Standby_Anforderung)}, range raw 0..1, transfer-property=PENDING  # Mit diesem Bit wird das aktive Bremssystem auf eine anstehende TSK-Verzögerungsanforderung vorbereitet (Überfahren Leerweg, Anlegen Bremsbeläge)
          signal TSK_Freig_Verzoeg_Anf_XIX_Motor_51_Auth_XIX_E3V_K2CANFD: start 94, 1 bit, little-endian, data-type-policy=OVERRIDE, i-signal-type=PRIMITIVE, init-value=0, base-type=BT_TSK_Freig_Verzoeg_Anf, compu {0=Cx0_Verzoegerungsanforderung_nicht_freigegeben (CM_TSK_Freig_Verzoeg_Anf_Cx0_Verzoegerungsanforderung_nicht_freigegeben), 1=Cx1_Verzoegerungsanforderung_freigegeben (CM_TSK_Freig_Verzoeg_Anf_Cx1_Verzoegerungsanforderung_freigegeben)}, range raw 0..1, transfer-property=PENDING  # Freigabe der Verzögerungsanforderung der ACC oder ggf. GRA+ Funktion für ECD Regelung im ESP
          signal TSK_Limiter_ausgewaehlt_XIX_Motor_51_Auth_XIX_E3V_K2CANFD: start 95, 1 bit, little-endian, data-type-policy=OVERRIDE, i-signal-type=PRIMITIVE, init-value=0, base-type=BT_TSK_Limiter_ausgewaehlt, compu {0=Cx0_kein_Limiter_ausgewaehlt (CM_TSK_Limiter_ausgewaehlt_Cx0_kein_Limiter_ausgewaehlt), 1=Cx1_Limiter_ausgewaehlt (CM_TSK_Limiter_ausgewaehlt_Cx1_Limiter_ausgewaehlt)}, range raw 0..1, transfer-property=PENDING  # ACC/GRA-Betrieb nur bei nicht ausgewähltem Limiter möglich
          signal TSK_Hauptschalter_GRA_ACC_XIX_Motor_51_Auth_XIX_E3V_K2CANFD: start 106, 2 bit, little-endian, data-type-policy=OVERRIDE, i-signal-type=PRIMITIVE, init-value=0, base-type=BT_TSK_Hauptschalter_GRA_ACC, invalid-value=Invalid_TSK_Hauptschalter_GRA_ACC_XIX_Motor_51_Auth_XIX_E3V_K2CANFD:3, compu {0=Cx0_Init (CM_TSK_Hauptschalter_GRA_ACC_Cx0_Init), 1=Cx1_Aus (CM_TSK_Hauptschalter_GRA_ACC_Cx1_Aus), 2=Cx2_Ein (CM_TSK_Hauptschalter_GRA_ACC_Cx2_Ein), 3=Cx3_Fehler (CM_TSK_Hauptschalter_GRA_ACC_Cx3_Fehler)}, range raw 0..3, transfer-property=PENDING  # Stellung des GRA/ACC Hauptschalters. Das Signal wird auch bei Fehlerabschaltungen von GRA/ACC weiterhin bedient und ermöglicht für ACC die Steuerung der ACC-Anzeige auch in Fehlerfällen.
          signal TSK_SRBM_Anf_ASIL_XIX_Motor_51_Auth_XIX_E3V_K2CANFD: start 108, 3 bit, little-endian, data-type-policy=OVERRIDE, i-signal-type=PRIMITIVE, init-value=0, base-type=BT_TSK_SRBM_Anf_ASIL, compu {0=Cx0_keine_SRBM_Anforderung (CM_TSK_SRBM_Anf_ASIL_Cx0_keine_SRBM_Anforderung), 1=Cx1_SRBM_Anforderung_in_ASIL_QM (CM_TSK_SRBM_Anf_ASIL_Cx1_SRBM_Anforderung_in_ASIL_QM), 2=Cx2_SRBM_Anforderung_in_ASIL_A (CM_TSK_SRBM_Anf_ASIL_Cx2_SRBM_Anforderung_in_ASIL_A), 3=Cx3_SRBM_Anforderung_in_ASIL_B (CM_TSK_SRBM_Anf_ASIL_Cx3_SRBM_Anforderung_in_ASIL_B), 4=Cx4_SRBM_Anforderung_in_ASIL_C (CM_TSK_SRBM_Anf_ASIL_Cx4_SRBM_Anforderung_in_ASIL_C)}, range raw 0..4, transfer-property=PENDING  # ASIL-Level des TSK-Anforderers, der aktuell eine Bremsmomentenanforderung auslöst
          signal TSK_ax_Getriebe_02_XIX_Motor_51_Auth_XIX_E3V_K2CANFD: start 112, 9 bit, little-endian, data-type-policy=OVERRIDE, i-signal-type=PRIMITIVE, init-value=511, base-type=BT_TSK_ax_Getriebe_02, compu {phys=raw*0.024-2.016 for raw 0..510, 511=Cx1ff_Neutralwert (CM_TSK_ax_Getriebe_02_Cx1ff_Neutralwert); unit Unit_MeterPerSeconSquar}, range phys -2.016..10.224 Unit_MeterPerSeconSquar, raw 0..511, unit=Unit_MeterPerSeconSquar, transfer-property=PENDING  # Beschleunigungsanforderung des Beschleunigungsreglers (u. a. für ACC, GRA, Speed Limiter). Das Signal wird vom Getriebe benutzt, um die von GRA/ACC geforderte Sollbeschleunigung in dem verbrauchsgünstigsten Gang einzustellen. MQB: Im MQB wird die Sollbeschleunigung für den GRA/ACC-Betrieb um die zulässige Regelabweichung nach unten reduziert; das Signal TSK_zul_Regelabw wird daher im MQB nicht vom Getriebe eingelesen.
          signal TSK_Zwangszusch_ESP_XIX_Motor_51_Auth_XIX_E3V_K2CANFD: start 121, 1 bit, little-endian, data-type-policy=OVERRIDE, i-signal-type=PRIMITIVE, init-value=0, base-type=BT_TSK_Zwangszusch_ESP, compu {0=Cx0_keine_ESP_ASR_Beeinflussung (CM_TSK_Zwangszusch_ESP_Cx0_keine_ESP_ASR_Beeinflussung), 1=Cx1_ESP_ASR_Beeinflussung (CM_TSK_Zwangszusch_ESP_Cx1_ESP_ASR_Beeinflussung)}, range raw 0..1, transfer-property=PENDING  # Mit diesem Bit wird das ESP/ASR zwangsweise aktiviert. Bei gesetztem Bit ist ein ausgetastetes ESP (oder ASR) wieder aktiviert bzw. wird die Austastung verhindert.
          signal TSK_zul_Regelabw_XIX_Motor_51_Auth_XIX_E3V_K2CANFD: start 122, 6 bit, little-endian, data-type-policy=OVERRIDE, i-signal-type=PRIMITIVE, init-value=0, base-type=BT_TSK_zul_Regelabw, compu {phys=raw*0.024 for raw 0..63; unit Unit_MeterPerSeconSquar}, range phys 0..1.512 Unit_MeterPerSeconSquar, raw 0..63, unit=Unit_MeterPerSeconSquar, transfer-property=PENDING  # Anforderung der zulässigen Regelabweichung vom Triebstrangkoordinator. Zulässiger Betrag der Abweichung zwischen angeforderter 'TSK_Sollbeschleunigung_Getriebe' und umzusetzender Sollbeschleunigung im Getriebe. Im TSK wird, abhängig vom Arbeitspunkt die Toleranz und die Sollbeschleunigung für das Getriebe beeinflusst. Ziel ist, unnötige Rückschaltungen zu vermeiden. MQB: Da die zulässige Regelabweichung im MQB bereits im Signal TSK_ax_Getriebe_02 enthalten ist, wir die TSK_zul_Regelabw vom MQB Getriebe nicht verwendet.
          signal TSK_Radsollmoment_XIX_Motor_51_Auth_XIX_E3V_K2CANFD: start 128, 16 bit, little-endian, data-type-policy=OVERRIDE, i-signal-type=PRIMITIVE, init-value=65534, base-type=BT_TSK_Radsollmoment, invalid-value=Invalid_TSK_Radsollmoment_XIX_Motor_51_Auth_XIX_E3V_K2CANFD:65535, compu {phys=raw*0.5-16383 for raw 0..65533, 65534=Cxfffe_Init (CM_TSK_Radsollmoment_Cxfffe_Init), 65535=Cxffff_Fehler (CM_TSK_Radsollmoment_Cxffff_Fehler); unit Unit_NewtoMeter}, range phys -16383..16383.5 Unit_NewtoMeter, raw 0..65535, unit=Unit_NewtoMeter, transfer-property=PENDING  # Sollradmoment vom TSK
          signal TSK_Kategorie_Verzoegerungsfkt_XIX_Motor_51_Auth_XIX_E3V_K2CANFD: start 144, 2 bit, little-endian, data-type-policy=OVERRIDE, i-signal-type=PRIMITIVE, init-value=0, base-type=BT_TSK_Kategorie_Verzoegerungsfkt, compu {0=Cx0_Schnittstelle_nicht_vorhanden (CM_TSK_Kategorie_Verzoegerungsfkt_Cx0_Schnittstelle_nicht_vorhanden), 1=Cx1_Kategorie_Fahrerassistenz (CM_TSK_Kategorie_Verzoegerungsfkt_Cx1_Kategorie_Fahrerassistenz), 2=Cx2_Kategorie_Schubverzoegerung (CM_TSK_Kategorie_Verzoegerungsfkt_Cx2_Kategorie_Schubverzoegerung), 3=Cx3_reserviert (CM_TSK_Kategorie_Verzoegerungsfkt_Cx3_reserviert)}, range raw 0..3, transfer-property=PENDING  # Zeigt der Bremslichtfunktion an, ob die aktuell verzögerungswirksame Teilnehmerfunktion am TSK als Fahrerassistenzsystem oder als Schubrekuperation zu interpretieren ist.
          signal TSK_a_Soll_gradientenbegrenzt_02_XIX_Motor_51_Auth_XIX_E3V_K2CANFD: start 146, 11 bit, little-endian, data-type-policy=OVERRIDE, i-signal-type=PRIMITIVE, init-value=2047, base-type=BT_TSK_a_Soll_gradientenbegrenzt_02, compu {phys=raw*0.0125-13 for raw 0..2046, 2047=Cx7ff_Init_oder_nicht_aktiv (CM_TSK_a_Soll_gradientenbegrenzt_02_Cx7ff_Init_oder_nicht_aktiv); unit Unit_MeterPerSeconSquar}, range phys -13..12.575 Unit_MeterPerSeconSquar, raw 0..2047, unit=Unit_MeterPerSeconSquar, transfer-property=PENDING  # Arbitrierte TSK Sollbeschleunigung über Grund im Fahrstufenkoordinatensystem. Der Wert stellt den ruckbegrenzten Sollwert der TSK-Regelung dar und ist Basis der TSK-Antriebs- und Bremsmomentenvorsteuerung. Enthalten ist explizit auch die Fahrerwunschbeschleunigung (Projekte mit OPD) bzw. ein entsprechendes Äquivalent.
          signal MO_OBFCM_Reserve_XIX_Motor_51_Auth_XIX_E3V_K2CANFD: start 160, 32 bit, little-endian, data-type-policy=OVERRIDE, i-signal-type=PRIMITIVE, init-value=0, base-type=BT_MO_OBFCM_Reserve, compu {phys=raw for raw 0..4294967295}, range phys 0..4294967295, raw 0..4294967295, transfer-property=PENDING  # OBFCM Parameter Reserve
          signal TSK_Notstopp_Anf_XIX_Motor_51_Auth_XIX_E3V_K2CANFD: start 233, 2 bit, little-endian, data-type-policy=OVERRIDE, i-signal-type=PRIMITIVE, init-value=0, base-type=BT_TSK_Notstopp_Anf, compu {0=Cx0_Ueberwachung_aus (CM_TSK_Notstopp_Anf_Cx0_Ueberwachung_aus), 1=Cx1_Ueberwachung_ein (CM_TSK_Notstopp_Anf_Cx1_Ueberwachung_ein), 2=Cx2_Notstopp_ausloesen (CM_TSK_Notstopp_Anf_Cx2_Notstopp_ausloesen)}, range raw 0..2, transfer-property=PENDING  # Anforderung Notstopp des TSK
          signal MO_Status_MinDrzEingriff_XIX_Motor_51_Auth_XIX_E3V_K2CANFD: start 235, 3 bit, little-endian, data-type-policy=OVERRIDE, i-signal-type=PRIMITIVE, init-value=0, base-type=BT_MO_Status_MinDrzEingriff, compu {0=Cx0_kein_Eingriff (CM_MO_Status_MinDrzEingriff_Cx0_kein_Eingriff), 1=Cx1_Schalteingriff (CM_MO_Status_MinDrzEingriff_Cx1_Schalteingriff), 2=Cx2_ESP_Eingriff (CM_MO_Status_MinDrzEingriff_Cx2_ESP_Eingriff), 3=Cx3_Achsdifferenzdrehzahl (CM_MO_Status_MinDrzEingriff_Cx3_Achsdifferenzdrehzahl), 4=Cx4_Bauteilschutz (CM_MO_Status_MinDrzEingriff_Cx4_Bauteilschutz), 5=Cx5_Rennstart_Fahrbarkeit (CM_MO_Status_MinDrzEingriff_Cx5_Rennstart_Fahrbarkeit)}, range raw 0..5, transfer-property=PENDING  # Aktuell drehzahlführender Anforderer der Minimaldrehzahl (Begrenzungsregelung) des Pulswechselrichters der Primärachse.
          signal MO_Status_MaxDrzEingriff_XIX_Motor_51_Auth_XIX_E3V_K2CANFD: start 238, 3 bit, little-endian, data-type-policy=OVERRIDE, i-signal-type=PRIMITIVE, init-value=0, base-type=BT_MO_Status_MaxDrzEingriff, compu {0=Cx0_kein_Eingriff (CM_MO_Status_MaxDrzEingriff_Cx0_kein_Eingriff), 1=Cx1_Schalteingriff (CM_MO_Status_MaxDrzEingriff_Cx1_Schalteingriff), 2=Cx2_ESP_Eingriff (CM_MO_Status_MaxDrzEingriff_Cx2_ESP_Eingriff), 3=Cx3_Achsdifferenzdrehzahl (CM_MO_Status_MaxDrzEingriff_Cx3_Achsdifferenzdrehzahl), 4=Cx4_Bauteilschutz (CM_MO_Status_MaxDrzEingriff_Cx4_Bauteilschutz), 5=Cx5_Rennstart_Fahrbarkeit (CM_MO_Status_MaxDrzEingriff_Cx5_Rennstart_Fahrbarkeit)}, range raw 0..5, transfer-property=PENDING  # Aktuell drehzahlführender Anforderer der Maximaldrehzahl (Begrenzungsregelung) des Pulswechselrichters der Primärachse.
          signal MO_Status_MinDrzEingriff_sek_XIX_Motor_51_Auth_XIX_E3V_K2CANFD: start 241, 3 bit, little-endian, data-type-policy=OVERRIDE, i-signal-type=PRIMITIVE, init-value=0, base-type=BT_MO_Status_MinDrzEingriff_sek, compu {0=Cx0_kein_Eingriff (CM_MO_Status_MinDrzEingriff_sek_Cx0_kein_Eingriff), 1=Cx1_Schalteingriff (CM_MO_Status_MinDrzEingriff_sek_Cx1_Schalteingriff), 2=Cx2_ESP_Eingriff (CM_MO_Status_MinDrzEingriff_sek_Cx2_ESP_Eingriff), 3=Cx3_Achsdifferenzdrehzahl (CM_MO_Status_MinDrzEingriff_sek_Cx3_Achsdifferenzdrehzahl), 4=Cx4_Bauteilschutz (CM_MO_Status_MinDrzEingriff_sek_Cx4_Bauteilschutz), 5=Cx5_Rennstart_Fahrbarkeit (CM_MO_Status_MinDrzEingriff_sek_Cx5_Rennstart_Fahrbarkeit)}, range raw 0..5, transfer-property=PENDING  # Aktuell drehzahlführender Anforderer der Minimaldrehzahl (Begrenzungsregelung) des Pulswechselrichters der Sekundärachse.
          signal MO_Status_MaxDrzEingriff_sek_XIX_Motor_51_Auth_XIX_E3V_K2CANFD: start 244, 3 bit, little-endian, data-type-policy=OVERRIDE, i-signal-type=PRIMITIVE, init-value=0, base-type=BT_MO_Status_MaxDrzEingriff_sek, compu {0=Cx0_kein_Eingriff (CM_MO_Status_MaxDrzEingriff_sek_Cx0_kein_Eingriff), 1=Cx1_Schalteingriff (CM_MO_Status_MaxDrzEingriff_sek_Cx1_Schalteingriff), 2=Cx2_ESP_Eingriff (CM_MO_Status_MaxDrzEingriff_sek_Cx2_ESP_Eingriff), 3=Cx3_Achsdifferenzdrehzahl (CM_MO_Status_MaxDrzEingriff_sek_Cx3_Achsdifferenzdrehzahl), 4=Cx4_Bauteilschutz (CM_MO_Status_MaxDrzEingriff_sek_Cx4_Bauteilschutz), 5=Cx5_Rennstart_Fahrbarkeit (CM_MO_Status_MaxDrzEingriff_sek_Cx5_Rennstart_Fahrbarkeit)}, range raw 0..5, transfer-property=PENDING  # Aktuell drehzahlführender Anforderer der Maximaldrehzahl (Begrenzungsregelung) des Pulswechselrichters der Sekundärachse.
          signal TSK_SRBM_max_Gradient_XIX_Motor_51_Auth_XIX_E3V_K2CANFD: start 248, 7 bit, little-endian, data-type-policy=OVERRIDE, i-signal-type=PRIMITIVE, init-value=126, base-type=BT_TSK_SRBM_max_Gradient, invalid-value=Invalid_TSK_SRBM_max_Gradient_XIX_Motor_51_Auth_XIX_E3V_K2CANFD:127, compu {phys=raw*50 for raw 0..125, 126=Cx7e_Init (CM_TSK_SRBM_max_Gradient_Cx7e_Init), 127=Cx7f_Fehler (CM_TSK_SRBM_max_Gradient_Cx7f_Fehler); unit Unit_NewtoMeterPerSecon}, range phys 0..6250 Unit_NewtoMeterPerSecon, raw 0..127, unit=Unit_NewtoMeterPerSecon, transfer-property=PENDING  # In diesem Signal wird der vom TSK maximal geforderte SummenRadBremsMomentengradient gesendet, der von der Bremse bei der Umsetzung der TSK-Verzögerung nicht überschritten werden darf.
      frame Motor_54_XIX_E3V_K2CANFD: id 0x14C, to SAM, frame-length=32, can-addressing-mode=STANDARD, can-frame-rx-behavior=CAN-FD, can-frame-tx-behavior=CAN-FD
        pdu Motor_54_XIX_E3V_K2CANFD: length=32, minimum-delay=0.01, transmission-mode-true-timing={cyclic-timing={time-offset=0.0, time-period=0.1}, event-controlled-timing={number-of-repetitions=0, repetition-period=0.0}}, unused-bit-pattern=0
          signal Motor_54_CRC_XIX_Motor_54_XIX_E3V_K2CANFD: start 0, 8 bit, little-endian, data-type-policy=OVERRIDE, i-signal-type=PRIMITIVE, base-type=BT_Motor_54_CRC, compu {phys=raw for raw 0..255}, range phys 0..255, raw 0..255, transfer-property=PENDING  # Für MLB: Berechnung siehe Lastenheft "Kommunikationsabsicherung für FlexRay und CAN" Ab MQB und MLBevo: Berechnung siehe Lastenheft "End-to-End Kommunikationsabsicherung" Endwerte siehe Begleitdokument "S-PDU Kennungsfolgen"
          signal Motor_54_BZ_XIX_Motor_54_XIX_E3V_K2CANFD: start 8, 4 bit, little-endian, data-type-policy=OVERRIDE, i-signal-type=PRIMITIVE, base-type=BT_Motor_54_BZ, compu {phys=raw for raw 0..15}, range phys 0..15, raw 0..15, transfer-property=PENDING  # 4bit Botschaftszähler, wird mit jeder Sendebotschaft inkrementiert
          signal MO_Anforderung_HMS_XIX_Motor_54_XIX_E3V_K2CANFD: start 12, 3 bit, little-endian, data-type-policy=OVERRIDE, i-signal-type=PRIMITIVE, init-value=0, base-type=BT_MO_Anforderung_HMS, compu {0=Cx0_keine_Anforderung (CM_MO_Anforderung_HMS_Cx0_keine_Anforderung), 1=Cx1_halten (CM_MO_Anforderung_HMS_Cx1_halten), 2=Cx2_parken (CM_MO_Anforderung_HMS_Cx2_parken), 3=Cx3_halten_Standby (CM_MO_Anforderung_HMS_Cx3_halten_Standby), 4=Cx4_anfahren (CM_MO_Anforderung_HMS_Cx4_anfahren), 5=Cx5_Loesen_ueber_Rampe (CM_MO_Anforderung_HMS_Cx5_Loesen_ueber_Rampe), 7=Cx7_HMS_uebernehmen (CM_MO_Anforderung_HMS_Cx7_HMS_uebernehmen)}, range raw 0..7, transfer-property=TRIGGERED-ON-CHANGE-WITHOUT-REPETITION  # Halteanforderung vom Motor an HMS
          signal FoD_DTC_TSK_GRA_XIX_Motor_54_XIX_E3V_K2CANFD: start 15, 1 bit, little-endian, data-type-policy=OVERRIDE, i-signal-type=PRIMITIVE, init-value=0, base-type=BT_FoD_DTC_TSK_GRA, compu {0=Cx0_Kein_DTC (CM_FoD_DTC_TSK_GRA_Cx0_Kein_DTC), 1=Cx1_DTC_vorhanden_oder_in_Quali (CM_FoD_DTC_TSK_GRA_Cx1_DTC_vorhanden_oder_in_Quali)}, range raw 0..1, transfer-property=PENDING  # DTC ist entweder bereits eingetragen oder wird eingetragen, sobald die zugehörige FoD Funktion freigeschaltet wird.
          signal TSK_vMax_aktuell_XIX_Motor_54_XIX_E3V_K2CANFD: start 16, 8 bit, little-endian, data-type-policy=OVERRIDE, i-signal-type=PRIMITIVE, init-value=255, base-type=BT_TSK_vMax_aktuell, compu {phys=raw for raw 0..253, 254=Cxfe_kein_Limit_aktiv (CM_TSK_vMax_aktuell_Cxfe_kein_Limit_aktiv), 255=Cxff_Init (CM_TSK_vMax_aktuell_Cxff_Init); unit Unit_KiloMeterPerHour}, range phys 0..253 Unit_KiloMeterPerHour, raw 0..255, unit=Unit_KiloMeterPerHour, transfer-property=PENDING  # Im aktuellen Betriebszustand global gültige Geschwindigkeitslimitierung.
          signal ISA_Status_XIX_Motor_54_XIX_E3V_K2CANFD: start 24, 3 bit, little-endian, data-type-policy=OVERRIDE, i-signal-type=PRIMITIVE, init-value=1, base-type=BT_ISA_Status, compu {0=Cx0_ISA_nicht_aktiv (CM_ISA_Status_Cx0_ISA_nicht_aktiv), 1=Cx1_Init (CM_ISA_Status_Cx1_Init), 2=Cx2_ISA_degradiert (CM_ISA_Status_Cx2_ISA_degradiert), 3=Cx3_ISA_aktiv (CM_ISA_Status_Cx3_ISA_aktiv), 4=Cx4_reserviert (CM_ISA_Status_Cx4_reserviert), 5=Cx5_reserviert (CM_ISA_Status_Cx5_reserviert), 6=Cx6_reserviert (CM_ISA_Status_Cx6_reserviert), 7=Cx7_reserviert (CM_ISA_Status_Cx7_reserviert)}, range raw 0..7, transfer-property=TRIGGERED-ON-CHANGE-WITHOUT-REPETITION  # Signalisiert den Status der Funktion Intelligent Speed Assist (ISA). Der Status zeigt an, ob ISA Tempolimits übernimmt und einregelt. Dabei wird unterschieden, ob es sich um eine globale Aktivierung/Deaktivierung der Funktion, oder um eine temporäre Einschränkung der Tempolimit-Übernahme handelt.
          signal ISA_Regelung_aktiv_XIX_Motor_54_XIX_E3V_K2CANFD: start 27, 1 bit, little-endian, data-type-policy=OVERRIDE, i-signal-type=PRIMITIVE, init-value=0, base-type=BT_ISA_Regelung_aktiv, compu {0=Cx0_ISA_Regelung_nicht_aktiv (CM_ISA_Regelung_aktiv_Cx0_ISA_Regelung_nicht_aktiv), 1=Cx1_ISA_Regelung_aktiv (CM_ISA_Regelung_aktiv_Cx1_ISA_Regelung_aktiv)}, range raw 0..1, transfer-property=TRIGGERED-ON-CHANGE-WITHOUT-REPETITION  # Signalisiert, dass die Regelung zur Überführung der Fahrzeuggeschwindigkeit auf ein gültiges Tempolimit der Funktion Intelligent Speed Assist (ISA) aktiv ist.
          signal MO_Red_El_Fahrleistung_XIX_Motor_54_XIX_E3V_K2CANFD: start 29, 3 bit, little-endian, data-type-policy=OVERRIDE, i-signal-type=PRIMITIVE, init-value=0, base-type=BT_MO_Red_El_Fahrleistung, compu {0=Cx0_keine_Anzeige (CM_MO_Red_El_Fahrleistung_Cx0_keine_Anzeige), 1=Cx1_mehr_als_20Prcnt_Red (CM_MO_Red_El_Fahrleistung_Cx1_mehr_als_20Prcnt_Red), 2=Cx2_Reserve_1 (CM_MO_Red_El_Fahrleistung_Cx2_Reserve_1), 3=Cx3_Reserve_2 (CM_MO_Red_El_Fahrleistung_Cx3_Reserve_2), 4=Cx4_unter_GBB_Schwelle_Anhaenger (CM_MO_Red_El_Fahrleistung_Cx4_unter_GBB_Schwelle_Anhaenger), 5=Cx5_unter_GBB_Schwelle (CM_MO_Red_El_Fahrleistung_Cx5_unter_GBB_Schwelle), 6=Cx6_unter_minimal_Schwelle (CM_MO_Red_El_Fahrleistung_Cx6_unter_minimal_Schwelle), 7=Cx7_kein_Vortrieb (CM_MO_Red_El_Fahrleistung_Cx7_kein_Vortrieb)}, range raw 0..7, transfer-property=PENDING  # Anzeige einer eingeschränkten Fahrleistung
          signal TSK_Status_EA_XIX_Motor_54_XIX_E3V_K2CANFD: start 32, 3 bit, little-endian, data-type-policy=OVERRIDE, i-signal-type=PRIMITIVE, init-value=1, base-type=BT_TSK_Status_EA, invalid-value=Invalid_TSK_Status_EA_XIX_Motor_54_XIX_E3V_K2CANFD:7, compu {0=Cx0_Aus (CM_TSK_Status_EA_Cx0_Aus), 1=Cx1_Init_oder_nicht_verbaut (CM_TSK_Status_EA_Cx1_Init_oder_nicht_verbaut), 3=Cx3_Aktiv (CM_TSK_Status_EA_Cx3_Aktiv), 4=Cx4_Uebertreten (CM_TSK_Status_EA_Cx4_Uebertreten), 5=Cx5_Abschaltung_laeuft (CM_TSK_Status_EA_Cx5_Abschaltung_laeuft), 6=Cx6_Reversibel_aus (CM_TSK_Status_EA_Cx6_Reversibel_aus), 7=Cx7_Fehler (CM_TSK_Status_EA_Cx7_Fehler)}, range raw 0..7, transfer-property=TRIGGERED-ON-CHANGE-WITHOUT-REPETITION  # Funktionsstatus des Triebstrangkoordinators für den Anforderer Emergency Assist
          signal FoD_DTC_TSK_ACC_XIX_Motor_54_XIX_E3V_K2CANFD: start 35, 1 bit, little-endian, data-type-policy=OVERRIDE, i-signal-type=PRIMITIVE, init-value=0, base-type=BT_FoD_DTC_TSK_ACC, compu {0=Cx0_Kein_DTC (CM_FoD_DTC_TSK_ACC_Cx0_Kein_DTC), 1=Cx1_DTC_vorhanden_oder_in_Quali (CM_FoD_DTC_TSK_ACC_Cx1_DTC_vorhanden_oder_in_Quali)}, range raw 0..1, transfer-property=PENDING  # DTC ist entweder bereits eingetragen oder wird eingetragen, sobald die zugehörige FOD Funktion freigeschaltet wird.
          signal TSK_ACC_FoD_Status_XIX_Motor_54_XIX_E3V_K2CANFD: start 36, 2 bit, little-endian, data-type-policy=OVERRIDE, i-signal-type=PRIMITIVE, init-value=0, base-type=BT_TSK_ACC_FoD_Status, compu {0=Cx0_default (CM_TSK_ACC_FoD_Status_Cx0_default), 1=Cx1_nicht_aktiv (CM_TSK_ACC_FoD_Status_Cx1_nicht_aktiv), 2=Cx2_aktiv (CM_TSK_ACC_FoD_Status_Cx2_aktiv), 3=Cx3_nicht_genutzt (CM_TSK_ACC_FoD_Status_Cx3_nicht_genutzt)}, range raw 0..3, transfer-property=PENDING  # Information, ob die TSK-ACC-Funktion freigeschaltet ist oder nicht.
          signal TSK_GRA_FoD_Status_XIX_Motor_54_XIX_E3V_K2CANFD: start 38, 2 bit, little-endian, data-type-policy=OVERRIDE, i-signal-type=PRIMITIVE, init-value=0, base-type=BT_TSK_GRA_FoD_Status, compu {0=Cx0_default (CM_TSK_GRA_FoD_Status_Cx0_default), 1=Cx1_nicht_aktiv (CM_TSK_GRA_FoD_Status_Cx1_nicht_aktiv), 2=Cx2_aktiv (CM_TSK_GRA_FoD_Status_Cx2_aktiv), 3=Cx3_nicht_genutzt (CM_TSK_GRA_FoD_Status_Cx3_nicht_genutzt)}, range raw 0..3, transfer-property=PENDING  # Information, ob die TSK-GRA-Funktion freigeschaltet ist oder nicht.
          signal TSK_vMax_Fahrerassistenz_XIX_Motor_54_XIX_E3V_K2CANFD: start 40, 9 bit, little-endian, data-type-policy=OVERRIDE, i-signal-type=PRIMITIVE, init-value=511, base-type=BT_TSK_vMax_Fahrerassistenz, compu {phys=raw for raw 0..510, 511=Cx1ff_Init_ungueltig_keine_Beschraenkung (CM_TSK_vMax_Fahrerassistenz_Cx1ff_Init_ungueltig_keine_Beschraenkung)}, range phys 0..510, raw 0..511, transfer-property=PENDING  # maximale Sollgeschwindigkeit für GRA/ACC/Limiter Hinweis: Signal ist mit Signal TSK_Einheit_vMax_Fahrerassistenz zu interpretieren. Das Signal wird abwechselnd in km/h und mph gesendet.
          signal TSK_Einheit_vMax_Fahrerassistenz_XIX_Motor_54_XIX_E3V_K2CANFD: start 49, 1 bit, little-endian, data-type-policy=OVERRIDE, i-signal-type=PRIMITIVE, init-value=0, base-type=BT_TSK_Einheit_vMax_Fahrerassistenz, compu {0=Cx0_kmh (CM_TSK_Einheit_vMax_Fahrerassistenz_Cx0_kmh), 1=Cx1_mph (CM_TSK_Einheit_vMax_Fahrerassistenz_Cx1_mph)}, range raw 0..1, transfer-property=PENDING  # Einheit zu Signal TSK_vMax_Fahrerassistenz
          signal TSK_Status_PLA_XIX_Motor_54_XIX_E3V_K2CANFD: start 50, 3 bit, little-endian, data-type-policy=OVERRIDE, i-signal-type=PRIMITIVE, init-value=1, base-type=BT_TSK_Status_PLA, invalid-value=Invalid_TSK_Status_PLA_XIX_Motor_54_XIX_E3V_K2CANFD:7, compu {0=Cx0_Aus_Funktionsbereit (CM_TSK_Status_PLA_Cx0_Aus_Funktionsbereit), 1=Cx1_Init_oder_nicht_verbaut (CM_TSK_Status_PLA_Cx1_Init_oder_nicht_verbaut), 2=Cx2_aktivierbar (CM_TSK_Status_PLA_Cx2_aktivierbar), 3=Cx3_aktiv (CM_TSK_Status_PLA_Cx3_aktiv), 5=Cx5_Abschaltung_laeuft (CM_TSK_Status_PLA_Cx5_Abschaltung_laeuft), 6=Cx6_reversibel_aus (CM_TSK_Status_PLA_Cx6_reversibel_aus), 7=Cx7_Fehler (CM_TSK_Status_PLA_Cx7_Fehler)}, range raw 0..7, transfer-property=TRIGGERED-ON-CHANGE-WITHOUT-REPETITION  # Funktionsstatus des Triebstrangkoordinators für den Speedlimiter des Parkassistenten
          signal TSK_aktives_System_XIX_Motor_54_XIX_E3V_K2CANFD: start 53, 3 bit, little-endian, data-type-policy=OVERRIDE, i-signal-type=PRIMITIVE, init-value=0, base-type=BT_TSK_aktives_System, compu {0=Cx0_keine_Funktion_aktiv (CM_TSK_aktives_System_Cx0_keine_Funktion_aktiv), 1=Cx1_GRA_ACC (CM_TSK_aktives_System_Cx1_GRA_ACC), 2=Cx2_ARA (CM_TSK_aktives_System_Cx2_ARA), 3=Cx3_Speedlimiter (CM_TSK_aktives_System_Cx3_Speedlimiter), 4=Cx4_IPA (CM_TSK_aktives_System_Cx4_IPA), 5=Cx5_PLA (CM_TSK_aktives_System_Cx5_PLA), 6=Cx6_PEA_Ausrollassistent (CM_TSK_aktives_System_Cx6_PEA_Ausrollassistent), 7=Cx7_EA (CM_TSK_aktives_System_Cx7_EA)}, range raw 0..7, transfer-property=TRIGGERED-ON-CHANGE-WITHOUT-REPETITION  # Anzeige der in der TSK-Längsführung aktiven Funktion
          signal TSK_erhoehter_Fahrwiderstand_XIX_Motor_54_XIX_E3V_K2CANFD: start 56, 1 bit, little-endian, data-type-policy=OVERRIDE, i-signal-type=PRIMITIVE, init-value=0, base-type=BT_TSK_erhoehter_Fahrwiderstand, compu {0=Cx0_kein_erhoehter_Fahrwiderstand (CM_TSK_erhoehter_Fahrwiderstand_Cx0_kein_erhoehter_Fahrwiderstand), 1=Cx1_erhoehter_Fahrwiderstand (CM_TSK_erhoehter_Fahrwiderstand_Cx1_erhoehter_Fahrwiderstand)}, range raw 0..1, transfer-property=TRIGGERED-ON-CHANGE-WITHOUT-REPETITION  # Rueckmeldung vom Triebstrangkoordinator, dass eine große Reglerdifferenz detektiert wurde. Soll ermoeglichen, einen ggfs. unbekannten Fahrwiderstand am Boden zu erkennen.
          signal TSK_Anf_Antriebsmoment_XIX_Motor_54_XIX_E3V_K2CANFD: start 57, 1 bit, little-endian, data-type-policy=OVERRIDE, i-signal-type=PRIMITIVE, init-value=0, base-type=BT_TSK_Anf_Antriebsmoment, compu {0=Cx0_keine_Anforderung (CM_TSK_Anf_Antriebsmoment_Cx0_keine_Anforderung), 1=Cx1_Anforderung_aktiv (CM_TSK_Anf_Antriebsmoment_Cx1_Anforderung_aktiv)}, range raw 0..1, transfer-property=TRIGGERED-ON-CHANGE-WITHOUT-REPETITION  # Das Signal zeigt an, ob die TSK-Laengsregelung aktuell Antriebsmoment anfordert, zur Verwendung in der ASR/EDS-Funktion
          signal TSK_Status_ARA_XIX_Motor_54_XIX_E3V_K2CANFD: start 58, 3 bit, little-endian, data-type-policy=OVERRIDE, i-signal-type=PRIMITIVE, init-value=1, base-type=BT_TSK_Status_ARA, invalid-value=Invalid_TSK_Status_ARA_XIX_Motor_54_XIX_E3V_K2CANFD:7, compu {0=Cx0_Aus (CM_TSK_Status_ARA_Cx0_Aus), 1=Cx1_Init_oder_nicht_verbaut (CM_TSK_Status_ARA_Cx1_Init_oder_nicht_verbaut), 2=Cx2_aktivierbar (CM_TSK_Status_ARA_Cx2_aktivierbar), 3=Cx3_aktiv (CM_TSK_Status_ARA_Cx3_aktiv), 5=Cx5_abschaltung_laeuft (CM_TSK_Status_ARA_Cx5_abschaltung_laeuft), 6=Cx6_reversibel_aus (CM_TSK_Status_ARA_Cx6_reversibel_aus), 7=Cx7_Fehler (CM_TSK_Status_ARA_Cx7_Fehler)}, range raw 0..7, transfer-property=TRIGGERED-ON-CHANGE-WITHOUT-REPETITION  # Funktionsstatus des Triebstrangkoordinators für den Anhängerrangierassistenten
          signal TSK_Status_IPA_XIX_Motor_54_XIX_E3V_K2CANFD: start 61, 3 bit, little-endian, data-type-policy=OVERRIDE, i-signal-type=PRIMITIVE, init-value=1, base-type=BT_TSK_Status_IPA, invalid-value=Invalid_TSK_Status_IPA_XIX_Motor_54_XIX_E3V_K2CANFD:7, compu {0=Cx0_Aus_Funktionsbereit (CM_TSK_Status_IPA_Cx0_Aus_Funktionsbereit), 1=Cx1_Init_oder_nicht_verbaut (CM_TSK_Status_IPA_Cx1_Init_oder_nicht_verbaut), 2=Cx2_aktivierbar (CM_TSK_Status_IPA_Cx2_aktivierbar), 3=Cx3_aktiv (CM_TSK_Status_IPA_Cx3_aktiv), 4=Cx4_Fahreruebernahme_angefordert (CM_TSK_Status_IPA_Cx4_Fahreruebernahme_angefordert), 5=Cx5_Abschaltung_laueft (CM_TSK_Status_IPA_Cx5_Abschaltung_laueft), 6=Cx6_reversibel_aus (CM_TSK_Status_IPA_Cx6_reversibel_aus), 7=Cx7_Fehler (CM_TSK_Status_IPA_Cx7_Fehler)}, range raw 0..7, transfer-property=TRIGGERED-ON-CHANGE-WITHOUT-REPETITION  # Funktionsstatus des Triebstrangkoordinators für die Längsführung des Einparkassistenten
          signal TSK_aktives_System_02_XIX_Motor_54_XIX_E3V_K2CANFD: start 64, 4 bit, little-endian, data-type-policy=OVERRIDE, i-signal-type=PRIMITIVE, init-value=0, base-type=BT_TSK_aktives_System_02, compu {0=Cx0_keine_Funktion_aktiv (CM_TSK_aktives_System_02_Cx0_keine_Funktion_aktiv), 1=Cx1_GRA_ACC (CM_TSK_aktives_System_02_Cx1_GRA_ACC), 2=Cx2_ARA (CM_TSK_aktives_System_02_Cx2_ARA), 3=Cx3_Speedlimiter (CM_TSK_aktives_System_02_Cx3_Speedlimiter), 4=Cx4_IPA (CM_TSK_aktives_System_02_Cx4_IPA), 5=Cx5_PLA (CM_TSK_aktives_System_02_Cx5_PLA), 6=Cx6_PEA_Ausrollassistent (CM_TSK_aktives_System_02_Cx6_PEA_Ausrollassistent), 7=Cx7_EA (CM_TSK_aktives_System_02_Cx7_EA), 8=Cx8_Staupilot (CM_TSK_aktives_System_02_Cx8_Staupilot), 9=Cx9_RHP (CM_TSK_aktives_System_02_Cx9_RHP)}, range raw 0..9, transfer-property=TRIGGERED-ON-CHANGE-WITHOUT-REPETITION  # Anzeige der in der TSK-Längsführung aktiven Funktion
          signal TSK_Status_RHP_XIX_Motor_54_XIX_E3V_K2CANFD: start 68, 3 bit, little-endian, data-type-policy=OVERRIDE, i-signal-type=PRIMITIVE, init-value=0, base-type=BT_TSK_Status_RHP, compu {0=Cx0_off (CM_TSK_Status_RHP_Cx0_off), 1=Cx1_init (CM_TSK_Status_RHP_Cx1_init), 2=Cx2_standby (CM_TSK_Status_RHP_Cx2_standby), 3=Cx3_active (CM_TSK_Status_RHP_Cx3_active), 4=Cx4_driver_override (CM_TSK_Status_RHP_Cx4_driver_override), 5=Cx5_shutdown (CM_TSK_Status_RHP_Cx5_shutdown), 6=Cx6_reversible_failure (CM_TSK_Status_RHP_Cx6_reversible_failure), 7=Cx7_irreversible_failure (CM_TSK_Status_RHP_Cx7_irreversible_failure)}, range raw 0..7, transfer-property=TRIGGERED-ON-CHANGE-WITHOUT-REPETITION  # Functional status of the drive train coordinator for the longitudinal guidance of the rush hour pilot.
          signal MO_OnePedalDriving_integriert_XIX_Motor_54_XIX_E3V_K2CANFD: start 71, 1 bit, little-endian, data-type-policy=OVERRIDE, i-signal-type=PRIMITIVE, init-value=0, base-type=BT_MO_OnePedalDriving_integriert, compu {0=Cx0_OPD_nicht_integriert (CM_MO_OnePedalDriving_integriert_Cx0_OPD_nicht_integriert), 1=Cx1_OPD_integriert (CM_MO_OnePedalDriving_integriert_Cx1_OPD_integriert)}, range raw 0..1, transfer-property=PENDING  # Zeigt an, dass das Antriebssteuergerät die Funktion OnePedalDriving unterstützt.
          signal MO_Klima_Regelmodus_XIX_Motor_54_XIX_E3V_K2CANFD: start 74, 2 bit, little-endian, data-type-policy=OVERRIDE, i-signal-type=PRIMITIVE, init-value=0, base-type=BT_MO_Klima_Regelmodus, compu {0=Cx0_Init (CM_MO_Klima_Regelmodus_Cx0_Init), 1=Cx1_Regelmodus_1 (CM_MO_Klima_Regelmodus_Cx1_Regelmodus_1), 2=Cx2_Regelmodus_2 (CM_MO_Klima_Regelmodus_Cx2_Regelmodus_2), 3=Cx3_Regelmodus_3 (CM_MO_Klima_Regelmodus_Cx3_Regelmodus_3)}, range raw 0..3, transfer-property=PENDING  # Anforderung an Klima SG zur Regelungsanpassung der HV Klimakomponenten bei bestimmten Umweltbedingungen
          signal MO_Fahrbereitschaft_XIX_Motor_54_XIX_E3V_K2CANFD: start 76, 2 bit, little-endian, data-type-policy=OVERRIDE, i-signal-type=PRIMITIVE, init-value=0, base-type=BT_MO_Fahrbereitschaft, compu {0=Cx0_Fahrzykl_inaktiv_kein_Antrieb (CM_MO_Fahrbereitschaft_Cx0_Fahrzykl_inaktiv_kein_Antrieb) (Fahrzykl_inaktiv__kein_Antrieb), 1=Cx1_Fahrzykl_aktiv_kein_Antrieb (CM_MO_Fahrbereitschaft_Cx1_Fahrzykl_aktiv_kein_Antrieb) (Fahrzykl_aktiv__kein_Antrieb), 2=Cx2_Fahrzykl_aktiv_Antrieb_moeglich (CM_MO_Fahrbereitschaft_Cx2_Fahrzykl_aktiv_Antrieb_moeglich) (Fahrzykl_aktiv__Antrieb_moeglich)}, range raw 0..2, transfer-property=TRIGGERED-ON-CHANGE-WITHOUT-REPETITION, to SAM(timeout 1 s)  # Das Signal MO_Fahrbereitschaft zeigt in mehreren Stufen an, ob der Motor in einem anfahrbereiten Zustand ist.
          signal MO_Freilauf_Info_XIX_Motor_54_XIX_E3V_K2CANFD: start 78, 2 bit, little-endian, data-type-policy=OVERRIDE, i-signal-type=PRIMITIVE, init-value=0, base-type=BT_MO_Freilauf_Info, compu {0=Cx0_Freilauf_freigegeben (CM_MO_Freilauf_Info_Cx0_Freilauf_freigegeben), 1=Cx1_Weiches_Veto_uebertippbar (CM_MO_Freilauf_Info_Cx1_Weiches_Veto_uebertippbar), 2=Cx2_Hartes_Veto_Abbruch (CM_MO_Freilauf_Info_Cx2_Hartes_Veto_Abbruch), 3=Cx3_Freilauf_Anforderung (CM_MO_Freilauf_Info_Cx3_Freilauf_Anforderung)}, range raw 0..3, transfer-property=TRIGGERED-ON-CHANGE-WITHOUT-REPETITION  # Freilauf Informationssignal vom Motorsteuergerät zum Getriebesteuergerät. Das Motorsteuergerät kann über dieses Signal den Freilauf freigeben, verhindern bzw. explizit anfordern.
          signal MO_Krit_Heckobjekt_XIX_Motor_54_XIX_E3V_K2CANFD: start 81, 3 bit, little-endian, data-type-policy=OVERRIDE, i-signal-type=PRIMITIVE, init-value=0, base-type=BT_MO_Krit_Heckobjekt, invalid-value=Invalid_MO_Krit_Heckobjekt_XIX_Motor_54_XIX_E3V_K2CANFD:7, compu {0=Cx0_Init_kein_relevantes_Objekt (CM_MO_Krit_Heckobjekt_Cx0_Init_kein_relevantes_Objekt), 1=Cx1_Entfernung_grosser_Abstand (CM_MO_Krit_Heckobjekt_Cx1_Entfernung_grosser_Abstand), 2=Cx2_Annaeherung_grosser_Abstand (CM_MO_Krit_Heckobjekt_Cx2_Annaeherung_grosser_Abstand), 3=Cx3_Entfernung_geringer_Abstand (CM_MO_Krit_Heckobjekt_Cx3_Entfernung_geringer_Abstand), 4=Cx4_Annaeherung_geringer_Abstand (CM_MO_Krit_Heckobjekt_Cx4_Annaeherung_geringer_Abstand), 7=Cx7_Fehler (CM_MO_Krit_Heckobjekt_Cx7_Fehler)}, range raw 0..7, transfer-property=PENDING  # Beschreibt die Kritikalität des hinter einem in der Spur fahrenden Fahrzeuges
          signal MO_NGS_Gangpos_XIX_Motor_54_XIX_E3V_K2CANFD: start 84, 3 bit, little-endian, data-type-policy=OVERRIDE, i-signal-type=PRIMITIVE, init-value=0, base-type=BT_MO_NGS_Gangpos, invalid-value=Invalid_MO_NGS_Gangpos_XIX_Motor_54_XIX_E3V_K2CANFD:7, compu {0=Cx0_nicht_bedient (CM_MO_NGS_Gangpos_Cx0_nicht_bedient), 1=Cx1_1_3_oder_5 (CM_MO_NGS_Gangpos_Cx1_1_3_oder_5), 2=Cx2_2_4_6_oder_R (CM_MO_NGS_Gangpos_Cx2_2_4_6_oder_R), 3=Cx3_R (CM_MO_NGS_Gangpos_Cx3_R), 4=Cx4_Neutralposition (CM_MO_NGS_Gangpos_Cx4_Neutralposition), 5=Cx5_Zwischenposition (CM_MO_NGS_Gangpos_Cx5_Zwischenposition), 6=Cx6_Sensor_temp_nicht_verfuegbar (CM_MO_NGS_Gangpos_Cx6_Sensor_temp_nicht_verfuegbar), 7=Cx7_Fehler (CM_MO_NGS_Gangpos_Cx7_Fehler)}, range raw 0..7, transfer-property=TRIGGERED-ON-CHANGE-WITHOUT-REPETITION  # Gang- bzw. Neutralinformation des erweiterten Neutralgangsensors. Bedingt durch den eingeschränkten Erfassungssbereich des Sensors sind die Ganginformationen als eingelegt bzw. fast eingelegt/vorausgewählt zu interpretieren (nur Handschalter)
          signal MO_Freilauf_Status_XIX_Motor_54_XIX_E3V_K2CANFD: start 87, 3 bit, little-endian, data-type-policy=OVERRIDE, i-signal-type=PRIMITIVE, init-value=0, base-type=BT_MO_Freilauf_Status, invalid-value=Invalid_MO_Freilauf_Status_XIX_Motor_54_XIX_E3V_K2CANFD:7, compu {0=Cx0_Freilauf_inaktiv_aber_moeglich (CM_MO_Freilauf_Status_Cx0_Freilauf_inaktiv_aber_moeglich), 1=Cx1_Freilauf_aktiv (CM_MO_Freilauf_Status_Cx1_Freilauf_aktiv), 2=Cx2_Freilauf_nicht_moegl_1Verhinderer (CM_MO_Freilauf_Status_Cx2_Freilauf_nicht_moegl_1Verhinderer), 3=Cx3_Freilauf_nicht_moegl_gr_1Verhinderer (CM_MO_Freilauf_Status_Cx3_Freilauf_nicht_moegl_gr_1Verhinderer), 7=Cx7_Fehler (CM_MO_Freilauf_Status_Cx7_Fehler)}, range raw 0..7, transfer-property=TRIGGERED-ON-CHANGE-WITHOUT-REPETITION  # Freilauf-Status-Signal vom Frailauf-Master an aktive Freilauf-Teilnehmer. In diesem Signal zeigt der Freilauf-Master an, welchen aktuellen Status die Freilauf-Betriebsstrategie hat.
          signal MO_EBoost_verf_praed_XIX_Motor_54_XIX_E3V_K2CANFD: start 90, 2 bit, little-endian, data-type-policy=OVERRIDE, i-signal-type=PRIMITIVE, init-value=0, base-type=BT_MO_EBoost_verf_praed, compu {0=Cx0_Init_oder_nicht_verfuegbar (CM_MO_EBoost_verf_praed_Cx0_Init_oder_nicht_verfuegbar), 1=Cx1_EBoost_kurzzeit_verfuegbar (CM_MO_EBoost_verf_praed_Cx1_EBoost_kurzzeit_verfuegbar), 2=Cx2_EBoost_langzeit_verfuegbar (CM_MO_EBoost_verf_praed_Cx2_EBoost_langzeit_verfuegbar)}, range raw 0..2, transfer-property=PENDING  # Zeigt an, ob für eine im Projekt definierte Zeit (max. 10s) E-Boost in Höhe von EM1_maxPred_Moment verfügbar sein wird. 0 - Init_oder_nicht_verfügbar 1 - EBoost_kurzzeit_verfügbar (~3Sek.) 2 - EBoost_langzeit_verfügbar (~10Sek)
          signal MO_Heckspoiler_Anf_XIX_Motor_54_XIX_E3V_K2CANFD: start 92, 1 bit, little-endian, data-type-policy=OVERRIDE, i-signal-type=PRIMITIVE, init-value=0, base-type=BT_MO_Heckspoiler_Anf, compu {0=Cx0_nicht_angefordert (CM_MO_Heckspoiler_Anf_Cx0_nicht_angefordert), 1=Cx1_angefordert (CM_MO_Heckspoiler_Anf_Cx1_angefordert)}, range raw 0..1, transfer-property=PENDING  # Anforderung den Heckspoiler zur Ladeluft- bzw. Motorraumkühlung auszufahren.
          signal MO_eLaunch_verf_XIX_Motor_54_XIX_E3V_K2CANFD: start 93, 2 bit, little-endian, data-type-policy=OVERRIDE, i-signal-type=PRIMITIVE, init-value=0, base-type=BT_MO_eLaunch_verf, compu {0=Cx0_Init (CM_MO_eLaunch_verf_Cx0_Init), 1=Cx1_nicht_verfuegbar (CM_MO_eLaunch_verf_Cx1_nicht_verfuegbar), 2=Cx2_verfuegbar (CM_MO_eLaunch_verf_Cx2_verfuegbar)}, range raw 0..2, transfer-property=PENDING  # Zeigt an, ob aus Antriebssicht E-Launch verfügbar ist.
          signal MO_Positionierung_aktiv_XIX_Motor_54_XIX_E3V_K2CANFD: start 95, 1 bit, little-endian, data-type-policy=OVERRIDE, i-signal-type=PRIMITIVE, init-value=0, base-type=BT_MO_Positionierung_aktiv, compu {0=Cx0_keine_Positionierung_aktiv (CM_MO_Positionierung_aktiv_Cx0_keine_Positionierung_aktiv), 1=Cx1_Positionierung_aktiv (CM_MO_Positionierung_aktiv_Cx1_Positionierung_aktiv)}, range raw 0..1, transfer-property=PENDING  # Zeigt an, dass die Motorpositionierung mit Hilfe des Riemenstartergenerator momentan aktiv ist.
          signal MO_Startwunsch_XIX_Motor_54_XIX_E3V_K2CANFD: start 100, 1 bit, little-endian, data-type-policy=OVERRIDE, i-signal-type=PRIMITIVE, init-value=0, base-type=BT_MO_Startwunsch, compu {0=Cx0_kein_Startwunsch (CM_MO_Startwunsch_Cx0_kein_Startwunsch), 1=Cx1_Startwunsch (CM_MO_Startwunsch_Cx1_Startwunsch)}, range raw 0..1, transfer-property=TRIGGERED-ON-CHANGE-WITHOUT-REPETITION  # o Setzen bei Erfüllung der kompletten Fahrerbedienhandlung (z.B. Zündanlasstaster + Bremse + Fahrstufe P/N [klassisch] oder Fahrstufe D/R + Bremse [MEB]), je nach Fahrzeug z.T. bereits vor oder immer erst nach Einschalten der Klemme 15; o Rücksetzen bei Startausführung, bei Nichterfüllung der Startvoraussetzungen vor der Startausführung (z.B. Verlassen Bremspedal), bei Verhinderungsgrund (z.B. gesteckter Ladestecker, Diebstahlschutz) sowie bei Timeout (Ausbleiben von Freigabebedingungen, z.B. Klemme 15, WFS, Ladesteckerstatus etc.) o nie gesetzt bei konventionellem Start
          signal OBDProtocol_req_XIX_Motor_54_XIX_E3V_K2CANFD: start 112, 4 bit, little-endian, data-type-policy=OVERRIDE, i-signal-type=PRIMITIVE, base-type=BT_OBDProtocol_req, invalid-value=Invalid_OBDProtocol_req_XIX_Motor_54_XIX_E3V_K2CANFD:15, compu {0=Cx0_not_available (CM_OBDProtocol_req_Cx0_not_available), 1=Cx1_OBDclassic (CM_OBDProtocol_req_Cx1_OBDclassic), 2=Cx2_OBDonUDS (CM_OBDProtocol_req_Cx2_OBDonUDS), 3=Cx3_ZEVonUDS (CM_OBDProtocol_req_Cx3_ZEVonUDS), 14=Cxe_Init (CM_OBDProtocol_req_Cxe_Init), 15=Cxf_Fehler (CM_OBDProtocol_req_Cxf_Fehler)}, range raw 0..15, transfer-property=PENDING  # OBD protocol information 'used OBD protocol' from MIL master
          signal MO_Anforderung_Anzeige_Halten_XIX_Motor_54_XIX_E3V_K2CANFD: start 120, 1 bit, little-endian, data-type-policy=OVERRIDE, i-signal-type=PRIMITIVE, init-value=0, base-type=BT_MO_Anforderung_Anzeige_Halten, compu {0=Cx0_Keine_Anzeige_Halten (CM_MO_Anforderung_Anzeige_Halten_Cx0_Keine_Anzeige_Halten), 1=Cx1_Anzeige_Halten (CM_MO_Anforderung_Anzeige_Halten_Cx1_Anzeige_Halten)}, range raw 0..1, transfer-property=TRIGGERED-ON-CHANGE-WITHOUT-REPETITION  # Statusanzeige, ob "Hold"-Anzeige aktiv werden soll. Im Status Halten wird die "Hold" Anzeige aktiviert. Im Status Rückrollsicherung wird die "Hold" Anzeige nicht aktiviert.
          signal KVA_Ist_Pos_XIX_Motor_54_XIX_E3V_K2CANFD: start 121, 7 bit, little-endian, data-type-policy=OVERRIDE, i-signal-type=PRIMITIVE, init-value=126, base-type=BT_KVA_Ist_Pos, invalid-value=Invalid_KVA_Ist_Pos_XIX_Motor_54_XIX_E3V_K2CANFD:127, compu {phys=raw for raw 0..100, 125=Cx7d_SKE_nicht_verbaut (CM_KVA_Ist_Pos_Cx7d_SKE_nicht_verbaut), 126=Cx7e_Init (CM_KVA_Ist_Pos_Cx7e_Init), 127=Cx7f_Fehler (CM_KVA_Ist_Pos_Cx7f_Fehler); unit Unit_PerCent}, range phys 0..100 Unit_PerCent, raw 0..127, unit=Unit_PerCent, transfer-property=PENDING  # KVA Istpositionsrückmeldung
          signal OBD_Calc_Load_Val_XIX_Motor_54_XIX_E3V_K2CANFD: start 128, 8 bit, little-endian, data-type-policy=OVERRIDE, i-signal-type=PRIMITIVE, init-value=255, base-type=BT_OBD_Calc_Load_Val, compu {phys=raw*0.3921568627 for raw 0..255; unit Unit_PerCent}, range phys 0..100 Unit_PerCent, raw 0..255, unit=Unit_PerCent, transfer-property=PENDING  # Calculated Load Value Übertragung von Meßgrößen an das Getriebesteuergerät für Freeze Frame Abspeicherung bei Getriebefehlern PID $04 Calculated Load Value; 0 .. 100% mit 100/255 % per bit
          signal OBD_Eng_Cool_Temp_XIX_Motor_54_XIX_E3V_K2CANFD: start 136, 8 bit, little-endian, data-type-policy=OVERRIDE, i-signal-type=PRIMITIVE, init-value=255, base-type=BT_OBD_Eng_Cool_Temp, compu {phys=raw-40 for raw 0..255; unit Unit_DegreCelsi}, range phys -40..215 Unit_DegreCelsi, raw 0..255, unit=Unit_DegreCelsi, transfer-property=PENDING  # Engine Coolant Temperature Übertragung von Meßgrößen an das Getriebesteuergerät für Freeze Frame Abspeicherung bei Getriebefehlern PID $05 Engine Coolant Temperature; -40 .. +215°C mit 1°C/bit und 40°C Offset
          signal OBD_Abs_Throttle_Pos_XIX_Motor_54_XIX_E3V_K2CANFD: start 144, 8 bit, little-endian, data-type-policy=OVERRIDE, i-signal-type=PRIMITIVE, init-value=255, base-type=BT_OBD_Abs_Throttle_Pos, compu {phys=raw*0.3921568627 for raw 0..255; unit Unit_PerCent}, range phys 0..100 Unit_PerCent, raw 0..255, unit=Unit_PerCent, transfer-property=PENDING  # Absolute Throttle Position Übertragung von Meßgrößen an das Getriebesteuergerät für Freeze Frame Abspeicherung bei Getriebefehlern PID $11 Absolute Throttle Position; 0 .. 100% mit 100/255 %/bit
          signal OBD_Abs_Load_Val_XIX_Motor_54_XIX_E3V_K2CANFD: start 152, 16 bit, little-endian, data-type-policy=OVERRIDE, i-signal-type=PRIMITIVE, init-value=65535, base-type=BT_OBD_Abs_Load_Val, compu {phys=raw*0.3921568627 for raw 0..65535; unit Unit_PerCent}, range phys 0..25700 Unit_PerCent, raw 0..65535, unit=Unit_PerCent, transfer-property=PENDING  # Absolute Load Value Übertragung von Meßgrößen an das Getriebesteuergerät für Freeze Frame Abspeicherung bei Getriebefehlern PID $43 Absolute Load Value; 0 .. 25700% mit 100/255 %/bit
          signal OBD_Abs_Pedal_Pos_XIX_Motor_54_XIX_E3V_K2CANFD: start 168, 8 bit, little-endian, data-type-policy=OVERRIDE, i-signal-type=PRIMITIVE, init-value=255, base-type=BT_OBD_Abs_Pedal_Pos, compu {phys=raw*0.3921568627 for raw 0..255; unit Unit_PerCent}, range phys 0..100 Unit_PerCent, raw 0..255, unit=Unit_PerCent, transfer-property=PENDING  # Absolute Pedal Position Übertragung von Meßgrößen an das Getriebesteuergerät für Freeze Frame Abspeicherung bei Getriebefehlern PID $49 Accelerator Pedal Position D; 0 .. 100% mit 100/255 %/bit
          signal MO_Servicemodus_XIX_Motor_54_XIX_E3V_K2CANFD: start 176, 4 bit, little-endian, data-type-policy=OVERRIDE, i-signal-type=PRIMITIVE, init-value=0, base-type=BT_MO_Servicemodus, compu {0=Cx0_nicht_aktiv (CM_MO_Servicemodus_Cx0_nicht_aktiv), 1=Cx1_Service_Mode_1 (CM_MO_Servicemodus_Cx1_Service_Mode_1), 2=Cx2_Service_Mode_2 (CM_MO_Servicemodus_Cx2_Service_Mode_2), 3=Cx3_Service_Mode_3 (CM_MO_Servicemodus_Cx3_Service_Mode_3), 4=Cx4_Service_Mode_4 (CM_MO_Servicemodus_Cx4_Service_Mode_4), 5=Cx5_Service_Mode_5 (CM_MO_Servicemodus_Cx5_Service_Mode_5), 6=Cx6_Service_Mode_6 (CM_MO_Servicemodus_Cx6_Service_Mode_6), 7=Cx7_Service_Mode_7 (CM_MO_Servicemodus_Cx7_Service_Mode_7), 8=Cx8_Service_Mode_8 (CM_MO_Servicemodus_Cx8_Service_Mode_8), 9=Cx9_Service_Mode_9 (CM_MO_Servicemodus_Cx9_Service_Mode_9), 10=Cxa_Service_Mode_10 (CM_MO_Servicemodus_Cxa_Service_Mode_10), 11=Cxb_Service_Mode_11 (CM_MO_Servicemodus_Cxb_Service_Mode_11), 12=Cxc_Service_Mode_12 (CM_MO_Servicemodus_Cxc_Service_Mode_12), 13=Cxd_Service_Mode_13 (CM_MO_Servicemodus_Cxd_Service_Mode_13), 14=Cxe_Service_Mode_14 (CM_MO_Servicemodus_Cxe_Service_Mode_14), 15=Cxf_Service_Mode_15 (CM_MO_Servicemodus_Cxf_Service_Mode_15)}, range raw 0..15, transfer-property=PENDING  # Ausgabe aktiver Service-Mode
          signal MO_FoD_Performance_Status_XIX_Motor_54_XIX_E3V_K2CANFD: start 181, 2 bit, little-endian, data-type-policy=OVERRIDE, i-signal-type=PRIMITIVE, init-value=0, base-type=BT_MO_FoD_Performance_Status, compu {0=Cx0_init (CM_MO_FoD_Performance_Status_Cx0_init), 1=Cx1_notPossible (CM_MO_FoD_Performance_Status_Cx1_notPossible), 2=Cx2_notActivated (CM_MO_FoD_Performance_Status_Cx2_notActivated), 3=Cx3_activated (CM_MO_FoD_Performance_Status_Cx3_activated)}, range raw 0..3, transfer-property=TRIGGERED-ON-CHANGE-WITHOUT-REPETITION  # Aktueller Fahrzeug Performanceupgrade Status
          signal OBD_ClearMem_Inhibit_XIX_Motor_54_XIX_E3V_K2CANFD: start 183, 1 bit, little-endian, data-type-policy=OVERRIDE, i-signal-type=PRIMITIVE, init-value=0, base-type=BT_OBD_ClearMem_Inhibit, compu {0=Cx0_FSP_Loeschen_zulaessig (CM_OBD_ClearMem_Inhibit_Cx0_FSP_Loeschen_zulaessig), 1=Cx1_FSP_Loeschen_nicht_zulaessig (CM_OBD_ClearMem_Inhibit_Cx1_FSP_Loeschen_nicht_zulaessig)}, range raw 0..1, transfer-property=PENDING  # Bei FSP_Loeschen_zulässig müssen alle OBD-ECUs im Gesamtfahrzeug einen Service 04hex Request (Ereignisspeicher löschen) korrekt ausführen. In MLB-, MLBevo-, MQB-Fahrzeugkonzepten muss der MIL-Master/Motorsteuergerät bei Kl.15 ein, projektabhängig, konstant OBD_ClearMem_Inhibit = 0 senden, sofern das Löschen des Ereignisspeichers noch in jedem Betriebszustand (auch bei laufendem Motor, etc.) gefordert ist. Projektspezifisch im MLB-, MLBevo-, und MQB-Fahrzeugkonzepten und vollumfänglich in MQB_37W- und MLB3-Fahrzeugkonzepten wird das Ereignisspeicher löschen in allen OBD-ECUs auf den Betriebszustand stehendes Fahrzeug und stehender Motor beschränkt und die entsprechende Freigabe das Ereignisspeicher Löschens vom MIL-Master über das Bussignal OBD_ClearMem_Inhibit für alle anderen OBD-ECUs im Gesamtfahrzeug signalisiert. Hinweis: Steuergerät- oder Komponentenspezifische Randbedingungen sind unter Abhängigkeit des Sicherheitskonzepts zu prüfen und zu bewerten.
          signal OBD_Sperrung_Kaltstart_Denom_XIX_Motor_54_XIX_E3V_K2CANFD: start 184, 1 bit, little-endian, data-type-policy=OVERRIDE, i-signal-type=PRIMITIVE, init-value=0, base-type=BT_OBD_Sperrung_Kaltstart_Denom, compu {0=Cx0_EVAP_Berechnung_freigegeben (CM_OBD_Sperrung_Kaltstart_Denom_Cx0_EVAP_Berechnung_freigegeben), 1=Cx1_EVAP_Berechnung_gesperrt (CM_OBD_Sperrung_Kaltstart_Denom_Cx1_EVAP_Berechnung_gesperrt)}, range raw 0..1, transfer-property=PENDING  # Information vom MIL Master, dass die Bildung des EVAP Denominators im Motor nicht möglich ist und damit der noECM-Denominator gesperrt werden darf.
          signal MO_QBit_Aussen_Temp_XIX_Motor_54_XIX_E3V_K2CANFD: start 185, 1 bit, little-endian, data-type-policy=OVERRIDE, i-signal-type=PRIMITIVE, init-value=1, base-type=BT_MO_QBit_Aussen_Temp, compu {0=Cx0_gueltiger_Wert (CM_MO_QBit_Aussen_Temp_Cx0_gueltiger_Wert), 1=Cx1_Ersatz_Init_oder_Fehlerwert (CM_MO_QBit_Aussen_Temp_Cx1_Ersatz_Init_oder_Fehlerwert)}, range raw 0..1, transfer-property=PENDING  # QBit der Aussentemperatur. Gesetzt bei Ersatzwert, Init oder Fehler.
          signal OBD_Sperrung_IUMPR_XIX_Motor_54_XIX_E3V_K2CANFD: start 186, 1 bit, little-endian, data-type-policy=OVERRIDE, i-signal-type=PRIMITIVE, init-value=0, base-type=BT_OBD_Sperrung_IUMPR, compu {0=Cx0_IUMPR_Berechnung_freigegeben (CM_OBD_Sperrung_IUMPR_Cx0_IUMPR_Berechnung_freigegeben), 1=Cx1_IUMPR_Berechnung_gesperrt (CM_OBD_Sperrung_IUMPR_Cx1_IUMPR_Berechnung_gesperrt)}, range raw 0..1, transfer-property=PENDING  # Wenn der General Denominator auf Grund eines Fehlers in den Eingangsgrößen gesperrt wird, wird diese Information über Bussystem als OBD-Statusinformation OBD_Sperrung_IUMPR für andere OBD-Steuergeräte bereitgestellt. Das MSG (MIL-Master) setzt dieses Bit, wenn auf Grund vorliegender Sperrbedingungen keine Inkrementierung des GeneralDenominator mehr stattfindet. Im Empfänger-SG ist entsprechend die Inkrementierung des oder der Numeratoren einzufrieren.
          signal OBD_Kaltstart_Denominator_XIX_Motor_54_XIX_E3V_K2CANFD: start 187, 1 bit, little-endian, data-type-policy=OVERRIDE, i-signal-type=PRIMITIVE, init-value=0, base-type=BT_OBD_Kaltstart_Denominator, compu {0=Cx0_Denominator_nicht_hochzaehlen (CM_OBD_Kaltstart_Denominator_Cx0_Denominator_nicht_hochzaehlen), 1=Cx1_Bedingungen_zum_Inkr_des_Kaltstart_Denom_erf (CM_OBD_Kaltstart_Denominator_Cx1_Bedingungen_zum_Inkr_des_Kaltstart_Denom_erf)}, range raw 0..1, transfer-property=PENDING  # Bestimmte Diagnosen werden nur unter Kaltstartbedingungen durchgeführt, der entsprechende Denominator bei IUMPR-pflichtigen Systemen wird anhand dieses vom MSG gebildeten Signals inkrementiert. (Entspricht EVAP-Denominator)
          signal OBD_Minimum_Trip_XIX_Motor_54_XIX_E3V_K2CANFD: start 188, 1 bit, little-endian, data-type-policy=OVERRIDE, i-signal-type=PRIMITIVE, init-value=0, base-type=BT_OBD_Minimum_Trip, compu {0=Cx0_kein_Min_Normed_Trip (CM_OBD_Minimum_Trip_Cx0_kein_Min_Normed_Trip), 1=Cx1_Min_Normed_Trip (CM_OBD_Minimum_Trip_Cx1_Min_Normed_Trip)}, range raw 0..1, transfer-property=PENDING  # Grundlage OBD-Gesetz CCR 1968.2 (d)(4.3) Denominator Specifications Bildung des General Denominator "Normed Trip": 600 sec. (kumulativ) Zeit nach Motorstart 300 sec. (kumulativ) mit Fahrzeuggeschwindigkeit > 25 mph (40 km/h) 30 sec. (kontinuierlich) Leerlauf Wenn alle diese Bedingungen erfüllt wurden ist ein OBD_Min_Normed_Trip erfüllt
          signal OBD_Driving_Cycle_XIX_Motor_54_XIX_E3V_K2CANFD: start 189, 1 bit, little-endian, data-type-policy=OVERRIDE, i-signal-type=PRIMITIVE, init-value=0, base-type=BT_OBD_Driving_Cycle, compu {0=Cx0_kein_Driving_Cycle_erkannt (CM_OBD_Driving_Cycle_Cx0_kein_Driving_Cycle_erkannt), 1=Cx1_Driving_Cycle_erkannt (CM_OBD_Driving_Cycle_Cx1_Driving_Cycle_erkannt)}, range raw 0..1, transfer-property=PENDING, to SAM(timeout 1 s)  # Signalisierung Driving Cycle Qualifizierung - Trigger Ignition Cycle Counter
          signal OBD_Warm_Up_Cycle_XIX_Motor_54_XIX_E3V_K2CANFD: start 190, 1 bit, little-endian, data-type-policy=OVERRIDE, i-signal-type=PRIMITIVE, init-value=0, base-type=BT_OBD_Warm_Up_Cycle, compu {0=Cx0_kein_Warm_Up_Cycle_erkannt (CM_OBD_Warm_Up_Cycle_Cx0_kein_Warm_Up_Cycle_erkannt), 1=Cx1_Warm_Up_Cycle_erkannt (CM_OBD_Warm_Up_Cycle_Cx1_Warm_Up_Cycle_erkannt)}, range raw 0..1, transfer-property=PENDING, to SAM(timeout 1 s)  # Mit dem Warm-Up-Cycle wird der zentrale Verlernzähler vom Gateway inkrementiert
          signal OBD_Normed_Trip_XIX_Motor_54_XIX_E3V_K2CANFD: start 191, 1 bit, little-endian, data-type-policy=OVERRIDE, i-signal-type=PRIMITIVE, init-value=0, base-type=BT_OBD_Normed_Trip, compu {0=Cx0_kein_Normed_Trip (CM_OBD_Normed_Trip_Cx0_kein_Normed_Trip), 1=Cx1_Normed_Trip (CM_OBD_Normed_Trip_Cx1_Normed_Trip)}, range raw 0..1, transfer-property=PENDING  # Gesetzlich definierte "Normed Condition" erfüllt, "General Denominator" darf erhöht werden
          signal MO_FoD_Performance_Switch_Status_XIX_Motor_54_XIX_E3V_K2CANFD: start 234, 3 bit, little-endian, data-type-policy=OVERRIDE, i-signal-type=PRIMITIVE, init-value=0, base-type=BT_MO_FoD_Performance_Switch_Status, compu {0=Cx0_init (CM_MO_FoD_Performance_Switch_Status_Cx0_init), 1=Cx1_notActiv (CM_MO_FoD_Performance_Switch_Status_Cx1_notActiv), 2=Cx2_changeInProgress (CM_MO_FoD_Performance_Switch_Status_Cx2_changeInProgress), 3=Cx3_changeFailedRetryInNextClampCycl (CM_MO_FoD_Performance_Switch_Status_Cx3_changeFailedRetryInNextClampCycl), 4=Cx4_changeFailed (CM_MO_FoD_Performance_Switch_Status_Cx4_changeFailed)}, range raw 0..4, transfer-property=TRIGGERED-ON-CHANGE-WITHOUT-REPETITION  # Status zum Wechsel des Performance upgrades
          signal MO_UBE_Reserve_XIX_Motor_54_XIX_E3V_K2CANFD: start 238, 10 bit, little-endian, data-type-policy=OVERRIDE, i-signal-type=PRIMITIVE, init-value=1023, base-type=BT_MO_UBE_Reserve, compu {phys=raw*5 for raw 0..1022, 1023=Cx3ff_Init (CM_MO_UBE_Reserve_Cx3ff_Init); unit Unit_WattHour}, range phys 0..5110 Unit_WattHour, raw 0..1023, unit=Unit_WattHour, transfer-property=PENDING  # Seitens Antrieb erforderliche Energiereserve der HV-Batterie, die den Fußpunkt der „Usable Battery Energy“ (BMS_UBE) verschiebt. Die Reserve dient der Gewährleistung von Sicherheitsfunktionen und ggf. Emissionierungsmaßnahmen unterhalb des Fahrbetriebs im EV-Mode eines Hybridfahrzeuges bzw. dem regulären Fahrbetrieb eines Elektrofahrzeuges. Der Reservewert ist für eine Homologation (z.B. Interpolationsfamilie der WLTP Homologation) fest definiert.
          signal OBD_Aussen_Temp_gef_XIX_Motor_54_XIX_E3V_K2CANFD: start 248, 8 bit, little-endian, data-type-policy=OVERRIDE, i-signal-type=PRIMITIVE, init-value=254, base-type=BT_OBD_Aussen_Temp_gef, invalid-value=Invalid_OBD_Aussen_Temp_gef_XIX_Motor_54_XIX_E3V_K2CANFD:255, compu {phys=raw-40 for raw 0..253, 254=Cxfe_Initwert (CM_OBD_Aussen_Temp_gef_Cxfe_Initwert), 255=Cxff_Fehler (CM_OBD_Aussen_Temp_gef_Cxff_Fehler); unit Unit_DegreCelsi}, range phys -40..213 Unit_DegreCelsi, raw 0..255, unit=Unit_DegreCelsi, transfer-property=PENDING  # Gefilterte Aussentemperatur vom Motor für OBD Funktionen.
